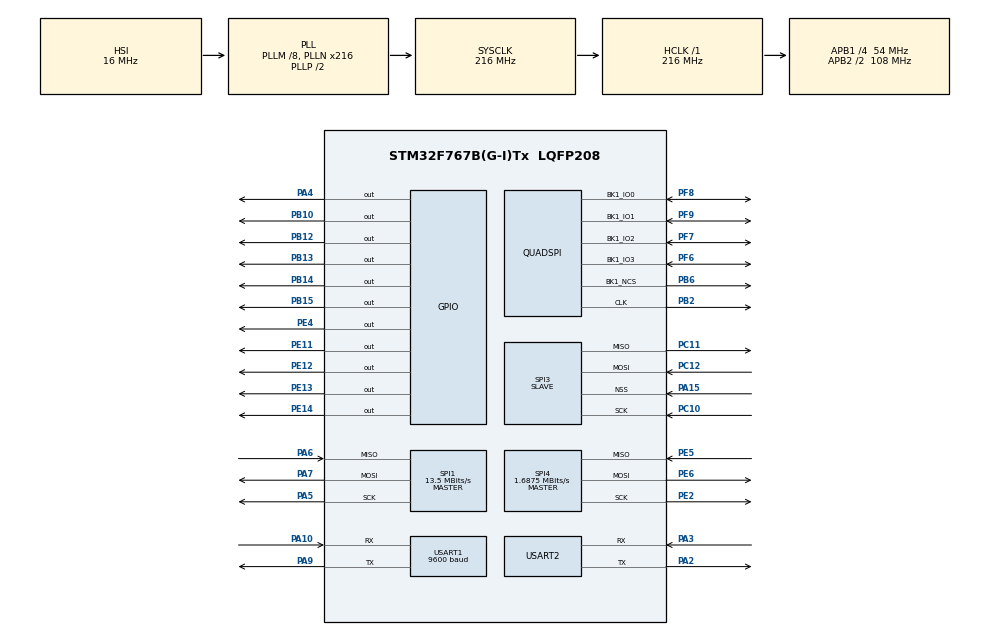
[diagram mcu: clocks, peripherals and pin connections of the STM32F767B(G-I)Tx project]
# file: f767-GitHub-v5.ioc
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CORTEX_M7.CPU_DCache=Enabled
CORTEX_M7.CPU_ICache=Enabled
Dma.Request0=USART1_RX
Dma.USART1_RX.0.Direction=DMA_PERIPH_TO_MEMORY
Dma.USART1_RX.0.FIFOMode=DMA_FIFOMODE_DISABLE
Dma.USART1_RX.0.Instance=DMA2_Stream5
Dma.USART1_RX.0.MemDataAlignment=DMA_MDATAALIGN_BYTE
Dma.USART1_RX.0.MemInc=DMA_MINC_ENABLE
Dma.USART1_RX.0.Mode=DMA_CIRCULAR
Dma.USART1_RX.0.PeriphDataAlignment=DMA_PDATAALIGN_BYTE
Dma.USART1_RX.0.PeriphInc=DMA_PINC_DISABLE
Dma.USART1_RX.0.Priority=DMA_PRIORITY_LOW
Mcu.Family=STM32F7
Mcu.Name=STM32F767B(G-I)Tx
Mcu.Package=LQFP208
NVIC.DMA2_Stream5_IRQn=true\:0\:0\:false\:false\:true\:false\:true\:true
NVIC.PriorityGroup=NVIC_PRIORITYGROUP_4
NVIC.USART1_IRQn=true\:0\:0\:false\:false\:true\:true\:true\:true
PA10.Mode=Asynchronous
PA10.Signal=USART1_RX
PA13.Mode=Serial_Wire
PA13.Signal=SYS_JTMS-SWDIO
PA14.Mode=Serial_Wire
PA14.Signal=SYS_JTCK-SWCLK
PA15.Mode=NSS_Signal_Hard_Input
PA15.Signal=SPI3_NSS
PA2.Mode=Asynchronous
PA2.Signal=USART2_TX
PA3.Mode=Asynchronous
PA3.Signal=USART2_RX
PA4.Signal=GPIO_Output
PA5.Mode=Full_Duplex_Master
PA5.Signal=SPI1_SCK
PA6.Mode=Full_Duplex_Master
PA6.Signal=SPI1_MISO
PA7.Mode=Full_Duplex_Master
PA7.Signal=SPI1_MOSI
PA9.Mode=Asynchronous
PA9.Signal=USART1_TX
PB10.Signal=GPIO_Output
PB12.Signal=GPIO_Output
PB13.Signal=GPIO_Output
PB14.Signal=GPIO_Output
PB15.Signal=GPIO_Output
PB2.Mode=Single Bank 1
PB2.Signal=QUADSPI_CLK
PB6.Mode=Single Bank 1
PB6.Signal=QUADSPI_BK1_NCS
PC10.Mode=Full_Duplex_Slave
PC10.Signal=SPI3_SCK
PC11.Mode=Full_Duplex_Slave
PC11.Signal=SPI3_MISO
PC12.Mode=Full_Duplex_Slave
PC12.Signal=SPI3_MOSI
PE11.Signal=GPIO_Output
PE12.Signal=GPIO_Output
PE13.Signal=GPIO_Output
PE14.Signal=GPIO_Output
PE2.Mode=Full_Duplex_Master
PE2.Signal=SPI4_SCK
PE4.Signal=GPIO_Output
PE5.Mode=Full_Duplex_Master
PE5.Signal=SPI4_MISO
PE6.Mode=Full_Duplex_Master
PE6.Signal=SPI4_MOSI
PF6.Mode=Single Bank 1
PF6.Signal=QUADSPI_BK1_IO3
PF7.Mode=Single Bank 1
PF7.Signal=QUADSPI_BK1_IO2
PF8.Mode=Single Bank 1
PF8.Signal=QUADSPI_BK1_IO0
PF9.Mode=Single Bank 1
PF9.Signal=QUADSPI_BK1_IO1
PH0/OSC_IN.Mode=HSE-External-Clock-Source
PH0/OSC_IN.Signal=RCC_OSC_IN
PH1/OSC_OUT.Mode=HSE-External-Clock-Source
PH1/OSC_OUT.Signal=RCC_OSC_OUT
ProjectManager.HeapSize=0x800
ProjectManager.StackSize=0x800
ProjectManager.TargetToolchain=STM32CubeIDE
RCC.AHBFreq_Value=216000000
RCC.APB1CLKDivider=RCC_HCLK_DIV4
RCC.APB1Freq_Value=54000000
RCC.APB1TimFreq_Value=108000000
RCC.APB2CLKDivider=RCC_HCLK_DIV2
RCC.APB2Freq_Value=108000000
RCC.APB2TimFreq_Value=216000000
RCC.CortexFreq_Value=216000000
RCC.HCLKFreq_Value=216000000
RCC.HSE_VALUE=8000000
RCC.HSI_VALUE=16000000
RCC.LSE_VALUE=32768
RCC.PLLM=8
RCC.PLLN=216
RCC.SYSCLKFreq_VALUE=216000000
RCC.SYSCLKSource=RCC_SYSCLKSOURCE_PLLCLK
RCC.USBFreq_Value=216000000
RCC.VCOOutputFreq_Value=432000000
SPI1.BaudRatePrescaler=SPI_BAUDRATEPRESCALER_8
SPI1.CalculateBaudRate=13.5 MBits/s
SPI1.DataSize=SPI_DATASIZE_8BIT
SPI1.Direction=SPI_DIRECTION_2LINES
SPI1.Mode=SPI_MODE_MASTER
SPI1.VirtualType=VM_MASTER
SPI3.Direction=SPI_DIRECTION_2LINES
SPI3.Mode=SPI_MODE_SLAVE
SPI3.VirtualNSS=VM_NSSHARD
SPI3.VirtualType=VM_SLAVE
SPI4.BaudRatePrescaler=SPI_BAUDRATEPRESCALER_64
SPI4.CalculateBaudRate=1.6875 MBits/s
SPI4.DataSize=SPI_DATASIZE_8BIT
SPI4.Direction=SPI_DIRECTION_2LINES
SPI4.Mode=SPI_MODE_MASTER
SPI4.VirtualType=VM_MASTER
STMicroelectronics.X-CUBE-AI.7.2.0.ActivationBufferSizeList=58432,128
STMicroelectronics.X-CUBE-AI.7.2.0.ActivationBuffers=pool0;pool0
STMicroelectronics.X-CUBE-AI.7.2.0.ActivationNames=pool0
STMicroelectronics.X-CUBE-AI.7.2.0.ActivationSizes=AI_NETWORK_DATA_ACTIVATION_1_SIZE
STMicroelectronics.X-CUBE-AI.7.2.0.HeapSize=0x800
STMicroelectronics.X-CUBE-AI.7.2.0.InternalRamActivationBufferMaxSize=AI_NETWORK_DATA_ACTIVATIONS_SIZE
STMicroelectronics.X-CUBE-AI.7.2.0.LatestDirectoryUsed-42ef4118f2b5a3766a18da1d4356868db262e7154a02415cbf3001b972654939=C\:\\Users\\yasir\\Documents
STMicroelectronics.X-CUBE-AI.7.2.0.LatestDirectoryUsed-c149c72ab2564b82c2436aeece4864a9ac483b8918643c00249937449eacca18=N\:\\BKB code\\ICU Code and Model\\ICU Code and Model
STMicroelectronics.X-CUBE-AI.7.2.0.MaximumNumberOfInputLayer=1
STMicroelectronics.X-CUBE-AI.7.2.0.MaximumNumberOfOutputLayer=1
STMicroelectronics.X-CUBE-AI.7.2.0.MaximumSizeOfInputLayer=1
STMicroelectronics.X-CUBE-AI.7.2.0.MaximumSizeOfOutputLayer=1
STMicroelectronics.X-CUBE-AI.7.2.0.ModelActualCompression-42ef4118f2b5a3766a18da1d4356868db262e7154a02415cbf3001b972654939=0.0
STMicroelectronics.X-CUBE-AI.7.2.0.ModelActualCompression-c149c72ab2564b82c2436aeece4864a9ac483b8918643c00249937449eacca18=0.0
STMicroelectronics.X-CUBE-AI.7.2.0.ModelCompression-42ef4118f2b5a3766a18da1d4356868db262e7154a02415cbf3001b972654939=None
STMicroelectronics.X-CUBE-AI.7.2.0.ModelCompression-c149c72ab2564b82c2436aeece4864a9ac483b8918643c00249937449eacca18=None
STMicroelectronics.X-CUBE-AI.7.2.0.ModelFlashOccupation-42ef4118f2b5a3766a18da1d4356868db262e7154a02415cbf3001b972654939=1284
STMicroelectronics.X-CUBE-AI.7.2.0.ModelFlashOccupation-c149c72ab2564b82c2436aeece4864a9ac483b8918643c00249937449eacca18=116
STMicroelectronics.X-CUBE-AI.7.2.0.ModelHashList=c149c72ab2564b82c2436aeece4864a9ac483b8918643c00249937449eacca18;42ef4118f2b5a3766a18da1d4356868db262e7154a02415cbf3001b972654939
STMicroelectronics.X-CUBE-AI.7.2.0.ModelKind-42ef4118f2b5a3766a18da1d4356868db262e7154a02415cbf3001b972654939=TFLITE
STMicroelectronics.X-CUBE-AI.7.2.0.ModelKind-c149c72ab2564b82c2436aeece4864a9ac483b8918643c00249937449eacca18=TFLITE
STMicroelectronics.X-CUBE-AI.7.2.0.ModelMacc-42ef4118f2b5a3766a18da1d4356868db262e7154a02415cbf3001b972654939=353
STMicroelectronics.X-CUBE-AI.7.2.0.ModelMacc-c149c72ab2564b82c2436aeece4864a9ac483b8918643c00249937449eacca18=422420
STMicroelectronics.X-CUBE-AI.7.2.0.ModelName-42ef4118f2b5a3766a18da1d4356868db262e7154a02415cbf3001b972654939=sine_model
STMicroelectronics.X-CUBE-AI.7.2.0.ModelName-c149c72ab2564b82c2436aeece4864a9ac483b8918643c00249937449eacca18=network
STMicroelectronics.X-CUBE-AI.7.2.0.ModelNameList=network,sine_model
STMicroelectronics.X-CUBE-AI.7.2.0.ModelRamOccupation-42ef4118f2b5a3766a18da1d4356868db262e7154a02415cbf3001b972654939=128
STMicroelectronics.X-CUBE-AI.7.2.0.ModelRamOccupation-c149c72ab2564b82c2436aeece4864a9ac483b8918643c00249937449eacca18=58432
STMicroelectronics.X-CUBE-AI.7.2.0.ModelStructureFile-42ef4118f2b5a3766a18da1d4356868db262e7154a02415cbf3001b972654939=C\:\\Users\\yasir\\Documents\\sine_model.tflite
STMicroelectronics.X-CUBE-AI.7.2.0.ModelStructureFile-c149c72ab2564b82c2436aeece4864a9ac483b8918643c00249937449eacca18=N\:\\BKB code\\ICU Code and Model\\ICU Code and Model\\MobileNetV2_Binary.tflite
STMicroelectronics.X-CUBE-AI.7.2.0.ModelType-42ef4118f2b5a3766a18da1d4356868db262e7154a02415cbf3001b972654939=STM32Cube.AI runtime
STMicroelectronics.X-CUBE-AI.7.2.0.ModelType-c149c72ab2564b82c2436aeece4864a9ac483b8918643c00249937449eacca18=STM32Cube.AI runtime
STMicroelectronics.X-CUBE-AI.7.2.0.ReadyForCodeGeneration=true
STMicroelectronics.X-CUBE-AI.7.2.0.StackSize=0x800
STMicroelectronics.X-CUBE-AI.7.2.0.WorkingBufferStartAddrList=0xFFFFFFFF,0xFFFFFFFF
STMicroelectronics.X-CUBE-AI.7.2.0.XAaCUBEAaAICcArtificialOoIntelligenceJjCore=true
TIM13.Prescaler=79
TIM14.Prescaler=79
USART1.BaudRate=9600
USART1.VirtualMode-Asynchronous=VM_ASYNC
USART2.VirtualMode-Asynchronous=VM_ASYNC
VP_CRC_VS_CRC.Mode=CRC_Activate
VP_STMicroelectronics.X-CUBE-AI_VS_ArtificialOoIntelligenceJjXAaCUBEAaAI_7.2.0.Mode=ArtificialOoIntelligenceJjXAaCUBEAaAI
VP_TIM13_VS_ClockSourceINT.Mode=Enable_Timer
VP_TIM14_VS_ClockSourceINT.Mode=Enable_Timer
board=custom

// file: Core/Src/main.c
/* USER CODE BEGIN Header */
/**
  ******************************************************************************
  * @file           : main.c
  * @brief          : Main program body
  ******************************************************************************
  * @attention
  *
  * <h2><center>&copy; Copyright (c) 2020 STMicroelectronics.
  * All rights reserved.</center></h2>
  *
  * This software component is licensed by ST under BSD 3-Clause license,
  * the "License"; You may not use this file except in compliance with the
  * License. You may obtain a copy of the License at:
  *                        opensource.org/licenses/BSD-3-Clause
  *
  ******************************************************************************
  */
/* USER CODE END Header */
#include "main.h"
#include "crc.h"
#include "dma.h"
#include "quadspi.h"
#include "spi.h"
#include "tim.h"
#include "usart.h"
#include "gpio.h"

/* USER CODE BEGIN Includes */
#include "ai_datatypes_defines.h"
#include "ai_platform.h"

#include "network_data.h"
#include "network.h"

#include "sine_model.h"
#include "sine_model_data.h"

#include <math.h>
#include "string.h"
#include <stdio.h>
#include <assert.h>

#include "w25qxx.h"
#include "w25qxxConf.h"

#include "..\\tjpg\\tjpgd.h"

/* USER CODE END Includes */

/* USER CODE BEGIN PD */
#define serialPortDebug huart1
#define serialPortCAM huart1
#define shrdPortFM hspi4
#define localPortFM hspi4

#define debugPort huart1
#define serialCAM huart3
#define N_BPP (3 - JD_FORMAT)

/* USER CODE END PD */

/* USER CODE BEGIN PM */

//#ifdef __GNUC__
//  #define PUTCHAR_PROTOTYPE int __io_putchar(int ch)
//#else
//  #define PUTCHAR_PROTOTYPE int fputc(int ch, FILE *f)
//#endif
//
//PUTCHAR_PROTOTYPE
//{
//  HAL_UART_Transmit(&serialPortDebug,(uint8_t *)&ch,1,0xFFFF);//Blocking mode printing
//  return ch;
//}

void write_3ByteAdd_FM(SPI_HandleTypeDef spiPort, uint32_t Addr, uint8_t writeDataByte);
//void write_3ByteAdd_FM(SPI_HandleTypeDef spiPort, uint32_t Addr);
int read_3ByteAdd_FM(SPI_HandleTypeDef spiPort, uint32_t Addr);
/* USER CODE END PM */

/* USER CODE BEGIN PV */

#if 1 /* FOLDED ARRAY */

////Earth 320x240
uint8_t Earth[16155] = {
		0xFF, 0xD8, 0xFF, 0xE0, 0x00, 0x10, 0x4A, 0x46, 0x49, 0x46, 0x00, 0x01, 0x01, 0x00, 0x00, 0x01,
		0x00, 0x01, 0x00, 0x00, 0xFF, 0xDB, 0x00, 0x43, 0x00, 0x08, 0x06, 0x06, 0x07, 0x06, 0x05, 0x08,
		0x07, 0x07, 0x07, 0x09, 0x09, 0x08, 0x0A, 0x0C, 0x14, 0x0D, 0x0C, 0x0B, 0x0B, 0x0C, 0x19, 0x12,
		0x13, 0x0F, 0x14, 0x1D, 0x1A, 0x1F, 0x1E, 0x1D, 0x1A, 0x1C, 0x1C, 0x20, 0x24, 0x2E, 0x27, 0x20,
		0x22, 0x2C, 0x23, 0x1C, 0x1C, 0x28, 0x37, 0x29, 0x2C, 0x30, 0x31, 0x34, 0x34, 0x34, 0x1F, 0x27,
		0x39, 0x3D, 0x38, 0x32, 0x3C, 0x2E, 0x33, 0x34, 0x32, 0xFF, 0xDB, 0x00, 0x43, 0x01, 0x09, 0x09,
		0x09, 0x0C, 0x0B, 0x0C, 0x18, 0x0D, 0x0D, 0x18, 0x32, 0x21, 0x1C, 0x21, 0x32, 0x32, 0x32, 0x32,
		0x32, 0x32, 0x32, 0x32, 0x32, 0x32, 0x32, 0x32, 0x32, 0x32, 0x32, 0x32, 0x32, 0x32, 0x32, 0x32,
		0x32, 0x32, 0x32, 0x32, 0x32, 0x32, 0x32, 0x32, 0x32, 0x32, 0x32, 0x32, 0x32, 0x32, 0x32, 0x32,
		0x32, 0x32, 0x32, 0x32, 0x32, 0x32, 0x32, 0x32, 0x32, 0x32, 0x32, 0x32, 0x32, 0x32, 0xFF, 0xC0,
		0x00, 0x11, 0x08, 0x00, 0xF0, 0x01, 0x40, 0x03, 0x01, 0x22, 0x00, 0x02, 0x11, 0x01, 0x03, 0x11,
		0x01, 0xFF, 0xC4, 0x00, 0x1C, 0x00, 0x00, 0x02, 0x02, 0x03, 0x01, 0x01, 0x00, 0x00, 0x00, 0x00,
		0x00, 0x00, 0x00, 0x00, 0x00, 0x00, 0x00, 0x05, 0x04, 0x06, 0x02, 0x03, 0x07, 0x01, 0x08, 0xFF,
		0xC4, 0x00, 0x42, 0x10, 0x00, 0x02, 0x01, 0x03, 0x03, 0x02, 0x05, 0x01, 0x05, 0x06, 0x05, 0x04,
		0x01, 0x02, 0x07, 0x00, 0x01, 0x02, 0x03, 0x00, 0x04, 0x11, 0x05, 0x12, 0x21, 0x31, 0x41, 0x06,
		0x13, 0x22, 0x51, 0x61, 0x71, 0x14, 0x32, 0x81, 0x91, 0xA1, 0x07, 0x15, 0x23, 0x42, 0xB1, 0xC1,
		0x33, 0x52, 0x62, 0xE1, 0xF0, 0x24, 0x72, 0xD1, 0xF1, 0x08, 0x43, 0x53, 0x16, 0x35, 0x63, 0x73,
		0x82, 0x92, 0xA2, 0xFF, 0xC4, 0x00, 0x19, 0x01, 0x00, 0x03, 0x01, 0x01, 0x01, 0x00, 0x00, 0x00,
		0x00, 0x00, 0x00, 0x00, 0x00, 0x00, 0x00, 0x00, 0x00, 0x02, 0x03, 0x01, 0x04, 0x05, 0xFF, 0xC4,
		0x00, 0x26, 0x11, 0x00, 0x02, 0x02, 0x02, 0x02, 0x01, 0x04, 0x02, 0x03, 0x01, 0x00, 0x00, 0x00,
		0x00, 0x00, 0x00, 0x00, 0x01, 0x02, 0x11, 0x03, 0x21, 0x12, 0x31, 0x41, 0x04, 0x13, 0x32, 0x61,
		0x22, 0x51, 0x23, 0x71, 0xC1, 0xF0, 0xFF, 0xDA, 0x00, 0x0C, 0x03, 0x01, 0x00, 0x02, 0x11, 0x03,
		0x11, 0x00, 0x3F, 0x00, 0xA6, 0x4E, 0xBC, 0x07, 0x03, 0x83, 0xD2, 0xA3, 0xC8, 0x86, 0x30, 0xC2,
		0x4C, 0xAB, 0x01, 0x90, 0xA4, 0x63, 0x34, 0xCE, 0xEA, 0xE2, 0x7B, 0xE4, 0x16, 0xE9, 0x24, 0x9F,
		0x67, 0xB6, 0x07, 0xC8, 0x87, 0x76, 0x55, 0x06, 0x79, 0xFC, 0x4E, 0x7A, 0xF7, 0xA5, 0x13, 0xAB,
		0xAB, 0x11, 0x20, 0x21, 0xBD, 0x8D, 0x6C, 0x49, 0x9A, 0x73, 0x8A, 0xCE, 0x39, 0xE4, 0x8C, 0x10,
		0x8C, 0x54, 0x1E, 0xB8, 0x3D, 0x6B, 0x58, 0x56, 0x3D, 0x14, 0x9A, 0xC7, 0x95, 0x24, 0x11, 0x83,
		0xED, 0x5A, 0xD2, 0x7D, 0x9A, 0x38, 0x86, 0xF8, 0xC5, 0x69, 0xB8, 0x4E, 0x18, 0x83, 0xF7, 0x08,
		0xEC, 0x7A, 0xD6, 0xA1, 0xA8, 0xB4, 0x84, 0x99, 0x10, 0x1F, 0x9C, 0x9A, 0x53, 0x8C, 0x77, 0xA0,
		0x31, 0x15, 0x2F, 0x66, 0x37, 0x63, 0x72, 0x97, 0x86, 0x3E, 0x4B, 0xE8, 0x98, 0xB3, 0x34, 0x5B,
		0x98, 0xF5, 0xEF, 0x5A, 0xF5, 0x16, 0xDF, 0x10, 0x23, 0x03, 0x8E, 0x98, 0xA5, 0x29, 0x3B, 0x29,
		0x38, 0xA9, 0x3F, 0x6B, 0xF3, 0x21, 0x28, 0xD8, 0xE0, 0x70, 0x6B, 0x16, 0x2A, 0x76, 0x64, 0xA7,
		0x29, 0x76, 0x46, 0x0E, 0x3B, 0xD6, 0xC8, 0x6E, 0x5E, 0x10, 0x55, 0x58, 0xED, 0x3D, 0xBD, 0xEA,
		0x19, 0x6E, 0x6B, 0xD0, 0xD5, 0xD1, 0x42, 0x8E, 0xAC, 0xEE, 0x37, 0x5D, 0x79, 0x92, 0x31, 0xE9,
		0x80, 0x33, 0xC0, 0xA7, 0x3E, 0x1F, 0xF1, 0x1C, 0xDE, 0x1A, 0xF1, 0x05, 0xB5, 0xFC, 0x6C, 0x1A,
		0x02, 0xDB, 0x65, 0x4C, 0xF0, 0xCA, 0x7A, 0xD5, 0x38, 0x4B, 0x9E, 0xF8, 0xAD, 0xE6, 0x5D, 0xC8,
		0xCA, 0x7A, 0x56, 0x3C, 0x49, 0xF6, 0x65, 0x9F, 0x52, 0x3E, 0xB9, 0x6F, 0x2E, 0x9C, 0xFA, 0x9D,
		0x95, 0xDC, 0x53, 0x40, 0x88, 0x92, 0xBC, 0x79, 0x19, 0x55, 0x3F, 0xD0, 0x9A, 0x61, 0xA5, 0xEA,
		0x31, 0xEA, 0x96, 0x29, 0x73, 0x10, 0x2A, 0x18, 0x72, 0xA7, 0xF9, 0x4F, 0x71, 0x5F, 0x33, 0xE8,
		0x7A, 0xED, 0xCD, 0x89, 0xB9, 0x89, 0x64, 0x3B, 0x6E, 0x20, 0x11, 0x3F, 0xB1, 0x5C, 0x8E, 0x3F,
		0x4A, 0xBB, 0x78, 0x53, 0xC7, 0xD7, 0x9A, 0x4D, 0xC1, 0xB3, 0xD4, 0x17, 0x7D, 0x9C, 0x98, 0x0B,
		0x2A, 0x0E, 0x63, 0xFF, 0x00, 0x56, 0x3A, 0x1F, 0x9A, 0xE7, 0xE1, 0x38, 0x49, 0xFE, 0x86, 0xF7,
		0x17, 0x47, 0x67, 0x8E, 0xD2, 0x28, 0xC3, 0x85, 0x51, 0xB5, 0xDB, 0x79, 0x5E, 0xC0, 0xFC, 0x57,
		0x24, 0xF1, 0x2F, 0x83, 0x6F, 0xA0, 0xBB, 0xBE, 0x6B, 0x38, 0x19, 0xAD, 0xC3, 0x17, 0x40, 0x06,
		0x70, 0xA7, 0xA7, 0xEB, 0xC5, 0x74, 0xBB, 0x3D, 0x4A, 0xE3, 0x7B, 0x35, 0xE2, 0x44, 0xB6, 0xF2,
		0x7A, 0xA0, 0x9D, 0x5B, 0xD2, 0xC0, 0xF4, 0x06, 0x9A, 0x6E, 0x57, 0x07, 0x69, 0x56, 0xEA, 0xBD,
		0x7B, 0xFB, 0x56, 0xAA, 0x7B, 0x43, 0x35, 0x67, 0xCB, 0x6A, 0x7C, 0xB7, 0x78, 0xE5, 0x0C, 0xAC,
		0x3D, 0xC6, 0x30, 0x6B, 0xC1, 0x21, 0x53, 0x8C, 0xFC, 0x83, 0x5D, 0x3B, 0xF6, 0x83, 0xE1, 0x60,
		0xF7, 0xB7, 0x9A, 0xAC, 0x50, 0x48, 0xA5, 0xB6, 0xE0, 0xA8, 0x04, 0x16, 0xC7, 0x3C, 0x7D, 0x2B,
		0x9A, 0xDC, 0x98, 0x25, 0x82, 0x37, 0x8C, 0x91, 0x38, 0xC2, 0xC9, 0x19, 0x1C, 0x93, 0xEE, 0x2B,
		0xAE, 0x0D, 0x4B, 0xA2, 0x4E, 0xD1, 0x62, 0xF0, 0xEF, 0x89, 0x6E, 0xB4, 0x5D, 0x45, 0x27, 0x49,
		0x5E, 0x48, 0x18, 0xFF, 0x00, 0x16, 0x2C, 0xE7, 0x7A, 0xF7, 0xC7, 0xCD, 0x5A, 0x6D, 0xBC, 0x5D,
		0xAA, 0xE9, 0xD7, 0x4E, 0xC9, 0x3B, 0xDD, 0x59, 0x23, 0x99, 0x12, 0x09, 0x10, 0x67, 0xC8, 0x3D,
		0x18, 0x30, 0xE4, 0xE3, 0x3C, 0xD7, 0x32, 0x85, 0xCB, 0x23, 0x0E, 0x3D, 0x3C, 0xD5, 0xDB, 0xC3,
		0xB2, 0xC3, 0x7D, 0x67, 0xF6, 0x3B, 0x89, 0x76, 0x1D, 0xDF, 0xC1, 0x99, 0x78, 0x68, 0x98, 0xFC,
		0xFB, 0x1E, 0x01, 0x1F, 0x35, 0x3C, 0x98, 0x62, 0xBF, 0x2A, 0x36, 0x33, 0x7D, 0x1D, 0x97, 0x4E,
		0xD4, 0x2D, 0xF5, 0x4B, 0x28, 0xEE, 0xAD, 0x9C, 0x32, 0x38, 0xCF, 0x5E, 0x47, 0xC1, 0xA9, 0x55,
		0xC4, 0xB4, 0x5F, 0x13, 0x5E, 0xF8, 0x37, 0x52, 0x36, 0xB3, 0x93, 0x3D, 0x89, 0x6C, 0x90, 0x07,
		0x63, 0xED, 0xED, 0xF4, 0xAE, 0xD3, 0x04, 0xF1, 0xDC, 0xDB, 0xC7, 0x3C, 0x4D, 0xBA, 0x39, 0x14,
		0x3A, 0x9F, 0x70, 0x7A, 0x52, 0x34, 0xE3, 0xA6, 0x3C, 0x5D, 0xA3, 0x65, 0x25, 0xD4, 0xB4, 0x90,
		0xF7, 0xD1, 0xEA, 0x36, 0xEA, 0x3C, 0xF4, 0x52, 0x8E, 0xB8, 0xE2, 0x55, 0x3D, 0x41, 0xFF, 0x00,
		0x9E, 0xD4, 0xEA, 0x8A, 0x0D, 0x6A, 0xCF, 0x9D, 0x7F, 0x6C, 0x1E, 0x11, 0x16, 0xEA, 0x2F, 0x2D,
		0x63, 0x6F, 0x24, 0x2E, 0xF8, 0xDB, 0xDD, 0x7B, 0x8F, 0xC2, 0xB8, 0x7D, 0x7D, 0xB9, 0xE2, 0x3D,
		0x09, 0x35, 0xBD, 0x22, 0xE6, 0xCE, 0x40, 0x08, 0x23, 0x7C, 0x5C, 0x74, 0x3D, 0xC5, 0x7C, 0x71,
		0xAF, 0x69, 0xAF, 0xA5, 0x6B, 0x17, 0x16, 0xCC, 0xA4, 0x00, 0xC7, 0x6F, 0xD2, 0xBA, 0x66, 0xFD,
		0xDC, 0x6A, 0x7E, 0x56, 0x9F, 0xF8, 0x47, 0x1A, 0xE1, 0x37, 0x0F, 0x0F, 0x6B, 0xFD, 0x15, 0x51,
		0x45, 0x15, 0xCC, 0x5C, 0x28, 0xA2, 0x8A, 0x00, 0x28, 0xA2, 0x8A, 0x00, 0x28, 0xA2, 0x8A, 0x00,
		0x28, 0xA2, 0x8A, 0x00, 0x28, 0xA2, 0x8A, 0x00, 0x28, 0xA2, 0x8A, 0x00, 0xED, 0x9A, 0x2A, 0x0B,
		0x40, 0xB7, 0x13, 0xC7, 0x6A, 0xD1, 0x24, 0x6D, 0x2E, 0xF2, 0xE7, 0x72, 0x1E, 0x80, 0x15, 0xFF,
		0x00, 0x36, 0x46, 0x07, 0xD6, 0x91, 0x5C, 0x0F, 0xB7, 0xCE, 0xD3, 0x13, 0x83, 0xD3, 0x0D, 0xC6,
		0xEC, 0x0F, 0x7A, 0x99, 0x7C, 0x27, 0xB0, 0x09, 0x6B, 0x23, 0x44, 0x26, 0x4C, 0xAB, 0xAA, 0xB8,
		0x6E, 0x3A, 0x8E, 0x47, 0x6E, 0x7D, 0xFD, 0xEB, 0x38, 0x88, 0xFB, 0x2E, 0xF6, 0x43, 0xB5, 0xB2,
		0x3D, 0x39, 0xC0, 0x38, 0xC7, 0xF4, 0x39, 0xF7, 0xE2, 0x95, 0x7E, 0xC9, 0xA1, 0x7D, 0xC5, 0xFC,
		0x90, 0xDB, 0x1B, 0x54, 0x60, 0x22, 0x38, 0x65, 0x8E, 0x33, 0x84, 0x07, 0xB9, 0x60, 0x73, 0x96,
		0x38, 0x14, 0x99, 0xD8, 0x96, 0x2C, 0x7A, 0x93, 0x4E, 0xB5, 0x38, 0xFC, 0xB7, 0x18, 0xCB, 0x45,
		0x22, 0x83, 0x1B, 0xB6, 0x37, 0x1E, 0x39, 0xC8, 0x19, 0xEF, 0x59, 0x5A, 0x68, 0x22, 0x60, 0xF7,
		0xD3, 0x3E, 0xDD, 0x22, 0x39, 0x0C, 0x6D, 0x74, 0x58, 0x28, 0x24, 0x2E, 0xED, 0xA0, 0x1E, 0x77,
		0x11, 0x9C, 0x0C, 0x73, 0x55, 0x5D, 0x1A, 0x21, 0x66, 0x2C, 0x49, 0x38, 0xFC, 0x2B, 0x10, 0x7A,
		0xD4, 0xAD, 0x4E, 0xE6, 0x3B, 0xAB, 0xF9, 0x5E, 0x04, 0x0B, 0x00, 0x3B, 0x62, 0x01, 0x02, 0x9D,
		0xA3, 0x80, 0x48, 0xF7, 0x23, 0x93, 0xF5, 0xA8, 0x24, 0xF3, 0x5A, 0x61, 0x96, 0x73, 0x40, 0x6C,
		0x56, 0xBC, 0xD0, 0x4D, 0x6D, 0x01, 0x99, 0x35, 0x86, 0x71, 0x5E, 0x67, 0x15, 0xE6, 0x69, 0x90,
		0xA6, 0x5B, 0xB1, 0x59, 0xAB, 0xD6, 0x8C, 0xD7, 0xA2, 0x98, 0x52, 0x64, 0x32, 0x6D, 0x60, 0x6A,
		0xCB, 0xA7, 0xDC, 0xAD, 0xCC, 0x06, 0x26, 0x03, 0x7A, 0xFD, 0xC2, 0x7F, 0xA5, 0x56, 0x2D, 0x86,
		0x4D, 0x38, 0xB0, 0x04, 0x49, 0xED, 0x8E, 0x71, 0x9A, 0xC9, 0x2B, 0x42, 0xBD, 0x96, 0x9B, 0x2F,
		0x15, 0x6B, 0x9A, 0x10, 0x10, 0x6E, 0xF3, 0xEC, 0x59, 0x58, 0x0B, 0x79, 0xBD, 0x68, 0x41, 0xFE,
		0x98, 0xED, 0x56, 0x7D, 0x37, 0xF6, 0x9D, 0x32, 0xAC, 0x6D, 0x2D, 0xBA, 0x46, 0xCD, 0x72, 0x86,
		0xE5, 0xB6, 0xFA, 0x76, 0x63, 0x04, 0xA8, 0xF7, 0xE9, 0xF9, 0x55, 0x2A, 0xD6, 0x52, 0xDB, 0x95,
		0x86, 0x46, 0x3A, 0x7B, 0x54, 0x0B, 0x97, 0x11, 0x40, 0x8B, 0xB7, 0xD4, 0x1C, 0x91, 0x8E, 0xA0,
		0xFB, 0xD7, 0x2F, 0x15, 0xD7, 0x90, 0x8C, 0xE4, 0x7D, 0x1D, 0x79, 0xF6, 0x4D, 0x7F, 0x40, 0x95,
		0x95, 0x81, 0x86, 0x44, 0x2C, 0x8F, 0xFE, 0x52, 0x3A, 0x37, 0xC5, 0x70, 0x4D, 0x5E, 0xD6, 0xF3,
		0x40, 0xD7, 0x8C, 0xD1, 0x0C, 0x5C, 0x5A, 0xCA, 0x92, 0xAF, 0x70, 0x47, 0x0C, 0x2A, 0xC3, 0xE0,
		0xAF, 0xDA, 0x3D, 0xA6, 0x97, 0x66, 0xDA, 0x66, 0xB1, 0x14, 0x92, 0x44, 0xEC, 0x06, 0xE8, 0xC6,
		0x40, 0x07, 0xA9, 0x23, 0xFF, 0x00, 0x15, 0x7C, 0xD6, 0xFC, 0x33, 0xA7, 0x78, 0xA7, 0x4D, 0x4B,
		0xCD, 0x2A, 0x58, 0x5A, 0x56, 0x41, 0xE5, 0xC8, 0x1B, 0x2A, 0xE8, 0x38, 0x03, 0xE3, 0x8A, 0x6C,
		0x53, 0xE2, 0xEA, 0x45, 0x64, 0xB9, 0x23, 0x87, 0xEA, 0x13, 0x09, 0x75, 0x39, 0x6E, 0x12, 0x34,
		0x88, 0x4A, 0xDE, 0x60, 0x44, 0x1C, 0x0C, 0xF3, 0xC5, 0x6E, 0xB4, 0xBC, 0xFB, 0x24, 0xAD, 0xB9,
		0x0B, 0x21, 0xC6, 0x46, 0x71, 0x53, 0x75, 0xFF, 0x00, 0x0E, 0xDF, 0xE9, 0x2E, 0x12, 0xEA, 0x32,
		0xBB, 0x77, 0x20, 0x6F, 0xA7, 0x20, 0x7E, 0x46, 0x92, 0x89, 0x37, 0xC7, 0x2B, 0x49, 0xF7, 0xD7,
		0x9F, 0xC2, 0xBB, 0xD2, 0x52, 0x47, 0x33, 0x93, 0x4C, 0xBD, 0xDD, 0x5C, 0xD9, 0xEB, 0xDA, 0x6B,
		0xCA, 0x87, 0xFE, 0xB6, 0x22, 0xAC, 0x30, 0x3E, 0xFA, 0x91, 0x87, 0xE3, 0xDF, 0x20, 0x1A, 0x95,
		0xE0, 0xAF, 0x12, 0xC9, 0xA0, 0x6A, 0xEB, 0xA7, 0x4F, 0x2C, 0xB3, 0xE9, 0xD7, 0x67, 0xD3, 0xB8,
		0xE7, 0xC9, 0x7C, 0x76, 0xCF, 0x6A, 0xA6, 0x25, 0xD3, 0xD9, 0x5F, 0x33, 0x5A, 0x31, 0x45, 0x0C,
		0x0A, 0x12, 0x79, 0xE9, 0x57, 0x04, 0xB5, 0x87, 0x55, 0xD3, 0x66, 0xBB, 0x8D, 0xE1, 0x12, 0x1C,
		0x48, 0xD1, 0xA8, 0xC1, 0x8E, 0x40, 0x79, 0x2B, 0xF0, 0x7A, 0xFC, 0x66, 0xA3, 0x28, 0x25, 0x1A,
		0x63, 0xC7, 0x25, 0xBD, 0x1D, 0xA4, 0x1C, 0x8E, 0x2B, 0xCA, 0xA9, 0x78, 0x0F, 0x51, 0xB8, 0xB9,
		0xD2, 0xDE, 0xD2, 0xE1, 0xCB, 0xB5, 0xB9, 0xDA, 0x8C, 0xDF, 0x7B, 0x6F, 0xB1, 0xF7, 0xC5, 0x5B,
		0x49, 0x0A, 0x09, 0x3D, 0x05, 0x73, 0x1D, 0x49, 0xDA, 0xB0, 0xAF, 0x9C, 0xBF, 0x6D, 0xDE, 0x12,
		0x6B, 0x3B, 0xCF, 0xDE, 0xB0, 0xA8, 0x31, 0xBB, 0x64, 0xE0, 0x74, 0x07, 0xFD, 0xF3, 0x5F, 0x46,
		0x02, 0x18, 0x64, 0x10, 0x41, 0x19, 0x04, 0x77, 0xA4, 0x7E, 0x2B, 0xF0, 0xFC, 0x5E, 0x25, 0xD0,
		0xEE, 0x34, 0xF9, 0x00, 0x0D, 0x22, 0x15, 0x56, 0xF6, 0x3D, 0xBF, 0x5C, 0x55, 0xB0, 0x4D, 0x45,
		0xB8, 0xCB, 0xA7, 0xA2, 0x79, 0x63, 0x69, 0x49, 0x76, 0x8F, 0x88, 0xE8, 0xA9, 0x9A, 0x8D, 0x94,
		0x9A, 0x76, 0xA1, 0x3D, 0xA4, 0xCA, 0x56, 0x48, 0x9C, 0xA3, 0x02, 0x3A, 0x10, 0x6A, 0x1D, 0x4A,
		0x51, 0xE2, 0xE9, 0x94, 0x4E, 0xD5, 0xA0, 0xA2, 0x8A, 0x2B, 0x0D, 0x0A, 0x28, 0xA2, 0x80, 0x0A,
		0x28, 0xA2, 0x80, 0x0A, 0x28, 0xA2, 0x80, 0x0A, 0x28, 0xA2, 0x80, 0x0A, 0x28, 0xA2, 0x80, 0x3A,
		0x64, 0x8D, 0xE6, 0x42, 0x80, 0x81, 0xBA, 0x30, 0x59, 0xB7, 0x0C, 0x12, 0x4F, 0x6E, 0x9F, 0xF3,
		0x35, 0x36, 0xD6, 0xE4, 0x47, 0x16, 0x19, 0x72, 0x82, 0x2C, 0xEE, 0x04, 0x67, 0x39, 0xE0, 0x8C,
		0xF5, 0x3F, 0x1E, 0xD9, 0xA5, 0x49, 0x80, 0x51, 0x4E, 0x43, 0x1E, 0x7E, 0xBE, 0xC3, 0x9E, 0x94,
		0xCA, 0x46, 0x1E, 0x98, 0xE5, 0x05, 0x43, 0x1D, 0xAD, 0x9C, 0xE1, 0x47, 0x03, 0xAE, 0x72, 0x70,
		0x4F, 0xCF, 0xF5, 0xA6, 0x11, 0x1E, 0xCC, 0xA9, 0x34, 0xD1, 0x23, 0x49, 0x1A, 0x99, 0xD1, 0x19,
		0x9B, 0x61, 0xC4, 0x59, 0x3C, 0x8C, 0x01, 0xD8, 0x0C, 0xF7, 0xA8, 0x3A, 0xC5, 0xD1, 0xBC, 0x9A,
		0x28, 0xED, 0xE3, 0x8D, 0x20, 0x40, 0x22, 0x8D, 0x62, 0x8F, 0x60, 0x72, 0x38, 0xDD, 0xF2, 0x4F,
		0x5C, 0xF5, 0xE7, 0x9A, 0x74, 0xF1, 0x5C, 0xF8, 0x8B, 0x59, 0xE1, 0x91, 0x5A, 0xE2, 0x78, 0xE2,
		0x88, 0x96, 0x0B, 0xE5, 0x46, 0xA9, 0xD4, 0x02, 0x78, 0xF4, 0x2E, 0x73, 0xDA, 0xA2, 0x69, 0xD7,
		0x10, 0x4B, 0x7D, 0x14, 0x73, 0x21, 0x7D, 0x23, 0x4E, 0x69, 0xAE, 0x38, 0x24, 0x19, 0x39, 0xE1,
		0x89, 0x53, 0xD4, 0xE1, 0x06, 0x46, 0x3A, 0xD3, 0xA4, 0x8C, 0x14, 0xEB, 0x7A, 0x59, 0xD1, 0xF5,
		0x59, 0xAC, 0x1E, 0x42, 0xCF, 0x00, 0x45, 0x97, 0xD1, 0x8D, 0x8E, 0x54, 0x16, 0x53, 0xC9, 0xCE,
		0x09, 0xC6, 0x7B, 0xD2, 0xCB, 0xA7, 0x12, 0xC8, 0x19, 0x54, 0x2A, 0xED, 0x00, 0x00, 0x00, 0xE8,
		0x31, 0xDA, 0x9F, 0xC9, 0x70, 0x75, 0x7B, 0xFD, 0x53, 0x59, 0xD5, 0x1C, 0xDB, 0x8B, 0xA8, 0xE6,
		0x95, 0x76, 0xA6, 0x43, 0xCB, 0xC6, 0x10, 0x67, 0xEA, 0x39, 0xA4, 0x30, 0xC6, 0xCC, 0x64, 0x3E,
		0x90, 0x11, 0x72, 0x73, 0xD4, 0x0F, 0x70, 0x28, 0x02, 0x3E, 0x6B, 0x1D, 0xD5, 0xE1, 0xE1, 0x8D,
		0x18, 0x24, 0x64, 0x0E, 0x95, 0xA6, 0x1E, 0xE6, 0xB1, 0xCD, 0x15, 0xE5, 0x30, 0xAC, 0xCA, 0xBD,
		0x03, 0x24, 0x56, 0x51, 0xA1, 0x90, 0x0D, 0xA0, 0x9C, 0x75, 0xC5, 0x78, 0x38, 0xE0, 0x0C, 0xE2,
		0x98, 0x41, 0xAE, 0x98, 0xB1, 0x82, 0x43, 0xF7, 0x18, 0x07, 0xE6, 0x98, 0xDA, 0xB7, 0x97, 0x7C,
		0xA3, 0x86, 0x04, 0x72, 0x69, 0x35, 0xA0, 0x77, 0xE4, 0xE7, 0x19, 0xC8, 0x20, 0x74, 0xA7, 0xD6,
		0x56, 0x8D, 0x34, 0x1E, 0x72, 0x24, 0xBE, 0x60, 0xF5, 0x06, 0xD9, 0xB5, 0x70, 0x08, 0xCE, 0x3D,
		0xCD, 0x63, 0x74, 0xAC, 0xC6, 0xF4, 0x6D, 0x47, 0x36, 0xB3, 0x19, 0x1C, 0xED, 0x5C, 0x67, 0xAF,
		0x6A, 0x59, 0x3D, 0xCB, 0xCB, 0x72, 0xC4, 0x90, 0x40, 0x3E, 0x9E, 0x7A, 0x8A, 0xDF, 0x38, 0x37,
		0x41, 0xD9, 0xC9, 0x48, 0x93, 0xA1, 0x23, 0xBF, 0x6C, 0x9E, 0x95, 0x10, 0xDA, 0x6D, 0xF4, 0xEE,
		0x19, 0xF8, 0x04, 0xE7, 0x9E, 0xDC, 0x54, 0x2A, 0xDD, 0xB3, 0x62, 0x9A, 0x54, 0x0C, 0x04, 0x8A,
		0xC7, 0x6F, 0xB7, 0x3D, 0xC5, 0x3F, 0xF0, 0xCF, 0x8A, 0xEF, 0xFC, 0x2D, 0x3A, 0xC8, 0xBB, 0xE6,
		0xB4, 0x27, 0xD5, 0x19, 0x3C, 0xA9, 0xEE, 0x57, 0xFF, 0x00, 0x1D, 0x0D, 0x22, 0x36, 0xF8, 0x8F,
		0x70, 0x27, 0xF2, 0xA9, 0x76, 0x88, 0x27, 0x59, 0x62, 0x7E, 0x54, 0xE3, 0x38, 0xE4, 0x8F, 0x90,
		0x3B, 0xD3, 0xD2, 0x7A, 0x66, 0x49, 0xB4, 0x77, 0x39, 0xFC, 0x45, 0x69, 0xE2, 0x1D, 0x21, 0x1A,
		0xC9, 0x61, 0xB9, 0xB7, 0xBA, 0xE0, 0xB1, 0x39, 0x2A, 0xD8, 0xFB, 0xB8, 0xEA, 0x84, 0x77, 0xCD,
		0x50, 0xA7, 0xF0, 0x50, 0x79, 0x6E, 0x20, 0xB7, 0x99, 0x3C, 0xF8, 0x77, 0x1D, 0x84, 0xE3, 0x7A,
		0x0E, 0x78, 0x3F, 0xF6, 0x9C, 0xFE, 0x06, 0xAA, 0x9E, 0x1E, 0xBE, 0x93, 0x49, 0xD4, 0x65, 0x81,
		0x1F, 0x74, 0x33, 0x8D, 0x8E, 0xA0, 0xFD, 0xE1, 0xCF, 0x3F, 0x5A, 0xB2, 0x68, 0x3A, 0x92, 0x58,
		0x5D, 0x4B, 0x05, 0xC7, 0x9A, 0x63, 0x94, 0x02, 0x92, 0x47, 0x82, 0xC9, 0xEE, 0x79, 0xF8, 0xCF,
		0x14, 0xD1, 0x84, 0xF1, 0xDA, 0x8B, 0x25, 0x2C, 0x9C, 0x9E, 0xC4, 0xBA, 0xC6, 0x83, 0xA8, 0x68,
		0x57, 0x10, 0x25, 0xCC, 0x4C, 0x23, 0x9D, 0x73, 0x13, 0x9E, 0x8D, 0xEE, 0x3E, 0xBD, 0x3F, 0x31,
		0x46, 0x9F, 0x74, 0x60, 0x7F, 0x31, 0x4E, 0x1F, 0x1C, 0x64, 0xF0, 0x4D, 0x5B, 0x74, 0x1D, 0x4A,
		0x0D, 0x7A, 0xDE, 0xE3, 0xC1, 0xFA, 0xC4, 0xE9, 0x2E, 0xEF, 0xE2, 0x69, 0xB3, 0x3B, 0x72, 0xBF,
		0xE5, 0x01, 0xBF, 0x4C, 0x7B, 0x55, 0x52, 0xFA, 0xD1, 0xB4, 0xE6, 0x9A, 0x2B, 0x86, 0x1E, 0x7C,
		0x72, 0x2E, 0x30, 0xBD, 0x57, 0xD4, 0xAD, 0xF8, 0xE5, 0x47, 0xE7, 0x5D, 0x10, 0x9D, 0xEA, 0x5D,
		0x92, 0x92, 0xE3, 0xF9, 0x45, 0xE8, 0xEA, 0x5A, 0x5E, 0xA4, 0x44, 0x76, 0xDA, 0xD6, 0x9E, 0xA8,
		0xC8, 0xD8, 0x8A, 0xEE, 0x05, 0x3B, 0x42, 0xBE, 0x31, 0x91, 0xED, 0x9C, 0x0F, 0xC6, 0xAD, 0x10,
		0xEB, 0xB1, 0x5C, 0xEB, 0xD1, 0x59, 0x45, 0x82, 0xAF, 0x01, 0x62, 0x71, 0x86, 0x57, 0x04, 0x7A,
		0x48, 0x3F, 0x15, 0xC4, 0xF4, 0x8D, 0x4A, 0xE2, 0xC2, 0x77, 0x54, 0x63, 0xE5, 0xCE, 0x85, 0x59,
		0x09, 0xE1, 0xBD, 0x8D, 0x74, 0x5B, 0x1B, 0x11, 0xA7, 0x6A, 0x4B, 0x73, 0x72, 0x64, 0x48, 0xEE,
		0x55, 0x4D, 0xB4, 0xC7, 0x18, 0x59, 0x0F, 0x23, 0x9F, 0xA6, 0x47, 0xE3, 0x5C, 0xD3, 0xC7, 0xC7,
		0xB2, 0xF8, 0xF3, 0x37, 0xA4, 0x74, 0x15, 0x40, 0x8B, 0xB5, 0x40, 0x00, 0x74, 0x02, 0xB1, 0x94,
		0x31, 0x43, 0xB0, 0xE1, 0xBA, 0x83, 0x50, 0x34, 0xBB, 0x9B, 0x87, 0x8A, 0x48, 0xE7, 0x22, 0x59,
		0x50, 0x86, 0x59, 0x17, 0x85, 0x91, 0x4F, 0x42, 0x3F, 0x5E, 0x29, 0x95, 0x41, 0x6D, 0x1D, 0xA9,
		0xD9, 0xF3, 0x07, 0xED, 0xD7, 0xC3, 0x3F, 0xBA, 0xBC, 0x53, 0x1E, 0xAD, 0x0A, 0x6D, 0xB7, 0xD4,
		0x57, 0x79, 0x00, 0x74, 0x90, 0x7D, 0xE1, 0xFD, 0x0F, 0xE3, 0x5C, 0x96, 0xBE, 0xBB, 0xFD, 0xAE,
		0xF8, 0x70, 0x78, 0x83, 0xC0, 0x57, 0x65, 0x13, 0x37, 0x36, 0x5F, 0xF5, 0x31, 0x63, 0xE3, 0xEF,
		0x0F, 0xCB, 0xFA, 0x57, 0xC8, 0xA4, 0x60, 0xE2, 0xAB, 0x2F, 0xCA, 0x2A, 0x42, 0xC3, 0x57, 0x13,
		0xCA, 0x28, 0xA2, 0xA6, 0x38, 0x51, 0x45, 0x14, 0x00, 0x51, 0x45, 0x14, 0x00, 0x51, 0x45, 0x14,
		0x00, 0x51, 0x45, 0x14, 0x00, 0x51, 0x45, 0x14, 0x01, 0xD1, 0x12, 0x11, 0xE5, 0xEE, 0x59, 0x14,
		0xB1, 0xE3, 0x00, 0xF3, 0xC9, 0xC7, 0x35, 0x3A, 0x0B, 0x80, 0x91, 0x47, 0x08, 0x8D, 0x64, 0x95,
		0xE4, 0x2D, 0x20, 0x23, 0x27, 0x6A, 0xF2, 0x06, 0x3A, 0x7B, 0x9A, 0x4E, 0xB2, 0x15, 0x0A, 0x4F,
		0x4C, 0x83, 0x9A, 0x63, 0xF6, 0xCB, 0x7B, 0xA2, 0xAF, 0x2C, 0x49, 0x19, 0x52, 0xB8, 0x08, 0x76,
		0x8C, 0x03, 0xDB, 0xB9, 0xEF, 0xF9, 0xD3, 0x08, 0x86, 0x53, 0x98, 0x1E, 0xCE, 0x41, 0x65, 0xB9,
		0xA7, 0x94, 0x8F, 0x2C, 0x81, 0xB9, 0x82, 0x8E, 0x4A, 0xE7, 0xA8, 0x38, 0x2A, 0x0E, 0x30, 0x38,
		0x23, 0xA5, 0x45, 0xBE, 0xBC, 0x36, 0x3A, 0x11, 0xD1, 0xAD, 0xD9, 0x4A, 0xC9, 0x20, 0x96, 0xE2,
		0x45, 0x23, 0xF8, 0x83, 0x00, 0xAA, 0xF4, 0xCF, 0xA4, 0xF3, 0xD4, 0x8C, 0xD6, 0xE9, 0x2D, 0x76,
		0x79, 0xED, 0x19, 0x46, 0x8C, 0x4B, 0xB5, 0x24, 0x8D, 0xB7, 0x2E, 0x09, 0x27, 0x6A, 0x9C, 0xE3,
		0x20, 0x63, 0x39, 0xA4, 0x32, 0xAC, 0xCB, 0xB1, 0x4B, 0xE5, 0x7A, 0x02, 0x07, 0xBF, 0x51, 0x5A,
		0x80, 0x9D, 0xE7, 0xEA, 0x9A, 0xAC, 0x76, 0x16, 0x21, 0xDE, 0x68, 0x60, 0xDC, 0x61, 0x8D, 0x53,
		0x7F, 0x96, 0x09, 0xF5, 0x1C, 0x0F, 0x9A, 0x89, 0x34, 0x06, 0x16, 0xBE, 0x48, 0x3C, 0xC6, 0xB2,
		0x8E, 0x6D, 0xAD, 0x2B, 0xC5, 0xB4, 0xE0, 0x12, 0x06, 0x7A, 0xE0, 0x9F, 0xF2, 0xE7, 0xFA, 0x55,
		0xB6, 0xD6, 0xEC, 0x78, 0x3A, 0x69, 0x92, 0xDC, 0x48, 0x2F, 0xD2, 0xD1, 0xE2, 0xB8, 0x7F, 0x37,
		0x84, 0x77, 0x51, 0x81, 0xB7, 0x1C, 0x15, 0xE9, 0xD7, 0x19, 0xC7, 0xB6, 0x4D, 0x35, 0x27, 0xB8,
		0x96, 0x19, 0x63, 0x6B, 0x82, 0x12, 0x72, 0xCE, 0xFE, 0x63, 0x9C, 0x16, 0xCF, 0xDE, 0x23, 0xDF,
		0xE6, 0x99, 0x3F, 0xD1, 0x82, 0xD2, 0x14, 0x39, 0xE7, 0x23, 0xB1, 0x02, 0xA6, 0xDA, 0x59, 0x8B,
		0xA2, 0x51, 0x55, 0x95, 0x54, 0x7A, 0x9B, 0xAF, 0x3D, 0xB8, 0xA8, 0xED, 0x6C, 0xCB, 0xBC, 0xB3,
		0x0F, 0x4F, 0xB7, 0x71, 0xEF, 0x52, 0xAF, 0x65, 0x36, 0x37, 0x52, 0x5B, 0xC0, 0xEE, 0x10, 0x63,
		0x04, 0xE3, 0x3C, 0x80, 0x7B, 0x7C, 0x9A, 0xD6, 0x60, 0xB1, 0x81, 0x52, 0x41, 0xEA, 0x2B, 0xCA,
		0x18, 0xE5, 0x89, 0xF7, 0xAF, 0x56, 0x5D, 0xA8, 0x54, 0x01, 0xCF, 0x52, 0x69, 0xC4, 0x32, 0x46,
		0x29, 0xF7, 0x58, 0x83, 0xF1, 0x53, 0x74, 0xFB, 0x41, 0x71, 0x2A, 0x06, 0x6F, 0xBE, 0xE1, 0x71,
		0xCF, 0x3F, 0x95, 0x41, 0x8F, 0x6B, 0x38, 0x04, 0x71, 0xD4, 0xF6, 0xAB, 0x25, 0x9C, 0x69, 0x0B,
		0x5B, 0x83, 0x12, 0x24, 0x9B, 0xB6, 0xA3, 0x95, 0xCE, 0x1B, 0x04, 0x85, 0x70, 0x7A, 0xAB, 0x67,
		0x19, 0xF9, 0xA3, 0xA1, 0x3B, 0x21, 0xCC, 0x7E, 0xC8, 0x8C, 0x9C, 0x79, 0x52, 0x03, 0xB5, 0x00,
		0xE8, 0x41, 0xEF, 0x9F, 0xE8, 0x6A, 0xD1, 0x63, 0x33, 0x1F, 0x0C, 0x90, 0x64, 0x51, 0x31, 0x0A,
		0x09, 0x3D, 0x5B, 0x2C, 0x4F, 0xE7, 0xC9, 0xE4, 0xD5, 0x46, 0x52, 0x6F, 0x5E, 0x38, 0x82, 0xAA,
		0x49, 0x2C, 0x85, 0x88, 0x51, 0xC0, 0x27, 0x1C, 0x63, 0xB7, 0x7E, 0x2A, 0xD5, 0xA7, 0xCB, 0x6F,
		0x2E, 0x89, 0xE6, 0x5C, 0x1D, 0xCC, 0xDF, 0x78, 0x01, 0x83, 0xB9, 0x7E, 0x7F, 0x2A, 0x86, 0x77,
		0x51, 0x46, 0x27, 0xB1, 0x25, 0xC0, 0x96, 0x7B, 0xD1, 0x6F, 0x92, 0xC0, 0x1D, 0xAA, 0x10, 0x96,
		0x03, 0xE9, 0xD8, 0x0A, 0x63, 0x2D, 0x8F, 0x90, 0x91, 0x29, 0x68, 0x84, 0x9C, 0x2B, 0x6C, 0xF5,
		0x0C, 0x8C, 0x8C, 0x71, 0xD4, 0x8C, 0x76, 0xCF, 0xD6, 0xBD, 0x92, 0xE4, 0x06, 0xDD, 0x0A, 0xC9,
		0x16, 0x1B, 0x20, 0xA9, 0x29, 0x9F, 0xC0, 0x71, 0xFF, 0x00, 0xA3, 0x58, 0x3A, 0x5D, 0x2D, 0xB6,
		0xD9, 0x89, 0x45, 0x69, 0x37, 0x02, 0x46, 0x03, 0x67, 0xD8, 0xE3, 0x23, 0xF3, 0x22, 0x8B, 0x75,
		0x43, 0x59, 0x0E, 0x58, 0x54, 0xA9, 0xF5, 0xE0, 0x9E, 0xC5, 0x7F, 0xE7, 0xFC, 0x35, 0xED, 0xA3,
		0x18, 0xA6, 0x55, 0xDD, 0xB1, 0xB3, 0x80, 0xC3, 0xB5, 0x6B, 0xE0, 0x86, 0x5F, 0x4B, 0x63, 0xD8,
		0x64, 0x7F, 0xCE, 0x2B, 0x54, 0xB9, 0x2C, 0xB9, 0x38, 0x27, 0xBF, 0xFE, 0x69, 0x93, 0x16, 0x5B,
		0x34, 0xC8, 0xF2, 0x47, 0x74, 0x5C, 0xFA, 0x5D, 0x5B, 0x35, 0x60, 0xD3, 0x6F, 0x3C, 0xE7, 0x32,
		0xB3, 0x6D, 0x08, 0xC1, 0x9B, 0x03, 0xA0, 0xE9, 0x49, 0x2F, 0x98, 0xB4, 0x51, 0xCA, 0xC5, 0x59,
		0xDB, 0x82, 0xDB, 0x8E, 0x72, 0x3D, 0xFD, 0xEA, 0x24, 0x72, 0x30, 0xCE, 0x19, 0x86, 0x7D, 0x8D,
		0x76, 0x45, 0x72, 0x56, 0x70, 0xC9, 0xF1, 0xD1, 0x73, 0xD7, 0x34, 0xF2, 0xB7, 0x22, 0xF7, 0x4C,
		0x7C, 0x36, 0xE2, 0xCB, 0xB0, 0xE5, 0x91, 0x85, 0x45, 0xD5, 0x35, 0x69, 0x35, 0xE0, 0x2F, 0x6E,
		0x23, 0x11, 0xDE, 0x2C, 0x5B, 0x67, 0xC7, 0x01, 0x98, 0x7F, 0x30, 0xFA, 0xF7, 0x1E, 0xF9, 0xAD,
		0x9E, 0x0F, 0xBF, 0x90, 0xEB, 0x11, 0x5A, 0xAB, 0xED, 0x96, 0x4E, 0x23, 0x27, 0xA3, 0x36, 0x0F,
		0x07, 0xEB, 0xD2, 0xA2, 0xDF, 0xDA, 0xB7, 0xDA, 0x19, 0xA5, 0x5F, 0x2D, 0x3C, 0xC6, 0x56, 0xDA,
		0x38, 0x1C, 0xE2, 0x88, 0x7C, 0xA9, 0x88, 0xE4, 0xEA, 0x8D, 0x9A, 0x6C, 0xCA, 0xC7, 0xCB, 0x95,
		0x88, 0x03, 0xA1, 0x1D, 0xAA, 0xF3, 0xA6, 0xDF, 0xDE, 0xCC, 0xB0, 0x5A, 0xDC, 0x13, 0x7D, 0x60,
		0xA8, 0x53, 0xC9, 0x1C, 0xE1, 0x4F, 0x5C, 0x7B, 0x11, 0xEF, 0xDA, 0xB9, 0xDC, 0x5A, 0x6D, 0xC9,
		0x79, 0x3C, 0xB5, 0xDD, 0xE5, 0x9F, 0x51, 0x1E, 0xD4, 0xFF, 0x00, 0x4D, 0xD6, 0x2F, 0x74, 0xEB,
		0xA8, 0xE1, 0x8D, 0xF6, 0x12, 0x40, 0x0A, 0xDD, 0x39, 0xFF, 0x00, 0xDD, 0x3C, 0xE1, 0xC9, 0x68,
		0x8C, 0x72, 0x38, 0xB3, 0xAD, 0x69, 0x65, 0x74, 0x92, 0xF6, 0xD3, 0x5E, 0x7A, 0xE4, 0xE6, 0x05,
		0x2D, 0xD4, 0x76, 0xE7, 0xDF, 0xE3, 0xBD, 0x5A, 0x2D, 0x07, 0xF0, 0x89, 0x03, 0x19, 0x62, 0x71,
		0xED, 0x5C, 0x8E, 0xFE, 0xEA, 0xE6, 0xE5, 0x33, 0x2A, 0x00, 0x72, 0x36, 0xC9, 0x07, 0xA9, 0x03,
		0x74, 0xE1, 0x87, 0xB7, 0x15, 0x67, 0xF0, 0xE7, 0x8A, 0x27, 0x8E, 0xE2, 0xDE, 0xD3, 0x51, 0x38,
		0x82, 0x5C, 0x42, 0xB2, 0x37, 0xF2, 0x4B, 0xD8, 0x13, 0xEC, 0xDD, 0x8F, 0xBD, 0x70, 0x4F, 0x13,
		0x4B, 0x91, 0xEA, 0x7A, 0x7C, 0xEB, 0x97, 0x12, 0xF5, 0x24, 0x69, 0x2A, 0x32, 0x48, 0x37, 0x23,
		0x02, 0xAC, 0x0F, 0x70, 0x7A, 0xD7, 0xC5, 0x7E, 0x35, 0xD1, 0x1F, 0xC3, 0xBE, 0x2E, 0xD4, 0xB4,
		0xC6, 0x07, 0x6C, 0x53, 0x36, 0xCC, 0x8E, 0xAB, 0x9C, 0x83, 0xF9, 0x62, 0xBE, 0xD7, 0xAF, 0x9D,
		0x3F, 0xF9, 0x09, 0xA1, 0xF9, 0x3A, 0xC6, 0x9F, 0xAD, 0x46, 0x3D, 0x17, 0x31, 0x79, 0x4E, 0x40,
		0xFE, 0x65, 0xFF, 0x00, 0x62, 0x3F, 0x2A, 0x21, 0xB4, 0xE3, 0xFF, 0x00, 0x7F, 0xD4, 0x76, 0x4B,
		0x52, 0x4C, 0xE2, 0x34, 0x51, 0x45, 0x4C, 0x70, 0xA2, 0x8A, 0x28, 0x00, 0xA2, 0x8A, 0x28, 0x00,
		0xA2, 0x8A, 0x28, 0x00, 0xA2, 0x8A, 0x28, 0x00, 0xA2, 0x8A, 0x28, 0x02, 0xF9, 0x1C, 0x5B, 0xB2,
		0xB9, 0x1B, 0x87, 0x55, 0xF7, 0xAC, 0xE1, 0x89, 0x9A, 0x58, 0x9A, 0x33, 0x87, 0xDE, 0xBE, 0x59,
		0x07, 0x9D, 0xD9, 0xE3, 0xF5, 0xAD, 0xD1, 0x3A, 0x4B, 0x72, 0x36, 0x06, 0x39, 0xC9, 0x03, 0x18,
		0xE3, 0xB7, 0x4E, 0xF5, 0x97, 0xEF, 0x09, 0x10, 0x4A, 0xA2, 0x2C, 0x83, 0x22, 0xC8, 0xEA, 0xC3,
		0x77, 0x43, 0xD7, 0x9E, 0xF9, 0xF8, 0xEE, 0x69, 0xD0, 0x86, 0xA8, 0x75, 0x07, 0x89, 0xD9, 0xE4,
		0xFF, 0x00, 0xA9, 0x56, 0x25, 0x88, 0x94, 0x9E, 0xA7, 0x96, 0x23, 0xDB, 0x9E, 0xBE, 0xF5, 0x94,
		0x97, 0x31, 0x31, 0x8F, 0x72, 0x18, 0xDC, 0x36, 0xF6, 0x68, 0xCF, 0x00, 0x64, 0x60, 0x05, 0xE8,
		0x31, 0xFD, 0xEA, 0x64, 0x7A, 0x54, 0x1A, 0xAD, 0xB7, 0x99, 0x61, 0x34, 0x56, 0xCF, 0x05, 0x8B,
		0xDC, 0x4F, 0x1C, 0xA4, 0x9D, 0xCE, 0x8C, 0x72, 0x17, 0x19, 0x39, 0x2B, 0x83, 0xCF, 0x15, 0x5F,
		0x54, 0x95, 0xD6, 0x4D, 0xB1, 0x39, 0x0B, 0xF7, 0x88, 0x5E, 0x94, 0xC9, 0x23, 0x06, 0x9A, 0x96,
		0xA0, 0xF7, 0x37, 0x13, 0x88, 0xA6, 0x2D, 0xF6, 0x87, 0xDF, 0x27, 0x00, 0x7A, 0xBF, 0xB8, 0xE4,
		0xE2, 0x94, 0x0C, 0x87, 0x03, 0x6F, 0x2D, 0xD3, 0x3C, 0x0E, 0xB8, 0xAD, 0x20, 0x92, 0xD9, 0x06,
		0xA6, 0xA7, 0x94, 0x0A, 0x17, 0x43, 0xC8, 0x1B, 0x4B, 0x00, 0x01, 0xF7, 0x3C, 0xD0, 0x95, 0x01,
		0xA5, 0x51, 0xB7, 0x80, 0x77, 0x92, 0xDF, 0x07, 0x0D, 0xF0, 0x2A, 0x5C, 0x85, 0xF5, 0x29, 0xB8,
		0x09, 0x24, 0xAE, 0x01, 0xFE, 0x1E, 0x17, 0x6A, 0xAA, 0xF4, 0x19, 0x00, 0x67, 0x00, 0x7F, 0xBD,
		0x4B, 0x8A, 0x17, 0xB9, 0x86, 0x28, 0x22, 0x72, 0xE6, 0xDE, 0x39, 0x65, 0x50, 0x99, 0x01, 0x00,
		0xC3, 0x13, 0xC8, 0xEB, 0xC7, 0x4F, 0xC6, 0xAC, 0xB7, 0x16, 0xF1, 0xC1, 0xAB, 0x8F, 0x11, 0xDC,
		0x0B, 0x7B, 0xC9, 0x23, 0xB6, 0x8E, 0xEA, 0xEA, 0x04, 0x44, 0x58, 0xE2, 0xDE, 0xA5, 0x43, 0x7A,
		0x4F, 0xA8, 0xF9, 0x81, 0x72, 0x31, 0xFC, 0xFC, 0xD1, 0x66, 0x1C, 0xE6, 0x56, 0x0D, 0x21, 0x20,
		0x60, 0x56, 0xAC, 0xD6, 0xF0, 0x85, 0xA0, 0x91, 0xF0, 0xBE, 0x9C, 0x67, 0xE3, 0x27, 0xB5, 0x46,
		0xAA, 0x12, 0x64, 0x8B, 0x5F, 0xF1, 0x40, 0x1D, 0xF8, 0xEB, 0x8A, 0x7B, 0xAA, 0x46, 0x20, 0x90,
		0x93, 0x92, 0x7D, 0x24, 0x9C, 0x8C, 0x81, 0x80, 0x47, 0x4E, 0xF4, 0x9B, 0x4E, 0x84, 0x4B, 0x77,
		0x18, 0x62, 0x42, 0xE4, 0x16, 0x23, 0xA8, 0x1D, 0xCD, 0x58, 0xE7, 0x86, 0xDA, 0xE6, 0x77, 0x58,
		0x99, 0xFC, 0xA2, 0x99, 0x8A, 0x61, 0xEA, 0xDE, 0xF9, 0xC7, 0xAB, 0xE0, 0x8E, 0x0F, 0xB6, 0x05,
		0x63, 0x30, 0x42, 0xF7, 0x4C, 0xF2, 0x07, 0x23, 0xD0, 0x09, 0x2B, 0xC7, 0x72, 0x79, 0xAB, 0x4D,
		0xB9, 0x3B, 0x18, 0xBA, 0x02, 0x0B, 0x60, 0x02, 0x46, 0x79, 0x04, 0xF4, 0xFA, 0x55, 0x5E, 0xD5,
		0x14, 0x5D, 0x88, 0xDC, 0x2B, 0xAF, 0x20, 0x73, 0xD6, 0xAD, 0xA1, 0x22, 0x93, 0x4E, 0x82, 0x46,
		0x55, 0xDE, 0xD2, 0xBA, 0xB2, 0x9F, 0x48, 0x20, 0x63, 0x8E, 0xDC, 0x9E, 0x2A, 0x79, 0xBC, 0x22,
		0x49, 0xEC, 0xF2, 0x5B, 0x94, 0x46, 0x43, 0xC2, 0xC6, 0xB9, 0x55, 0x2B, 0x84, 0xC0, 0xF6, 0x53,
		0x83, 0x91, 0xCF, 0x50, 0x00, 0x3F, 0xD3, 0x5D, 0xC4, 0x86, 0x44, 0x8E, 0x4B, 0x78, 0xA2, 0x94,
		0xEC, 0x54, 0x72, 0xA8, 0xDB, 0x49, 0x3F, 0xCA, 0x79, 0x23, 0xE7, 0x1F, 0x4A, 0xD3, 0x7C, 0xD1,
		0x89, 0x23, 0xC2, 0x89, 0x25, 0x77, 0x67, 0x0D, 0xB6, 0x30, 0x71, 0xD3, 0x90, 0xA7, 0x83, 0xD3,
		0x83, 0xDE, 0xB1, 0xB8, 0xD4, 0x49, 0x8E, 0x54, 0x77, 0xE4, 0x05, 0x55, 0x4D, 0xBB, 0x41, 0x5E,
		0xA0, 0x10, 0x33, 0x9C, 0x7C, 0x9F, 0xAE, 0x69, 0x52, 0x1E, 0xC8, 0xB7, 0x0F, 0x26, 0x4E, 0xE7,
		0x0E, 0x02, 0x8C, 0x3F, 0x19, 0x3F, 0x5E, 0xFF, 0x00, 0x1C, 0xF6, 0xA5, 0xCE, 0xEC, 0xEF, 0xB7,
		0xDA, 0xA4, 0x5C, 0x30, 0x91, 0xC0, 0x8C, 0x20, 0x0D, 0xFE, 0x51, 0x81, 0x5A, 0x62, 0x25, 0x64,
		0x07, 0x3C, 0x0E, 0x71, 0xEF, 0x4D, 0x11, 0x5B, 0x32, 0xBA, 0x6D, 0xB0, 0x24, 0x7C, 0xF1, 0xCE,
		0x71, 0xD6, 0xA3, 0x23, 0x54, 0xF4, 0x29, 0x34, 0x52, 0x29, 0x04, 0xB0, 0x5C, 0xE7, 0x3C, 0x54,
		0x02, 0x36, 0x92, 0x31, 0x5D, 0x78, 0x5E, 0xA8, 0xE5, 0xC8, 0xB6, 0x49, 0x49, 0xA4, 0x86, 0x48,
		0xE7, 0x85, 0x8A, 0xCB, 0x13, 0x07, 0x56, 0x07, 0xA1, 0x14, 0xF2, 0xF3, 0xC4, 0x52, 0xDF, 0x19,
		0xCE, 0xD0, 0x8B, 0x71, 0xEA, 0x91, 0x00, 0xE0, 0x37, 0x72, 0x3E, 0xB5, 0x5D, 0x5A, 0xDE, 0x8C,
		0x54, 0xE4, 0x76, 0xAA, 0xF1, 0x4D, 0x90, 0x63, 0x48, 0xB5, 0x2B, 0x92, 0x85, 0x7C, 0xE7, 0x5E,
		0x0A, 0xFA, 0x4E, 0x32, 0x3D, 0x8F, 0xBD, 0x35, 0xD2, 0xAE, 0x5E, 0x46, 0x55, 0x75, 0x56, 0x2C,
		0x36, 0x06, 0x61, 0xC8, 0x00, 0x74, 0x07, 0xB5, 0x56, 0xD5, 0xFE, 0x29, 0xF6, 0x81, 0x71, 0x79,
		0x69, 0x39, 0xB8, 0x80, 0xB2, 0x20, 0x18, 0xF3, 0x31, 0xD2, 0x9F, 0x8E, 0xB4, 0x41, 0xB6, 0xBB,
		0x1C, 0xC9, 0x15, 0xCD, 0x85, 0x9A, 0x5D, 0x42, 0xCE, 0x22, 0x75, 0xC9, 0xC3, 0x71, 0xF5, 0xFE,
		0xB5, 0x60, 0xD2, 0x2E, 0x22, 0xD5, 0xAC, 0x9E, 0xD6, 0xEA, 0x20, 0x64, 0x4C, 0xF9, 0x80, 0x1C,
		0x86, 0x4C, 0x65, 0x58, 0x7B, 0x10, 0x7B, 0xD2, 0x19, 0xDE, 0x6D, 0x41, 0x5E, 0xDA, 0xC2, 0x67,
		0x96, 0x41, 0xB9, 0x8C, 0x4D, 0xC9, 0x91, 0x70, 0x72, 0xDF, 0xF7, 0x77, 0x3E, 0xFF, 0x00, 0x51,
		0x4C, 0x34, 0x08, 0x2E, 0xF4, 0x59, 0xAD, 0xAF, 0xE5, 0x1E, 0x65, 0xB6, 0x55, 0x96, 0x48, 0xF9,
		0xDC, 0xB9, 0xF5, 0x0C, 0x75, 0xC7, 0xFE, 0x2A, 0x79, 0x22, 0xA5, 0x0B, 0xF2, 0x36, 0x37, 0x28,
		0xCB, 0xE8, 0xEA, 0xBE, 0x17, 0xD5, 0x8E, 0xA3, 0x65, 0x25, 0xBC, 0xED, 0xBA, 0xEA, 0xCC, 0x88,
		0xE4, 0x63, 0xD5, 0xC6, 0x3D, 0x2F, 0xF8, 0x8E, 0xBF, 0x20, 0xD5, 0x5B, 0xF6, 0xB7, 0xA5, 0x36,
		0xB5, 0xFB, 0x3D, 0xD4, 0x57, 0x68, 0xF3, 0xAC, 0x24, 0x13, 0xA6, 0x3B, 0xA8, 0xFF, 0x00, 0x63,
		0xFA, 0x54, 0xC9, 0x24, 0x1A, 0x2F, 0x89, 0xAD, 0xB5, 0x3B, 0x51, 0xE7, 0x69, 0xD7, 0xB0, 0xE0,
		0x08, 0xFD, 0x8F, 0x23, 0xF5, 0x35, 0x6C, 0x78, 0x6D, 0x75, 0x9D, 0x36, 0x65, 0xCE, 0xE8, 0x6E,
		0xA0, 0x31, 0x37, 0xD0, 0x82, 0x30, 0x7E, 0x46, 0x6B, 0x83, 0x50, 0x9A, 0x6B, 0xA3, 0xDB, 0x84,
		0x9C, 0xE0, 0xE2, 0xFB, 0x47, 0xC2, 0xA7, 0xAD, 0x14, 0xC3, 0x5A, 0xB0, 0x7D, 0x33, 0x59, 0xBB,
		0xB2, 0x90, 0x10, 0xF0, 0xCA, 0xC8, 0x41, 0xF8, 0x38, 0xA5, 0xF4, 0xB2, 0x8F, 0x16, 0xD1, 0xD3,
		0x17, 0x6A, 0xD0, 0x51, 0x45, 0x14, 0xA6, 0x85, 0x14, 0x51, 0x40, 0x05, 0x14, 0x51, 0x40, 0x05,
		0x14, 0x51, 0x40, 0x05, 0x14, 0x51, 0x40, 0x17, 0xD8, 0xE3, 0x3B, 0xD4, 0x64, 0x2E, 0xE2, 0xAA,
		0x19, 0xB8, 0x03, 0x27, 0xAF, 0x35, 0x2F, 0x52, 0x74, 0xB8, 0xD4, 0xE7, 0x64, 0x91, 0x55, 0x98,
		0xBE, 0x72, 0xDD, 0x4F, 0x3F, 0xD7, 0x15, 0x8D, 0xA2, 0xBC, 0xD1, 0xE0, 0x86, 0x55, 0x8C, 0xF9,
		0x8E, 0x04, 0x67, 0x18, 0xE8, 0x33, 0xF5, 0x27, 0x14, 0x79, 0xA9, 0x2D, 0xBA, 0x46, 0x63, 0xC0,
		0x13, 0x17, 0x12, 0x39, 0xC1, 0xF9, 0xEF, 0xC7, 0x6E, 0x99, 0x34, 0xFE, 0x44, 0x24, 0x5B, 0x46,
		0xF6, 0x5E, 0x09, 0xBA, 0xD4, 0xA3, 0x2D, 0x1C, 0xB3, 0xDF, 0x25, 0xBA, 0x3A, 0x1C, 0x10, 0xA2,
		0x36, 0x2C, 0x33, 0xEC, 0x72, 0x06, 0x29, 0x52, 0xDF, 0xDC, 0x08, 0x96, 0x33, 0x23, 0xA4, 0x6C,
		0x00, 0x60, 0x38, 0x0C, 0x46, 0x46, 0x78, 0xEA, 0x70, 0xC4, 0x67, 0xD8, 0xD4, 0x9B, 0xD4, 0x99,
		0x34, 0x7B, 0x62, 0x08, 0xF2, 0x2E, 0x9D, 0xA5, 0xDA, 0xA3, 0x38, 0x2A, 0x76, 0xFB, 0x67, 0xBF,
		0xBD, 0x2C, 0x07, 0x70, 0x0A, 0xD8, 0x38, 0x5E, 0x3E, 0x29, 0xBB, 0x30, 0x9F, 0x6B, 0xA2, 0x49,
		0x7E, 0x67, 0x96, 0x09, 0x60, 0x86, 0xD5, 0x32, 0x4C, 0x92, 0xB1, 0x55, 0x53, 0xCE, 0x13, 0x27,
		0xB9, 0xC6, 0x07, 0xBD, 0x78, 0xD6, 0x37, 0x17, 0x76, 0x89, 0x33, 0x8D, 0xC4, 0xC8, 0xB1, 0x46,
		0xFB, 0xB3, 0x82, 0x73, 0x85, 0xFD, 0x2A, 0x44, 0x71, 0x43, 0x0F, 0x86, 0x6E, 0xE4, 0x17, 0x12,
		0x34, 0xED, 0x3C, 0x71, 0x18, 0x81, 0xC2, 0x32, 0x61, 0x8E, 0x71, 0xD4, 0x90, 0x47, 0xD3, 0x9A,
		0xD9, 0x3D, 0xED, 0xD8, 0xD1, 0xF4, 0xD9, 0x8E, 0x23, 0x44, 0x0C, 0x2D, 0xCC, 0x63, 0x04, 0xBC,
		0x6D, 0x9D, 0xED, 0xD8, 0x91, 0xBB, 0x1E, 0xF8, 0x14, 0x5B, 0x01, 0x95, 0x92, 0xC3, 0xA6, 0xBC,
		0x7A, 0x4C, 0x30, 0xCF, 0x3E, 0xA1, 0x3A, 0x14, 0x27, 0x76, 0x36, 0x5C, 0x31, 0x29, 0xB3, 0x6E,
		0x7A, 0x60, 0x85, 0xC9, 0xE7, 0xB8, 0xA8, 0x31, 0x5C, 0xA5, 0x96, 0x89, 0xAA, 0x0B, 0xC8, 0x1B,
		0xFE, 0xBA, 0xD0, 0x5B, 0x5B, 0x3E, 0xCF, 0x49, 0x75, 0x95, 0x19, 0xB0, 0x7F, 0xD2, 0x06, 0x2A,
		0x5F, 0x84, 0x6F, 0x9E, 0x4F, 0x13, 0xFD, 0xAA, 0xEE, 0x1F, 0xB6, 0xCF, 0x3A, 0x9C, 0xB9, 0x3F,
		0xC4, 0x0E, 0xC7, 0xEF, 0xE7, 0xA6, 0xEE, 0x49, 0x07, 0xE2, 0xB7, 0x4D, 0xA5, 0xD8, 0xC7, 0x6B,
		0x6D, 0xA3, 0x5D, 0x6A, 0x8D, 0x15, 0x95, 0xD5, 0xDB, 0xDC, 0x43, 0x75, 0x2C, 0x2C, 0x5A, 0x20,
		0xB1, 0xB2, 0xB0, 0x2B, 0xC6, 0x0E, 0xED, 0xAA, 0xD8, 0xF6, 0xF6, 0xC5, 0x67, 0x9D, 0x81, 0x49,
		0x65, 0xFF, 0x00, 0xA3, 0x66, 0x0C, 0x39, 0x3E, 0xA1, 0xD0, 0x83, 0xDB, 0xF0, 0x3F, 0xDA, 0xA1,
		0xD5, 0x99, 0x2D, 0xBF, 0x76, 0x78, 0x6E, 0x79, 0xEE, 0x1A, 0x3C, 0xEA, 0x50, 0x32, 0xC2, 0xA0,
		0x2B, 0xB7, 0xF0, 0xE5, 0x4F, 0xBD, 0xDD, 0x3A, 0x12, 0x0F, 0x53, 0x8C, 0x7B, 0xD5, 0x62, 0xAA,
		0x88, 0xC8, 0x63, 0xA4, 0xB2, 0xAC, 0xCD, 0xB9, 0x8A, 0xED, 0x56, 0x6C, 0x86, 0xDB, 0x90, 0x01,
		0xEF, 0xFD, 0xAA, 0xC1, 0xA4, 0x80, 0x63, 0x37, 0x82, 0x65, 0x0B, 0x0B, 0x05, 0x84, 0x9E, 0xA5,
		0xC9, 0xE4, 0x9E, 0x30, 0x30, 0xB9, 0xC7, 0x4E, 0x47, 0x43, 0xDA, 0xA5, 0x1B, 0xED, 0xDC, 0x3D,
		0xC5, 0x37, 0xD1, 0xE7, 0xDB, 0x2C, 0xB8, 0x51, 0xB5, 0xA2, 0x60, 0x7B, 0x01, 0x80, 0x4E, 0x7F,
		0x0A, 0xC6, 0x84, 0x4C, 0xF6, 0x7C, 0x0D, 0x54, 0xB1, 0x20, 0x67, 0xD4, 0x70, 0x73, 0xCF, 0xD7,
		0xBD, 0x59, 0xAC, 0xE2, 0x92, 0xE2, 0xC6, 0x25, 0x8E, 0x27, 0x12, 0xEF, 0x69, 0x0B, 0x6D, 0x2C,
		0x02, 0xF2, 0x46, 0x7A, 0x80, 0xA7, 0x07, 0x27, 0xF0, 0xAA, 0xA4, 0x39, 0x69, 0x55, 0x8F, 0x7C,
		0x72, 0x49, 0xE9, 0xFE, 0xD5, 0x6C, 0x9A, 0x76, 0x96, 0x0B, 0x7B, 0x79, 0xAE, 0x9D, 0xD2, 0x18,
		0x0F, 0xA0, 0x9C, 0xA9, 0xE7, 0x2A, 0x00, 0x5C, 0x73, 0x9C, 0xFB, 0x9F, 0xA0, 0x35, 0x3C, 0xA2,
		0x2A, 0xD8, 0xB2, 0x5B, 0x82, 0xD3, 0xC9, 0x30, 0x0C, 0x82, 0x47, 0xC8, 0x72, 0xA0, 0x29, 0xC8,
		0xEC, 0x7E, 0xBD, 0x3E, 0x9F, 0x15, 0x12, 0x7F, 0x25, 0x61, 0x06, 0x24, 0x69, 0x5B, 0xCC, 0x25,
		0x9C, 0xC7, 0xE8, 0x03, 0xB1, 0xE9, 0xBB, 0x27, 0xAF, 0x3C, 0x7B, 0x0E, 0xF5, 0x32, 0x2B, 0x29,
		0x24, 0x90, 0x18, 0xD6, 0x49, 0x26, 0x1F, 0xE1, 0xF9, 0x58, 0xDC, 0xDC, 0xE4, 0x8C, 0x73, 0x96,
		0x39, 0xFA, 0x8A, 0xCE, 0xEB, 0x37, 0x77, 0xEF, 0x14, 0x96, 0xD7, 0x12, 0x34, 0x6D, 0xE5, 0x9F,
		0xB5, 0xBB, 0x16, 0x41, 0x83, 0xE9, 0x62, 0xC4, 0x74, 0xFA, 0xF6, 0x3C, 0x56, 0x20, 0x10, 0xC9,
		0x33, 0x6F, 0xFB, 0xBD, 0x38, 0xAC, 0x23, 0x6C, 0x64, 0x54, 0x8D, 0x62, 0x40, 0x6E, 0x91, 0x94,
		0x28, 0x0D, 0xDD, 0x08, 0xDA, 0x71, 0xC7, 0x18, 0xE8, 0x38, 0xA8, 0x90, 0x67, 0x9C, 0xF7, 0xA6,
		0x15, 0x8C, 0x2D, 0xB2, 0x1C, 0x60, 0x03, 0xB9, 0x71, 0xC9, 0xC6, 0x6A, 0x0B, 0xB8, 0x91, 0xC9,
		0x03, 0x68, 0xF6, 0xCE, 0x6A, 0x6D, 0xB3, 0x30, 0x71, 0xDB, 0xB8, 0x26, 0xA1, 0x48, 0xBB, 0x26,
		0x65, 0xEB, 0x56, 0xC3, 0xE4, 0x96, 0x4E, 0xCF, 0x56, 0xB7, 0x25, 0x69, 0x15, 0xB1, 0x0D, 0x75,
		0x23, 0x9E, 0x44, 0xB8, 0x82, 0x9F, 0xBC, 0x7F, 0x0A, 0xB4, 0x47, 0x2D, 0xB2, 0x59, 0x88, 0x63,
		0x53, 0xBF, 0x69, 0xE4, 0x71, 0x83, 0x9F, 0xD6, 0xAA, 0x71, 0xF5, 0xA7, 0xBA, 0x79, 0x13, 0xE6,
		0x06, 0x65, 0x8D, 0xF8, 0x64, 0x73, 0xD8, 0xD6, 0xB3, 0x9B, 0x21, 0x2E, 0xCA, 0x4B, 0xBB, 0x7B,
		0xC8, 0xAE, 0xAD, 0x4E, 0x2E, 0x22, 0x6D, 0xC8, 0x7D, 0x88, 0xEF, 0x57, 0x8D, 0x0F, 0x55, 0xFD,
		0xF3, 0xA7, 0xCB, 0x67, 0x73, 0x13, 0x09, 0x21, 0x0F, 0x32, 0xBA, 0x81, 0x97, 0x27, 0x01, 0x97,
		0x1F, 0x39, 0xC8, 0xF9, 0xAC, 0x34, 0x7D, 0x1E, 0x2D, 0x5A, 0xD0, 0xFD, 0x98, 0x2A, 0x5D, 0x45,
		0xCC, 0xB0, 0xEE, 0xF5, 0x13, 0xD8, 0xF4, 0xE5, 0x4F, 0xE9, 0x50, 0x74, 0xB2, 0xF6, 0x5A, 0x94,
		0xCE, 0x52, 0x41, 0x75, 0x0F, 0xAF, 0x67, 0x42, 0xDD, 0x73, 0x52, 0x94, 0xE3, 0x91, 0x3A, 0x5B,
		0x41, 0x8F, 0x9E, 0x27, 0xBE, 0x99, 0x71, 0xD0, 0xE7, 0x8A, 0x0B, 0x07, 0xB3, 0x9C, 0xC7, 0x2C,
		0x61, 0x4C, 0x96, 0xFE, 0x77, 0x21, 0x1F, 0xAE, 0xD1, 0xEC, 0x0E, 0x29, 0xF6, 0x89, 0x7B, 0x16,
		0x43, 0x29, 0x54, 0x4B, 0x9F, 0xBC, 0x99, 0xE9, 0x28, 0xC7, 0x4F, 0xAF, 0xF6, 0xAA, 0x2D, 0xFD,
		0xD0, 0x8A, 0xF0, 0x3C, 0x5C, 0xAB, 0x0C, 0xFB, 0x72, 0x7A, 0xFF, 0x00, 0x5A, 0x91, 0x61, 0x34,
		0x82, 0x43, 0x68, 0xEF, 0xB9, 0x4E, 0x19, 0x1B, 0x18, 0x2A, 0xDE, 0xF5, 0xCF, 0x2C, 0x36, 0xB9,
		0x1D, 0xD8, 0xBD, 0x53, 0x4D, 0x2F, 0xD1, 0xC9, 0x3F, 0x6D, 0xBA, 0x47, 0xEE, 0xCF, 0xDA, 0x15,
		0xCC, 0xAA, 0x31, 0x1D, 0xE2, 0x2C, 0xE3, 0x8E, 0xE7, 0xAF, 0xEA, 0x0D, 0x73, 0x5A, 0xEE, 0xDF,
		0xB6, 0xF8, 0x64, 0xD4, 0xB4, 0x2D, 0x27, 0x57, 0x64, 0xC4, 0xB0, 0xBB, 0x5B, 0xCA, 0xC3, 0xA1,
		0x38, 0xDC, 0x3F, 0xBD, 0x70, 0x9A, 0x9E, 0x55, 0xD3, 0x67, 0xA9, 0x82, 0x4A, 0x51, 0xD0, 0x51,
		0x45, 0x15, 0x22, 0xC1, 0x45, 0x14, 0x50, 0x01, 0x45, 0x14, 0x50, 0x01, 0x45, 0x14, 0x50, 0x01,
		0x45, 0x14, 0x50, 0x07, 0x4B, 0x11, 0x24, 0xCB, 0x0C, 0xA9, 0x32, 0x12, 0xE8, 0x03, 0x04, 0x3B,
		0x49, 0x23, 0x39, 0x07, 0x8C, 0x0C, 0xFF, 0x00, 0x4E, 0xD5, 0x17, 0xCB, 0x45, 0x13, 0x24, 0xBE,
		0xA9, 0x3D, 0x51, 0xE3, 0x76, 0x36, 0x9C, 0x8E, 0x4F, 0xBF, 0x43, 0xC7, 0x15, 0x84, 0x33, 0x34,
		0x5E, 0x5C, 0x85, 0x89, 0x21, 0xB2, 0x71, 0xEE, 0x3A, 0x73, 0x5B, 0xCD, 0xC5, 0xB4, 0x9B, 0x4C,
		0xCB, 0xE5, 0xAF, 0xF8, 0xA4, 0xC4, 0xA0, 0xE4, 0x8C, 0x8F, 0x7E, 0xF8, 0xFC, 0x29, 0xD0, 0x84,
		0x4B, 0xC4, 0xD9, 0x6F, 0x04, 0x25, 0x9C, 0xCA, 0x80, 0x87, 0x42, 0x46, 0x17, 0x27, 0x20, 0x0A,
		0xC2, 0xDA, 0x18, 0xD2, 0xF1, 0xA2, 0x90, 0xB3, 0xB1, 0x8D, 0x94, 0x15, 0xE3, 0xD5, 0x8E, 0xFD,
		0x78, 0x14, 0xCB, 0x52, 0x51, 0x73, 0xAB, 0xB6, 0xF2, 0xB3, 0x4D, 0x18, 0x4D, 0xEA, 0x8F, 0xE8,
		0xE0, 0x00, 0x17, 0x3D, 0x78, 0x5C, 0x0C, 0xFB, 0xE7, 0xEB, 0x59, 0xDB, 0x5B, 0x3B, 0xDC, 0x6A,
		0xF7, 0x46, 0xDF, 0xD3, 0x6C, 0x30, 0x64, 0x43, 0xE9, 0x8F, 0x9D, 0xA1, 0x47, 0xB9, 0x23, 0x81,
		0xCE, 0x7A, 0x9E, 0x6B, 0x6C, 0xC1, 0x0C, 0x41, 0x9C, 0x34, 0x6C, 0xF8, 0x45, 0x19, 0xC6, 0x78,
		0xCD, 0x3E, 0xF1, 0x34, 0x22, 0x35, 0xD2, 0xED, 0x22, 0xC8, 0xD9, 0x65, 0x1B, 0xB2, 0x76, 0x25,
		0xD7, 0x3B, 0xFD, 0xB9, 0x1B, 0x41, 0xFF, 0x00, 0xB6, 0xA1, 0x68, 0x36, 0x51, 0x6A, 0x1A, 0xBC,
		0x50, 0xDC, 0xC9, 0x14, 0x36, 0xAC, 0xE0, 0xCD, 0x2B, 0x91, 0x85, 0x45, 0xF5, 0x37, 0x3F, 0x40,
		0x78, 0xEF, 0x59, 0xF8, 0x87, 0x52, 0x4D, 0x47, 0x5D, 0xB9, 0xBF, 0x89, 0x11, 0x23, 0x99, 0x8F,
		0x96, 0x8A, 0xBB, 0x02, 0xA0, 0xC0, 0x41, 0x81, 0xD3, 0x0A, 0x05, 0x68, 0x13, 0xF4, 0x26, 0x82,
		0x16, 0x82, 0x5B, 0xD5, 0xB6, 0x92, 0xDD, 0xC6, 0x65, 0x47, 0x62, 0xA6, 0x40, 0x0F, 0x19, 0xC7,
		0x61, 0x83, 0x82, 0x31, 0xF9, 0xD2, 0x3B, 0xD4, 0x09, 0x72, 0xF0, 0xC9, 0x39, 0xF4, 0x9D, 0x98,
		0x39, 0x38, 0xF7, 0x3F, 0x9D, 0x4B, 0x99, 0x6E, 0x60, 0x83, 0x7A, 0xC9, 0xB4, 0xAA, 0x9D, 0xBB,
		0x7F, 0x94, 0x13, 0xC8, 0xE7, 0xA6, 0x6A, 0x57, 0x86, 0xE3, 0x49, 0xA7, 0x9A, 0xE2, 0x68, 0x56,
		0x45, 0xB3, 0x1E, 0x7B, 0x19, 0x06, 0x42, 0xA8, 0xF4, 0xE4, 0xF3, 0xF2, 0x30, 0x39, 0x07, 0x1F,
		0x8D, 0x62, 0xD6, 0xCC, 0x66, 0x1E, 0x24, 0xB4, 0x4D, 0x37, 0x48, 0xD3, 0x6D, 0xD9, 0x21, 0x37,
		0x17, 0x39, 0xB9, 0x66, 0x44, 0xDA, 0xC8, 0x30, 0x17, 0x61, 0xE4, 0xF7, 0x1B, 0xB0, 0x40, 0x23,
		0x3F, 0x35, 0x53, 0xF7, 0xA7, 0xDE, 0x27, 0xD5, 0xA7, 0xD7, 0xB5, 0x46, 0xD4, 0xA7, 0x11, 0x82,
		0x55, 0x61, 0x5D, 0x83, 0x19, 0x08, 0x30, 0x0F, 0xCE, 0x47, 0x7A, 0x43, 0x54, 0x8F, 0x5B, 0x25,
		0x2E, 0xC3, 0x1D, 0x0D, 0x33, 0xD3, 0xF2, 0xAC, 0x32, 0x76, 0xAB, 0xAB, 0x03, 0xC6, 0x78, 0x3C,
		0x52, 0xC0, 0xB9, 0xCF, 0xE7, 0x4C, 0x6C, 0xB0, 0x61, 0x95, 0x4B, 0x00, 0x51, 0x43, 0xAF, 0x19,
		0xDD, 0x83, 0xC8, 0xFD, 0x69, 0xA8, 0x95, 0x8D, 0x34, 0xCB, 0x44, 0x9E, 0x49, 0x43, 0x48, 0x10,
		0xC6, 0xC7, 0x93, 0xDF, 0x9C, 0x1E, 0x29, 0xB2, 0xC5, 0x6F, 0xF6, 0x96, 0x13, 0x5C, 0x33, 0x9C,
		0x60, 0x04, 0x89, 0x32, 0x71, 0xEE, 0x4B, 0xE7, 0xF1, 0xA8, 0x9A, 0x21, 0x54, 0x9A, 0x60, 0xEC,
		0x58, 0x12, 0x09, 0x01, 0x80, 0x07, 0xEB, 0x9E, 0xBD, 0xA9, 0xAD, 0xD3, 0xC7, 0x1B, 0x4F, 0x19,
		0x8C, 0xB1, 0x8D, 0xD9, 0x55, 0x0A, 0x0F, 0x52, 0xF3, 0x9C, 0x73, 0x90, 0x71, 0xCF, 0x43, 0xD2,
		0xB9, 0xE6, 0xDF, 0x2A, 0x04, 0x47, 0x16, 0xF0, 0xC7, 0x1C, 0x07, 0xCC, 0x92, 0x20, 0x50, 0xE7,
		0xF8, 0xF9, 0x72, 0x09, 0xFF, 0x00, 0x2A, 0x8C, 0xA7, 0xB1, 0x19, 0xE4, 0x1E, 0x09, 0xE6, 0xA0,
		0x5C, 0x98, 0x6D, 0xB6, 0xBB, 0x45, 0x13, 0xC7, 0x20, 0x2D, 0x1A, 0xC9, 0x19, 0x25, 0x30, 0xD8,
		0x21, 0x5B, 0x90, 0x40, 0xEB, 0x9E, 0xFF, 0x00, 0x5A, 0x94, 0xF6, 0xE2, 0x09, 0xE3, 0x8C, 0xCD,
		0x6C, 0x1A, 0x32, 0x3D, 0x11, 0xDC, 0x46, 0x77, 0x01, 0xD7, 0x86, 0x18, 0xE7, 0xB1, 0xE7, 0xA7,
		0x4A, 0xDD, 0x7A, 0x96, 0x30, 0x69, 0xB6, 0xD7, 0xE2, 0xC1, 0xA7, 0x59, 0x25, 0x78, 0x99, 0x4C,
		0x82, 0x68, 0xC2, 0xF6, 0x1B, 0xB0, 0x19, 0x1B, 0x20, 0x91, 0xDF, 0x14, 0xC9, 0x99, 0xFD, 0x95,
		0xAD, 0x41, 0x63, 0x6B, 0x74, 0x54, 0x44, 0x47, 0x8C, 0x9D, 0xC0, 0x1C, 0x1C, 0xE3, 0xB8, 0xF7,
		0xF9, 0xEF, 0xC7, 0xB5, 0x44, 0x56, 0x3B, 0x14, 0xD6, 0x77, 0xD3, 0x5B, 0xCB, 0x77, 0x27, 0xD9,
		0xA3, 0x58, 0xE2, 0xE8, 0xA1, 0x37, 0x63, 0x1E, 0xFE, 0xA2, 0x4F, 0x35, 0x8C, 0x24, 0x6D, 0xC1,
		0xAD, 0xB1, 0x5F, 0x44, 0xEB, 0x60, 0xFB, 0xD3, 0x04, 0x82, 0xBE, 0xD5, 0xA2, 0xF1, 0x31, 0x30,
		0x6C, 0xFD, 0xE1, 0xCD, 0x67, 0x03, 0x32, 0xB8, 0xD9, 0xF7, 0xF7, 0x0C, 0x63, 0xB5, 0x6D, 0xBE,
		0x7F, 0x36, 0x0D, 0xC5, 0x70, 0xC1, 0xB9, 0xF9, 0xA7, 0xC6, 0xEA, 0x44, 0xE5, 0xB2, 0x12, 0xF5,
		0xAD, 0xAB, 0x5A, 0x45, 0x6C, 0x4A, 0xEC, 0x44, 0x19, 0x2A, 0x36, 0xDA, 0x73, 0x53, 0xD5, 0x83,
		0xFA, 0x85, 0x2E, 0x41, 0x53, 0x20, 0x1E, 0xA0, 0xBE, 0xF5, 0x44, 0x72, 0xE4, 0x5E, 0x4B, 0x35,
		0x9E, 0xB3, 0x7B, 0xA5, 0x6A, 0x70, 0x6A, 0x16, 0xEF, 0xFC, 0x68, 0xBA, 0xA9, 0xE8, 0xE3, 0xB8,
		0x3E, 0xF9, 0xAE, 0x87, 0x7F, 0xAE, 0xD8, 0x6A, 0xD6, 0x1A, 0x76, 0xAB, 0x6D, 0x6A, 0x62, 0xBC,
		0x79, 0x96, 0x3B, 0x8D, 0xB8, 0xC7, 0x61, 0x82, 0x7D, 0x8E, 0x78, 0xAE, 0x6F, 0x6A, 0x3C, 0xC8,
		0xCA, 0x15, 0x38, 0x1D, 0x5C, 0x02, 0x42, 0x0F, 0x73, 0x8E, 0xC2, 0xAC, 0xFA, 0x04, 0x0C, 0x60,
		0xF2, 0x04, 0x68, 0xC0, 0x32, 0xCA, 0xA5, 0x8E, 0x47, 0xFC, 0x35, 0xCD, 0x96, 0x0B, 0xE4, 0x18,
		0xB3, 0x49, 0x27, 0x07, 0xB4, 0x7B, 0xAE, 0xBF, 0x99, 0x71, 0x13, 0x2F, 0xA9, 0x36, 0xEC, 0x46,
		0x1C, 0x64, 0x02, 0x70, 0x2B, 0x6E, 0x88, 0xED, 0x34, 0xC1, 0xFA, 0x38, 0xE1, 0x73, 0xDC, 0xD6,
		0x71, 0xAA, 0x81, 0x77, 0x61, 0x75, 0x00, 0x49, 0x04, 0xCC, 0x50, 0xF5, 0x28, 0x79, 0x23, 0x9F,
		0x6C, 0xF0, 0x7E, 0xBF, 0x15, 0x3F, 0x43, 0xB2, 0x92, 0xD7, 0x31, 0xCD, 0x1A, 0x79, 0xC5, 0x7E,
		0xE3, 0x0E, 0x53, 0x1D, 0xCF, 0x3F, 0xF3, 0x9A, 0xA7, 0x35, 0xED, 0x50, 0xB1, 0xC7, 0x2F, 0x7B,
		0x92, 0xE8, 0xF3, 0xC7, 0x5A, 0x7F, 0xEF, 0x7F, 0xD9, 0x8E, 0xAE, 0x57, 0x69, 0x68, 0x76, 0xCF,
		0xB3, 0xBA, 0xB2, 0x9C, 0x1F, 0xC3, 0x04, 0xD7, 0xCB, 0xA7, 0xAD, 0x7D, 0x6B, 0x02, 0x9B, 0x87,
		0xBB, 0xD3, 0xDF, 0x05, 0x2F, 0x62, 0x92, 0xDC, 0xF3, 0xC0, 0xCA, 0x9C, 0x1F, 0xCE, 0xBE, 0x52,
		0xBC, 0x84, 0xDB, 0xDD, 0xCD, 0x09, 0xEA, 0x8E, 0x54, 0xD7, 0x1E, 0x48, 0xB5, 0x13, 0xDD, 0xF4,
		0x92, 0x5D, 0x11, 0xE8, 0xA2, 0x8A, 0x81, 0xD8, 0x14, 0x51, 0x45, 0x00, 0x14, 0x51, 0x45, 0x00,
		0x14, 0x51, 0x45, 0x00, 0x14, 0x51, 0x45, 0x00, 0x74, 0x48, 0x11, 0xD2, 0x35, 0x2E, 0x46, 0xC8,
		0x5F, 0x70, 0x38, 0x1C, 0xB7, 0x1C, 0x1F, 0x7A, 0x2F, 0x16, 0x41, 0x75, 0xF6, 0x48, 0xCA, 0x85,
		0x0B, 0xB1, 0x57, 0xCC, 0xC8, 0x50, 0x49, 0x20, 0x03, 0xC7, 0xBD, 0x6B, 0xB3, 0xCC, 0xE1, 0x61,
		0x76, 0xC6, 0x59, 0x71, 0x26, 0xD2, 0xDB, 0x79, 0xF8, 0x04, 0xD6, 0xDB, 0xE2, 0x26, 0xD4, 0x66,
		0x92, 0x25, 0xDE, 0x37, 0x12, 0xD9, 0x00, 0xE7, 0x9E, 0x4F, 0x52, 0x70, 0x71, 0xDE, 0x9F, 0xC8,
		0x84, 0x44, 0x95, 0xE3, 0x92, 0x47, 0x38, 0x3D, 0xB3, 0x9E, 0x87, 0x38, 0xFE, 0xD5, 0x8C, 0x77,
		0xAC, 0x04, 0xD0, 0xBE, 0x76, 0x3B, 0x87, 0x65, 0xC9, 0xC6, 0xE1, 0xD0, 0xE3, 0xA7, 0x73, 0xD7,
		0x3D, 0xEB, 0x73, 0x2A, 0xF9, 0x17, 0x08, 0x99, 0x60, 0x58, 0xB6, 0x42, 0xA8, 0x03, 0x1D, 0x32,
		0x73, 0xD3, 0x9A, 0x5E, 0xC3, 0x7E, 0x0F, 0xF3, 0x1E, 0x4F, 0xC9, 0xCD, 0x32, 0x46, 0x0E, 0x74,
		0xB8, 0xE4, 0x3A, 0x4D, 0xE4, 0x89, 0x02, 0xB8, 0x66, 0x11, 0x8C, 0x10, 0x1C, 0x96, 0x3D, 0x14,
		0x64, 0x67, 0xA7, 0xCF, 0xEB, 0x50, 0xEE, 0xEC, 0xA7, 0x7B, 0xC2, 0x36, 0x30, 0x38, 0x0D, 0xB8,
		0xF1, 0xB8, 0x63, 0x39, 0xE6, 0xA7, 0x78, 0x4B, 0x4C, 0x93, 0x57, 0xD6, 0x60, 0xB1, 0x58, 0xA3,
		0x92, 0x36, 0x6F, 0x31, 0x96, 0x42, 0xD8, 0x38, 0xFF, 0x00, 0xB7, 0x91, 0x9E, 0x99, 0x00, 0xD3,
		0x5D, 0x69, 0x6C, 0x61, 0xF1, 0x04, 0xF6, 0x51, 0xCE, 0x26, 0xFB, 0x32, 0xA4, 0x38, 0x68, 0x82,
		0x06, 0x75, 0x4E, 0x4E, 0xD0, 0x42, 0x8E, 0x72, 0x33, 0x9C, 0xF3, 0xD2, 0xB1, 0xBA, 0x60, 0x57,
		0x23, 0x94, 0x49, 0x6C, 0x6D, 0x98, 0x39, 0x23, 0x01, 0x4F, 0x20, 0x0E, 0x7A, 0x7C, 0x8F, 0xD7,
		0xB0, 0xAD, 0x36, 0xB3, 0x9B, 0x0B, 0x9F, 0x34, 0x17, 0x30, 0xBE, 0x03, 0x84, 0x73, 0x18, 0x7C,
		0x73, 0xB7, 0x23, 0xA7, 0x4F, 0xC2, 0xA4, 0x34, 0x68, 0xB2, 0xCC, 0xD3, 0x1D, 0xAE, 0xD9, 0xDB,
		0xD3, 0x1B, 0xB8, 0xC7, 0x6E, 0x87, 0xDE, 0xB3, 0xB8, 0x50, 0x50, 0xAA, 0x44, 0x23, 0xC4, 0x7B,
		0x59, 0x77, 0x6E, 0xE7, 0x00, 0x12, 0x3E, 0x09, 0xFC, 0x3F, 0x2A, 0xD4, 0x60, 0xAA, 0x39, 0x63,
		0x5B, 0x1B, 0xD8, 0xE4, 0x84, 0x3C, 0x92, 0x6D, 0x29, 0x27, 0xFF, 0x00, 0x6C, 0x86, 0xC9, 0xC7,
		0xD4, 0x71, 0x50, 0x2A, 0x7E, 0xD6, 0x75, 0x95, 0x30, 0x02, 0xAA, 0xE4, 0x91, 0xDC, 0x8A, 0x83,
		0xB7, 0x82, 0x6A, 0x88, 0x8C, 0x8C, 0x80, 0x02, 0x30, 0x7B, 0x9C, 0xE6, 0x98, 0x68, 0xC8, 0xA6,
		0xF5, 0x19, 0xBD, 0x4B, 0xCE, 0x57, 0x1D, 0x47, 0x4C, 0x52, 0xE5, 0xC9, 0x52, 0x07, 0xD6, 0x98,
		0xE9, 0x2A, 0x3C, 0xEE, 0x64, 0x0A, 0x3E, 0xF0, 0x07, 0x1E, 0xA2, 0x3A, 0x0E, 0x7D, 0xEB, 0x59,
		0x31, 0xBD, 0xB2, 0x22, 0x5F, 0x3A, 0xC4, 0x49, 0x62, 0x85, 0x51, 0xBB, 0xFE, 0x9F, 0x4A, 0xB0,
		0x5E, 0x4D, 0xE7, 0x18, 0xE5, 0x67, 0xDA, 0xF2, 0xA6, 0xF7, 0xC3, 0x60, 0xEE, 0x03, 0xAE, 0x48,
		0x19, 0xE0, 0xE7, 0xAF, 0x73, 0xCD, 0x57, 0xAD, 0xCC, 0x9F, 0xBC, 0x51, 0xA3, 0x70, 0x24, 0x20,
		0xF4, 0xCE, 0x49, 0xEF, 0xF4, 0xE0, 0x9A, 0xB5, 0xEA, 0x76, 0xF2, 0xBC, 0x69, 0x09, 0x88, 0x5C,
		0x4A, 0xD0, 0xAB, 0xAB, 0x89, 0x04, 0x8C, 0x07, 0x18, 0xC2, 0xE4, 0x11, 0xF2, 0x48, 0xC8, 0xED,
		0x5C, 0xD9, 0x3B, 0x40, 0x8A, 0xFD, 0xCC, 0xA8, 0xB3, 0xC6, 0x7C, 0x99, 0xF6, 0xCE, 0x81, 0x63,
		0x0E, 0x43, 0x10, 0x78, 0xE4, 0x13, 0xD4, 0x9E, 0xC7, 0xA8, 0xCF, 0x5C, 0xF5, 0x9D, 0xE2, 0x29,
		0x2D, 0xAD, 0x34, 0xCB, 0x5B, 0x5B, 0x46, 0x73, 0x3D, 0xC5, 0xA2, 0x4E, 0xD2, 0x12, 0x43, 0x75,
		0x6E, 0x33, 0xC6, 0xFE, 0xF9, 0x3D, 0x38, 0x18, 0x1C, 0x73, 0x13, 0x52, 0xB6, 0x49, 0xB4, 0x78,
		0x6F, 0x17, 0x26, 0x48, 0x1F, 0xA0, 0x41, 0xF7, 0x09, 0xCF, 0x27, 0x23, 0x27, 0x20, 0x9E, 0x33,
		0xC7, 0x5C, 0x75, 0xAD, 0x93, 0x46, 0x97, 0xFE, 0x09, 0x9A, 0x07, 0xF5, 0xDD, 0x69, 0x4C, 0x64,
		0xB7, 0x98, 0x7D, 0xE3, 0x6E, 0xEC, 0x09, 0x52, 0x33, 0x9E, 0x0B, 0x06, 0xE9, 0xD3, 0x3D, 0x29,
		0xA9, 0x30, 0xEC, 0xA2, 0xB3, 0x31, 0x97, 0x96, 0xDD, 0xDB, 0xF0, 0xAD, 0xCB, 0x21, 0x04, 0x56,
		0x85, 0x47, 0x59, 0x8F, 0x19, 0xCF, 0xB5, 0x6F, 0x78, 0x9D, 0x1B, 0x0C, 0x31, 0x80, 0x0E, 0x3E,
		0xB4, 0xE9, 0x19, 0x22, 0x72, 0x7A, 0xF0, 0x53, 0x86, 0x5E, 0x72, 0x2B, 0x64, 0xFC, 0xC4, 0x4F,
		0xBF, 0x38, 0xA8, 0xF0, 0x47, 0xB9, 0x19, 0x83, 0x80, 0xCA, 0x47, 0xA7, 0xDF, 0x34, 0xCA, 0xE1,
		0x11, 0xB4, 0xEF, 0x35, 0x32, 0xA4, 0x22, 0x2B, 0xA3, 0x75, 0x0C, 0x73, 0xC8, 0xFF, 0x00, 0x4F,
		0x1F, 0xAD, 0x32, 0x7B, 0x21, 0x2E, 0x85, 0x4B, 0x5B, 0x57, 0x8A, 0xD2, 0xBD, 0x6B, 0x6A, 0xD7,
		0x6A, 0x25, 0x22, 0x6C, 0x38, 0x6E, 0x2A, 0x7C, 0x51, 0x17, 0xE9, 0x8E, 0x3D, 0xE9, 0x5C, 0x67,
		0x06, 0x9D, 0xC2, 0xF1, 0xED, 0x04, 0xE4, 0xAB, 0x8F, 0x7E, 0x41, 0xAD, 0x38, 0xF2, 0xAA, 0x1A,
		0xE9, 0xF7, 0x0A, 0x12, 0x45, 0x75, 0x03, 0x7A, 0xED, 0xDF, 0x93, 0xC7, 0x1E, 0xC3, 0xAD, 0x5E,
		0x74, 0x45, 0x53, 0x64, 0x0A, 0x4F, 0xBA, 0x54, 0x1E, 0x4F, 0x40, 0x3D, 0x3D, 0xBE, 0x7F, 0x3F,
		0x71, 0x5C, 0xDB, 0x24, 0x1D, 0xAA, 0xC3, 0xDF, 0x38, 0xE4, 0xFD, 0x69, 0xFE, 0x89, 0x75, 0x73,
		0x69, 0x0D, 0xDA, 0xA2, 0x8D, 0xCF, 0x1A, 0x9E, 0x5B, 0xD8, 0xEE, 0xE3, 0xE7, 0x8F, 0xEB, 0x53,
		0xCB, 0x89, 0xC9, 0x68, 0x4C, 0x79, 0x36, 0xEC, 0xE9, 0x11, 0xD8, 0x5B, 0x6A, 0x16, 0xEB, 0x78,
		0x8C, 0x11, 0x91, 0x76, 0xB1, 0x03, 0x25, 0x1F, 0xA7, 0xE5, 0xDE, 0xB7, 0xCF, 0x28, 0xB7, 0x8A,
		0x37, 0x92, 0x3F, 0x32, 0x68, 0xC7, 0x3E, 0x5A, 0x95, 0x5C, 0x80, 0x7D, 0x47, 0xDC, 0xF4, 0xFC,
		0x8F, 0xBD, 0x21, 0xD1, 0x35, 0xB5, 0xF3, 0x84, 0xE5, 0x0B, 0xC7, 0x20, 0xC4, 0xB0, 0xB7, 0x46,
		0x1D, 0xFF, 0x00, 0x11, 0x80, 0x7F, 0x1A, 0xE8, 0x36, 0xB2, 0xE9, 0xE6, 0x28, 0xE4, 0x89, 0x53,
		0xCA, 0x9C, 0x0D, 0x8E, 0xDF, 0xCD, 0x9E, 0xDC, 0xF4, 0xAF, 0x37, 0xF2, 0x83, 0xA9, 0x1E, 0xB6,
		0x08, 0x47, 0x22, 0xFC, 0x5D, 0x15, 0x0D, 0x2E, 0xE6, 0x38, 0x2E, 0x12, 0x67, 0x50, 0x58, 0x02,
		0xCA, 0x0F, 0xBE, 0x38, 0xAF, 0x9A, 0xBC, 0x6F, 0x68, 0x6C, 0xBC, 0x63, 0xA9, 0xC4, 0x06, 0x01,
		0x99, 0x98, 0x7D, 0x0F, 0x3F, 0xDE, 0xBE, 0xA8, 0xB3, 0xD2, 0xCA, 0xF8, 0xAE, 0xE8, 0x05, 0x56,
		0xB6, 0x52, 0x58, 0xAF, 0x61, 0x91, 0xC5, 0x7C, 0xFB, 0xFB, 0x6A, 0xD2, 0x7F, 0x75, 0xF8, 0xE5,
		0x82, 0xFF, 0x00, 0x87, 0x2C, 0x2A, 0xEA, 0x71, 0xD4, 0x63, 0x1F, 0xDA, 0xBA, 0xE4, 0xE3, 0x28,
		0x34, 0xBE, 0x99, 0x4F, 0x4F, 0x19, 0x42, 0x6A, 0xFE, 0xD1, 0xCD, 0xA8, 0xA2, 0x8A, 0xE4, 0x3D,
		0x10, 0xA2, 0x8A, 0x28, 0x00, 0xA2, 0x8A, 0x28, 0x00, 0xA2, 0x8A, 0x28, 0x00, 0xA2, 0x8A, 0x28,
		0x03, 0xA0, 0x59, 0xA6, 0x65, 0x85, 0x1D, 0xD8, 0x26, 0xE0, 0xEE, 0x54, 0x80, 0x76, 0xE0, 0xE4,
		0x83, 0xDB, 0x8C, 0xFC, 0xD4, 0xCB, 0x89, 0x55, 0x6E, 0x1A, 0x58, 0xA4, 0x68, 0x46, 0xED, 0xBC,
		0x60, 0x67, 0x8C, 0x67, 0x00, 0x0E, 0xA3, 0xDF, 0xAF, 0xC9, 0xA8, 0x11, 0xC3, 0x89, 0x03, 0xFF,
		0x00, 0xF4, 0x7A, 0x33, 0xA8, 0xCE, 0x3F, 0xE6, 0x7B, 0xD4, 0xA6, 0x9D, 0x64, 0xB7, 0x64, 0x72,
		0x09, 0x24, 0xB0, 0x2C, 0x40, 0x3C, 0x7D, 0x7B, 0xF0, 0x31, 0xF8, 0xD3, 0x88, 0x6C, 0x30, 0xA8,
		0x7D, 0x46, 0xD5, 0x5D, 0x18, 0x3B, 0x04, 0x8E, 0x67, 0xDC, 0xA7, 0x2A, 0x4E, 0x30, 0x07, 0xF9,
		0xBA, 0x73, 0xD3, 0xE2, 0x95, 0x46, 0xA1, 0xA4, 0x07, 0x18, 0xDA, 0x0E, 0x47, 0x4A, 0x93, 0xE7,
		0xF9, 0x84, 0x3C, 0x84, 0x82, 0x1C, 0x0D, 0xDC, 0x92, 0x31, 0xD7, 0x07, 0xA1, 0xFF, 0x00, 0xD5,
		0x69, 0x99, 0x19, 0x23, 0x91, 0x95, 0x46, 0x43, 0x1D, 0xE3, 0x18, 0x2A, 0x0F, 0x4F, 0xEF, 0xC7,
		0x6A, 0xD5, 0x60, 0x3D, 0xF0, 0x10, 0x54, 0xF1, 0x3D, 0xB4, 0xCF, 0xB8, 0xA5, 0xB2, 0xBC, 0xCE,
		0x11, 0xB0, 0x4A, 0xAA, 0x31, 0xEB, 0xD4, 0x0F, 0x73, 0x4A, 0xA4, 0xB2, 0xB8, 0x58, 0x6C, 0xAF,
		0xE2, 0x99, 0x9E, 0x6B, 0xBD, 0xCE, 0x55, 0x4E, 0x48, 0x21, 0xB1, 0xC9, 0xEF, 0xFD, 0x6A, 0x7E,
		0x95, 0xA8, 0x22, 0xD8, 0xC1, 0x65, 0x1C, 0x92, 0x2C, 0xAE, 0xCE, 0x24, 0x51, 0xB5, 0x41, 0x56,
		0x00, 0x00, 0x0F, 0x07, 0x3D, 0x3A, 0x9C, 0x63, 0x3E, 0xF5, 0x3F, 0x53, 0xB4, 0x93, 0x53, 0xB5,
		0x86, 0xF1, 0x6E, 0x21, 0xB7, 0x86, 0xD2, 0x38, 0xE2, 0x87, 0x74, 0xA5, 0x4F, 0x96, 0x72, 0x42,
		0x80, 0x01, 0xE7, 0x3B, 0xC9, 0x39, 0xE3, 0x3C, 0x0E, 0x99, 0xCB, 0xD9, 0x94, 0x26, 0xBD, 0x89,
		0x56, 0xDE, 0x36, 0x55, 0xC6, 0x01, 0xE0, 0x30, 0x6C, 0x9F, 0x73, 0xD8, 0x77, 0xA8, 0xEA, 0x89,
		0xE4, 0x4A, 0x0F, 0xDE, 0x41, 0x81, 0x93, 0xC0, 0x07, 0xFA, 0x74, 0xAD, 0x97, 0xEC, 0x88, 0xB1,
		0xA9, 0xCE, 0xE1, 0xC9, 0x52, 0x19, 0x71, 0xF1, 0xC9, 0x39, 0x07, 0xE8, 0x3A, 0x54, 0x68, 0x01,
		0x67, 0x1B, 0x64, 0xDB, 0xEA, 0xC1, 0x6C, 0x75, 0x1F, 0xFA, 0x3D, 0xAB, 0x50, 0x33, 0x08, 0x5D,
		0x44, 0x27, 0x7A, 0xAE, 0xDC, 0x91, 0x95, 0x38, 0x24, 0x10, 0x41, 0x3F, 0x50, 0x70, 0x69, 0x49,
		0x1B, 0x59, 0x86, 0x43, 0x0E, 0x99, 0x1D, 0xE9, 0xD5, 0xE5, 0x9D, 0xAA, 0x69, 0x91, 0xDC, 0xDB,
		0x4A, 0xD2, 0xB1, 0x72, 0x8E, 0x76, 0x6C, 0x03, 0x80, 0x57, 0x8F, 0xCF, 0xE2, 0x93, 0x11, 0x93,
		0x9A, 0xA4, 0x59, 0x19, 0x18, 0x2B, 0x6D, 0x60, 0x7B, 0x83, 0x9A, 0x7F, 0xA0, 0x5A, 0x4E, 0x97,
		0x62, 0xF4, 0x47, 0x1F, 0x95, 0x03, 0x16, 0x0D, 0x37, 0x2B, 0x90, 0xA4, 0xE3, 0x07, 0xA9, 0x19,
		0x04, 0x0F, 0x8A, 0x47, 0x8E, 0x9F, 0x35, 0x66, 0xF0, 0xF8, 0x92, 0xEA, 0x33, 0x0A, 0x00, 0x25,
		0x43, 0xE8, 0xC4, 0x9B, 0x4E, 0xF2, 0x38, 0xE3, 0x23, 0x3F, 0x77, 0xF5, 0xF9, 0xAD, 0x93, 0xD1,
		0x34, 0x8C, 0xE1, 0x72, 0x97, 0xB6, 0xD7, 0x0B, 0xE9, 0xF2, 0xA4, 0x57, 0x51, 0x8C, 0xE4, 0xF5,
		0x39, 0xEB, 0xC1, 0xE9, 0x56, 0xE9, 0x24, 0x89, 0xB4, 0x9B, 0x28, 0xA3, 0x50, 0xD3, 0xED, 0x70,
		0x22, 0x27, 0x1B, 0xD5, 0x4F, 0x1C, 0x11, 0x9E, 0x9D, 0x08, 0xF6, 0xAA, 0x8B, 0x48, 0x2E, 0x56,
		0xCC, 0x9F, 0xBE, 0xC1, 0x8B, 0x9C, 0x90, 0x59, 0x8B, 0x77, 0x27, 0xBF, 0x4E, 0x95, 0x76, 0xD3,
		0x82, 0x5D, 0x78, 0x6A, 0x35, 0x95, 0x16, 0x43, 0x0C, 0xC1, 0x26, 0x86, 0x64, 0x0B, 0xC1, 0x21,
		0x78, 0x60, 0x3B, 0x82, 0xBC, 0xF2, 0x46, 0x37, 0x7B, 0xD7, 0x36, 0x5F, 0x06, 0xA4, 0x29, 0x58,
		0x56, 0x68, 0x65, 0x6D, 0x8C, 0xAC, 0x1F, 0x71, 0x62, 0x77, 0x2F, 0xA8, 0x0E, 0x14, 0x90, 0xB8,
		0x38, 0x60, 0x70, 0xC3, 0xB7, 0x07, 0xB1, 0x43, 0x21, 0x6B, 0x09, 0x52, 0x2B, 0x8F, 0x3D, 0x63,
		0x28, 0xF0, 0x4B, 0x2A, 0x82, 0x87, 0x61, 0xC8, 0x0B, 0xDB, 0xDF, 0x04, 0x1C, 0x82, 0x3D, 0xBA,
		0x55, 0xD5, 0xAD, 0xEF, 0x34, 0xEB, 0xF4, 0x68, 0x27, 0x9D, 0x21, 0x98, 0xF9, 0x6F, 0x2A, 0xC9,
		0x11, 0x75, 0x72, 0x01, 0xC0, 0xC9, 0xC3, 0x73, 0xB7, 0x21, 0x88, 0xE8, 0x78, 0xC0, 0x06, 0xAB,
		0x9A, 0xE3, 0xCB, 0xB4, 0xDB, 0x5E, 0xC5, 0x35, 0xAB, 0x2B, 0xBB, 0xA0, 0x54, 0xDB, 0x13, 0x82,
		0x06, 0x41, 0x8F, 0xAA, 0x9E, 0xBD, 0xFD, 0x8D, 0x32, 0x09, 0x2D, 0x14, 0xB4, 0x8D, 0xA3, 0x97,
		0xA8, 0x2E, 0x8D, 0x9C, 0x8F, 0x71, 0xED, 0x4D, 0x9E, 0xE5, 0xB5, 0x25, 0x77, 0x98, 0x00, 0xC9,
		0x16, 0xD4, 0x00, 0x01, 0x80, 0x0E, 0x47, 0xD7, 0xA9, 0xA8, 0x4F, 0x10, 0x46, 0xF4, 0xB2, 0xB6,
		0x7A, 0x15, 0xE8, 0x45, 0x4B, 0xB6, 0xB6, 0xB9, 0x96, 0x45, 0x89, 0x20, 0x62, 0xF2, 0xF0, 0xB8,
		0xE3, 0x39, 0xF6, 0xA6, 0xB1, 0x1A, 0xB2, 0x3C, 0x30, 0x3B, 0x3B, 0x48, 0x17, 0x01, 0xBD, 0x87,
		0x15, 0xB6, 0x79, 0x1B, 0xF7, 0x56, 0xD2, 0x11, 0x94, 0xB1, 0x01, 0xF9, 0xDE, 0xBF, 0xE9, 0x3E,
		0xC3, 0x8C, 0xFE, 0x34, 0xD7, 0x49, 0x32, 0x07, 0xFD, 0xDF, 0x34, 0x42, 0x34, 0x9A, 0x55, 0x3F,
		0xC4, 0x18, 0x2B, 0xB0, 0x9E, 0xE7, 0x95, 0xE7, 0xAD, 0x23, 0xBC, 0x90, 0x98, 0xCA, 0x95, 0x01,
		0x8B, 0x96, 0x6C, 0x71, 0xFA, 0x55, 0x20, 0x9B, 0x64, 0x64, 0xC8, 0x8B, 0xDE, 0xB6, 0xA9, 0xAD,
		0x2B, 0x5B, 0x16, 0xBB, 0x11, 0x29, 0x12, 0x23, 0xA7, 0x3A, 0x74, 0x7E, 0x60, 0x2B, 0xBB, 0x04,
		0x0C, 0xAF, 0xD7, 0xFE, 0x66, 0x93, 0x47, 0xD6, 0xAC, 0x7A, 0x6E, 0xCF, 0x4B, 0xBB, 0x90, 0xB9,
		0x07, 0x8E, 0xDD, 0x89, 0xFC, 0x33, 0x9A, 0x66, 0xE8, 0xE5, 0xCA, 0xAC, 0xDF, 0x66, 0x5A, 0x4B,
		0xD8, 0xC3, 0x26, 0x39, 0x5C, 0x90, 0x33, 0xB4, 0x03, 0x56, 0x6D, 0x2A, 0x51, 0x6D, 0x7D, 0x32,
		0xA0, 0x0F, 0x1A, 0xC0, 0x49, 0x49, 0x07, 0x5C, 0xF1, 0xDB, 0xE4, 0x8F, 0xCE, 0xAB, 0x56, 0x6B,
		0xE6, 0x5C, 0x49, 0x1E, 0x48, 0x75, 0x42, 0x1B, 0x67, 0xA7, 0x90, 0x7A, 0xFC, 0xD5, 0x85, 0x61,
		0xCE, 0xBF, 0x69, 0xB7, 0x69, 0x91, 0xE5, 0x4D, 0xA5, 0xB0, 0x01, 0x05, 0xB1, 0x93, 0x8E, 0x94,
		0x93, 0x57, 0xA6, 0x4A, 0x1A, 0x7A, 0x45, 0xB7, 0x41, 0xBF, 0xD3, 0x2E, 0xAF, 0xE3, 0x9A, 0x0B,
		0x74, 0x48, 0x24, 0x53, 0xE7, 0x47, 0x83, 0xE9, 0x39, 0xDA, 0x48, 0xF7, 0x07, 0x8A, 0x79, 0x7B,
		0x69, 0x26, 0x97, 0x28, 0x64, 0x76, 0x96, 0xD8, 0xCA, 0xAF, 0x12, 0x82, 0x3D, 0x24, 0x1E, 0x83,
		0xDA, 0xB9, 0xCD, 0xAD, 0xCD, 0x9D, 0x87, 0x88, 0x1E, 0x13, 0x03, 0x49, 0x1A, 0x87, 0x41, 0xE5,
		0xB1, 0x5E, 0x7B, 0x67, 0x3D, 0xBF, 0x5A, 0xB9, 0x69, 0x3A, 0x85, 0xFC, 0xC2, 0x3B, 0x28, 0x66,
		0x6B, 0xB8, 0x0B, 0x01, 0x19, 0x75, 0xE7, 0x03, 0xB1, 0xCD, 0x71, 0xE4, 0xC0, 0xE2, 0xEC, 0xEF,
		0xC1, 0x96, 0x32, 0x54, 0xFB, 0x2D, 0x9A, 0x12, 0x23, 0x43, 0x71, 0x3A, 0xBE, 0xF3, 0x24, 0x84,
		0x02, 0x46, 0x08, 0x51, 0xD0, 0x1F, 0xCC, 0xD7, 0x12, 0xFF, 0x00, 0xE4, 0x45, 0xAA, 0x9B, 0xFD,
		0x22, 0xF5, 0x4F, 0x2D, 0x09, 0x8C, 0xFE, 0x04, 0x91, 0xFD, 0x6B, 0xBE, 0xDB, 0xDA, 0xC7, 0x6E,
		0x5F, 0xCB, 0x18, 0x0C, 0x73, 0x8A, 0xE1, 0xFF, 0x00, 0xB7, 0x4B, 0x39, 0x7F, 0x75, 0x47, 0x2B,
		0xAF, 0xF8, 0x53, 0xFA, 0x48, 0xEE, 0x1B, 0x27, 0xFB, 0x56, 0x60, 0x57, 0xC9, 0x7D, 0x33, 0xD2,
		0x9B, 0xE0, 0xA2, 0xBE, 0xCF, 0x9F, 0xA8, 0xA2, 0x8A, 0x89, 0xD2, 0x14, 0x51, 0x45, 0x00, 0x14,
		0x51, 0x45, 0x00, 0x14, 0x51, 0x45, 0x00, 0x14, 0x51, 0x45, 0x00, 0x74, 0x44, 0x71, 0x0C, 0xB2,
		0xC5, 0x20, 0x63, 0x14, 0x9F, 0xE2, 0x77, 0x2A, 0x7D, 0xB2, 0x6B, 0xDB, 0x9F, 0x44, 0xFE, 0x5C,
		0x47, 0x76, 0xC2, 0x42, 0xBE, 0x30, 0x18, 0x75, 0xFF, 0x00, 0x83, 0xB5, 0x63, 0x1A, 0x6D, 0x68,
		0xD5, 0x98, 0xAA, 0xB9, 0xEB, 0xC6, 0x72, 0x0F, 0x6F, 0xF7, 0xA2, 0x75, 0xF3, 0x56, 0x31, 0x9F,
		0x2C, 0x05, 0x19, 0xF5, 0x64, 0x74, 0x03, 0x20, 0x0E, 0x07, 0x4A, 0x71, 0x08, 0xC1, 0x25, 0x79,
		0x04, 0x6A, 0xBB, 0x99, 0x72, 0xB1, 0x01, 0x8E, 0xB9, 0xEF, 0xF9, 0xD3, 0xB5, 0xD2, 0xA5, 0xD4,
		0x2D, 0x26, 0xB9, 0xBC, 0xBB, 0x8E, 0xD2, 0x71, 0x6E, 0x66, 0x89, 0x5D, 0x38, 0x9F, 0xD4, 0x40,
		0x52, 0xC3, 0xA1, 0x24, 0x3E, 0x33, 0xED, 0xCD, 0x28, 0xB6, 0xDE, 0xB7, 0x50, 0xCB, 0x13, 0x81,
		0x3A, 0xC8, 0x19, 0x32, 0x33, 0xEA, 0x07, 0x8F, 0x8F, 0xCE, 0x9B, 0x6A, 0xF1, 0xA6, 0x93, 0xE2,
		0x17, 0xD3, 0x6E, 0xA4, 0x86, 0xF8, 0x42, 0xC1, 0x65, 0x78, 0x66, 0x22, 0x39, 0x09, 0x19, 0x3F,
		0x42, 0xB9, 0x22, 0xB6, 0xCC, 0x15, 0xDE, 0x68, 0xB7, 0xD6, 0xF6, 0xA9, 0x76, 0xD1, 0x21, 0xB6,
		0x95, 0xF6, 0x2C, 0x91, 0xB8, 0x60, 0xCD, 0x8C, 0x91, 0xC7, 0xB0, 0x35, 0x6D, 0xB1, 0xD3, 0x57,
		0x45, 0xF0, 0xCD, 0xE4, 0x77, 0x49, 0x69, 0x71, 0x77, 0x24, 0xC9, 0x0B, 0x2B, 0x12, 0x42, 0x23,
		0x03, 0x86, 0xDD, 0xD0, 0xA9, 0xE0, 0x8E, 0x3B, 0xFB, 0x8A, 0xAF, 0xFD, 0xA2, 0x4B, 0x1D, 0x29,
		0x6D, 0x1A, 0x08, 0xB6, 0x4C, 0xCB, 0x28, 0x79, 0x23, 0x05, 0x88, 0x07, 0xA6, 0x73, 0xD3, 0x2A,
		0x38, 0x3E, 0xF4, 0xD6, 0x5B, 0xCD, 0x3A, 0x7F, 0x07, 0x04, 0x8A, 0x49, 0xFE, 0xD3, 0x25, 0xD2,
		0xC2, 0xF1, 0x87, 0x0F, 0xC0, 0x52, 0x50, 0xE3, 0x1B, 0x8E, 0x39, 0x19, 0xCF, 0xC7, 0x4A, 0xC9,
		0x5B, 0x54, 0x02, 0x6B, 0xDB, 0x05, 0x10, 0x2A, 0xCB, 0x93, 0x74, 0x4E, 0xED, 0xEA, 0xDE, 0x92,
		0x9C, 0xF2, 0x06, 0x06, 0x47, 0x7C, 0xE4, 0xF1, 0xED, 0x51, 0x2D, 0x99, 0x57, 0x7A, 0x5C, 0x46,
		0xB2, 0x06, 0xF5, 0x2E, 0x78, 0xC1, 0x18, 0xE4, 0x60, 0xF5, 0xC0, 0xC7, 0xB6, 0x0D, 0x5A, 0xE5,
		0xB7, 0x12, 0xDD, 0xDA, 0xF8, 0x73, 0x57, 0x57, 0x6D, 0x42, 0x27, 0x48, 0xED, 0xE5, 0x8A, 0x40,
		0xA5, 0x12, 0x45, 0x2D, 0x87, 0x24, 0xE0, 0x81, 0x90, 0xC7, 0x38, 0x23, 0x04, 0x55, 0x7F, 0x59,
		0xB4, 0x93, 0x4E, 0x9C, 0x46, 0xA4, 0x4B, 0x08, 0x55, 0x78, 0xE4, 0x60, 0x1A, 0x39, 0x41, 0xCE,
		0x19, 0x71, 0xC1, 0x52, 0x07, 0xE8, 0x73, 0x8C, 0x56, 0xAF, 0xD0, 0x18, 0x2B, 0xCA, 0x9E, 0x78,
		0x82, 0xD5, 0x1A, 0xDA, 0x7C, 0xC7, 0x2A, 0x63, 0x2A, 0x47, 0x50, 0xDD, 0x46, 0x08, 0x38, 0x23,
		0xE4, 0x55, 0x7D, 0xD4, 0x45, 0x39, 0x52, 0x08, 0x00, 0xF7, 0xEB, 0x56, 0x3B, 0xD7, 0xB4, 0xB0,
		0x68, 0x85, 0x81, 0x92, 0xE1, 0x25, 0x40, 0xD2, 0x43, 0x75, 0x16, 0x00, 0x18, 0x1D, 0x08, 0x3C,
		0xE7, 0xD5, 0xCF, 0x60, 0x71, 0x4A, 0x75, 0x7B, 0x2F, 0xB1, 0xDE, 0x60, 0x4B, 0x1C, 0x89, 0x28,
		0xF3, 0x13, 0x6C, 0xC2, 0x46, 0x00, 0xF4, 0x0C, 0x47, 0xF3, 0x53, 0xC4, 0x49, 0x22, 0x14, 0xD1,
		0x18, 0xE5, 0x2A, 0x01, 0x00, 0xF2, 0x01, 0x1D, 0x29, 0xD6, 0x8D, 0x32, 0x40, 0xD3, 0x3B, 0xC2,
		0xD2, 0x00, 0x10, 0xB1, 0x89, 0xB0, 0x42, 0x87, 0x04, 0xE0, 0xF6, 0xCF, 0x4A, 0x84, 0xFB, 0xA4,
		0x86, 0x17, 0x61, 0xE9, 0xCE, 0xD2, 0x48, 0x27, 0x07, 0xFD, 0xF8, 0xA9, 0xFA, 0x6D, 0xB1, 0x91,
		0xE6, 0x0B, 0x2B, 0xA9, 0xFB, 0xA3, 0x6E, 0x48, 0x07, 0xB0, 0xE3, 0xBE, 0x40, 0xFA, 0x56, 0xBE,
		0x89, 0x51, 0x22, 0x2B, 0xA6, 0xB3, 0x33, 0xA4, 0xD1, 0x83, 0x2C, 0x44, 0x08, 0xCF, 0x0F, 0x1B,
		0x27, 0x25, 0x81, 0x5E, 0x84, 0x63, 0x07, 0x8F, 0x7A, 0xBD, 0xE9, 0x73, 0xD9, 0xDB, 0xDC, 0xDE,
		0x59, 0x6E, 0x87, 0x6C, 0x41, 0xA3, 0x91, 0xA3, 0x87, 0x01, 0x94, 0x1C, 0xC7, 0x20, 0x07, 0x3C,
		0xE1, 0x80, 0xDC, 0x41, 0xEB, 0xCE, 0x41, 0xAA, 0x85, 0xB1, 0xB5, 0x55, 0x6B, 0x89, 0xD5, 0x9F,
		0xD4, 0x4B, 0x28, 0x1B, 0xB3, 0x29, 0x5D, 0xAC, 0xAC, 0x32, 0x08, 0xEE, 0x78, 0xEE, 0x3F, 0x1A,
		0xC6, 0xCA, 0xFE, 0xE6, 0xC2, 0xFA, 0x2B, 0xA7, 0x79, 0xD3, 0xCB, 0xC4, 0x7B, 0x10, 0x28, 0xF4,
		0xF0, 0xE3, 0x39, 0x04, 0x1C, 0xAE, 0x6A, 0x72, 0x87, 0x34, 0x6D, 0xD1, 0x75, 0xD5, 0xAC, 0xE4,
		0x8A, 0xD1, 0xFC, 0xB8, 0x24, 0x8E, 0x28, 0xC0, 0x72, 0x11, 0x8B, 0x34, 0x8C, 0x14, 0x2A, 0x30,
		0x5E, 0x85, 0x0F, 0x60, 0xBC, 0x8C, 0x9C, 0x74, 0x38, 0x4B, 0xAB, 0x2D, 0x9A, 0x19, 0x41, 0xB4,
		0xFE, 0x36, 0x19, 0xD8, 0x45, 0x13, 0x27, 0x95, 0xB8, 0x2E, 0xD5, 0x05, 0x89, 0x25, 0x42, 0xE4,
		0x61, 0xB8, 0x07, 0x38, 0xA8, 0x31, 0x6B, 0xD7, 0x1A, 0x4D, 0xD5, 0xFE, 0x8F, 0xA9, 0xC4, 0xE6,
		0x09, 0x77, 0x29, 0x57, 0x6C, 0x3A, 0xAB, 0x1D, 0xEB, 0x86, 0x19, 0xE3, 0x90, 0x70, 0x38, 0xE4,
		0xE2, 0xA6, 0x5C, 0xDF, 0x2D, 0xF6, 0x8A, 0x90, 0x7D, 0xB2, 0x17, 0x82, 0xDA, 0x4D, 0xF1, 0xAB,
		0xDC, 0x6E, 0x90, 0x96, 0x00, 0x6D, 0xE4, 0x03, 0x9E, 0xBF, 0x1C, 0x54, 0x92, 0x94, 0x7B, 0x16,
		0x52, 0x29, 0xD2, 0x5A, 0x4A, 0x92, 0xA0, 0x93, 0x00, 0xB0, 0x24, 0x8C, 0xE3, 0x1C, 0x9F, 0xCA,
		0x9E, 0xE9, 0xEE, 0x6D, 0xDE, 0x09, 0x04, 0x8A, 0x15, 0xA4, 0x6C, 0x15, 0x51, 0xB4, 0x65, 0x46,
		0x1B, 0xDF, 0x83, 0x9E, 0x31, 0xDB, 0x8A, 0x8D, 0xAE, 0x6A, 0x1A, 0x4B, 0x45, 0x07, 0xD9, 0x66,
		0x9A, 0x79, 0x81, 0x3B, 0xE4, 0x74, 0x23, 0x0B, 0xD9, 0x40, 0x3E, 0xC7, 0x77, 0x4E, 0xB9, 0xA5,
		0x03, 0x56, 0x58, 0xD1, 0xD2, 0x34, 0x62, 0x18, 0x82, 0x73, 0x8E, 0x71, 0x54, 0x50, 0x94, 0x97,
		0x44, 0xB9, 0x16, 0x3B, 0xC5, 0x8A, 0xC2, 0x2B, 0xA9, 0x19, 0x96, 0x59, 0xA7, 0x67, 0x58, 0x9F,
		0x90, 0x15, 0x73, 0xCB, 0x83, 0x9C, 0x9C, 0x8E, 0x39, 0xAA, 0xA4, 0xEE, 0x09, 0x20, 0x57, 0x97,
		0x17, 0x93, 0x5D, 0xB6, 0xE9, 0x58, 0x9C, 0x0C, 0x01, 0x9E, 0x83, 0xDA, 0xB4, 0xFD, 0xEA, 0xEA,
		0xC7, 0x0E, 0x3D, 0x90, 0x93, 0xB0, 0x15, 0x9A, 0xD6, 0xD2, 0xBB, 0xA1, 0x52, 0x3F, 0x94, 0x60,
		0xFD, 0x72, 0x6B, 0x00, 0x39, 0xAB, 0x21, 0x1B, 0x25, 0x45, 0x0B, 0x79, 0x62, 0x4E, 0xC4, 0xE0,
		0x53, 0xB8, 0x91, 0x53, 0x64, 0x80, 0x1D, 0x8C, 0xA7, 0x77, 0xC3, 0x54, 0x7D, 0x31, 0xED, 0x52,
		0xDC, 0x25, 0xD1, 0x6D, 0x86, 0x68, 0xC3, 0x6D, 0xEA, 0x14, 0x9C, 0x31, 0x1F, 0x85, 0x4B, 0x78,
		0xA3, 0x5D, 0x42, 0x78, 0x63, 0x6D, 0xF1, 0x05, 0x75, 0x56, 0x03, 0xEF, 0x0C, 0x90, 0xBF, 0x9E,
		0x05, 0x35, 0x9C, 0xF2, 0x4C, 0x73, 0xA2, 0x28, 0xB8, 0x89, 0xE3, 0x92, 0xDD, 0x48, 0x0A, 0x26,
		0x69, 0x09, 0x2B, 0xC7, 0xDD, 0xC7, 0x1D, 0xF3, 0x4D, 0x34, 0x79, 0x23, 0x8A, 0xE5, 0x75, 0x29,
		0xE5, 0xCA, 0x45, 0x26, 0xD6, 0x42, 0x72, 0x33, 0xC8, 0x52, 0x01, 0xE0, 0x63, 0x27, 0xAF, 0xBE,
		0x69, 0x36, 0x83, 0x2C, 0x4F, 0xA6, 0x6A, 0xAD, 0x2A, 0xC9, 0x96, 0x8C, 0x47, 0x94, 0x19, 0x09,
		0x9C, 0xE0, 0x9F, 0xC7, 0x00, 0x56, 0x56, 0x37, 0x7F, 0x62, 0xB3, 0xB9, 0xB7, 0xBB, 0xB7, 0x2C,
		0x24, 0xE0, 0x33, 0x29, 0xCF, 0x1D, 0x7F, 0xB5, 0x2F, 0x17, 0x2B, 0x48, 0xC4, 0xF8, 0x34, 0xD8,
		0xCF, 0xC4, 0x2C, 0x65, 0x79, 0x26, 0x74, 0x31, 0x5D, 0xC7, 0x27, 0x97, 0x2C, 0x5B, 0x40, 0x51,
		0xD8, 0x15, 0xE7, 0xD8, 0x1C, 0xFD, 0x45, 0x5C, 0xBC, 0x1B, 0x7E, 0xD1, 0xC9, 0x01, 0x70, 0xAB,
		0x02, 0x44, 0x4C, 0x87, 0x1D, 0xF6, 0xE4, 0xFE, 0x3C, 0x52, 0x3D, 0x1F, 0x42, 0x9B, 0x5A, 0x49,
		0xA7, 0x56, 0xDC, 0x37, 0xED, 0x78, 0xD4, 0xE5, 0xB0, 0x40, 0x2A, 0x73, 0xF1, 0x9A, 0xB5, 0x5C,
		0x58, 0x36, 0x83, 0xA0, 0xDC, 0x15, 0xCB, 0x3C, 0x6E, 0x91, 0xC6, 0x14, 0x67, 0x27, 0x21, 0x89,
		0xFA, 0xF0, 0x6A, 0x19, 0x67, 0x16, 0x96, 0x35, 0xD9, 0xD3, 0xE9, 0xF1, 0x4D, 0x4D, 0xE5, 0xF0,
		0x5B, 0x21, 0xD4, 0xE1, 0xB9, 0x9C, 0x47, 0x16, 0x59, 0x48, 0xC9, 0x70, 0x3D, 0x3D, 0x32, 0x39,
		0xAE, 0x77, 0xFB, 0x71, 0xB7, 0x49, 0xFC, 0x0B, 0x2C, 0xAA, 0x32, 0xF1, 0x4A, 0xA1, 0xB1, 0xDB,
		0xFE, 0x66, 0x9E, 0xF8, 0x46, 0x34, 0xD5, 0x5A, 0x5D, 0x45, 0xD9, 0x49, 0xE0, 0x15, 0x51, 0xE9,
		0xCF, 0xF6, 0xA5, 0x5F, 0xB5, 0x9B, 0x72, 0xFE, 0x1A, 0xD4, 0x07, 0x50, 0xF0, 0x6E, 0x03, 0xD8,
		0x83, 0xD6, 0x93, 0x0C, 0x2B, 0x2A, 0x89, 0xDF, 0x2C, 0x8E, 0x58, 0xB9, 0x34, 0x7C, 0x9F, 0x45,
		0x14, 0x57, 0x31, 0xDA, 0x14, 0x51, 0x45, 0x00, 0x14, 0x51, 0x45, 0x00, 0x14, 0x51, 0x45, 0x00,
		0x14, 0x51, 0x45, 0x00, 0x74, 0x19, 0x1C, 0x98, 0x8E, 0xEF, 0x44, 0x4C, 0x77, 0xAA, 0xE4, 0x31,
		0xCF, 0x7F, 0xF9, 0xC5, 0x69, 0x12, 0x4A, 0x8F, 0x91, 0x9E, 0x98, 0x0B, 0xD7, 0x83, 0xFF, 0x00,
		0xBA, 0xD2, 0x0B, 0x6D, 0xC6, 0x78, 0xC6, 0x31, 0x5B, 0x63, 0x8D, 0x85, 0xCF, 0x96, 0xAE, 0xBC,
		0xFA, 0x81, 0x04, 0x81, 0x9C, 0x64, 0x63, 0xBD, 0x51, 0x22, 0x66, 0x9D, 0xEF, 0x19, 0xE4, 0x10,
		0x18, 0x77, 0xE8, 0x6A, 0x6C, 0xB1, 0x16, 0xB1, 0x86, 0xF5, 0xC7, 0x04, 0x18, 0xF0, 0x47, 0xDE,
		0x23, 0x3F, 0xDB, 0xFA, 0x56, 0x32, 0xDC, 0x24, 0xA0, 0x37, 0xF1, 0x04, 0x88, 0x02, 0xA1, 0x6E,
		0x08, 0x00, 0x74, 0xC7, 0x4E, 0x39, 0xA6, 0xB7, 0xFB, 0x61, 0xF0, 0xCE, 0x94, 0xE2, 0x76, 0xB8,
		0x17, 0x08, 0xEC, 0x23, 0x24, 0x85, 0xB7, 0x64, 0x72, 0x18, 0x0F, 0x7C, 0x83, 0xD7, 0xE4, 0xD6,
		0x80, 0x5D, 0xC2, 0x75, 0x9B, 0x6B, 0x0B, 0x95, 0x8E, 0x15, 0x62, 0xA9, 0x03, 0xAC, 0x47, 0xD4,
		0xCE, 0x01, 0x03, 0xD2, 0x39, 0xC9, 0x0A, 0x3A, 0x03, 0xC9, 0x14, 0x8E, 0x0F, 0x36, 0xCB, 0x53,
		0x40, 0xCC, 0xD1, 0x4B, 0x1C, 0x8A, 0x47, 0xF9, 0x90, 0x83, 0xC7, 0xD0, 0x8A, 0xB5, 0xE8, 0xBA,
		0xE4, 0xF6, 0x90, 0xDB, 0x37, 0xEE, 0xF4, 0x82, 0xCF, 0xD4, 0xB0, 0xDC, 0xC6, 0x32, 0xD1, 0xCA,
		0x02, 0x06, 0x75, 0x63, 0xD1, 0xB8, 0x1F, 0x03, 0x35, 0x52, 0xBC, 0x33, 0x7D, 0xA9, 0xAE, 0x65,
		0xDF, 0xBE, 0x47, 0x32, 0x6E, 0x61, 0xD4, 0xE7, 0x39, 0x07, 0xBF, 0x35, 0xAB, 0xBA, 0x02, 0xED,
		0xAB, 0x45, 0x73, 0xA9, 0xF8, 0xDF, 0x56, 0xB6, 0xB3, 0x58, 0xEE, 0x9A, 0x53, 0x24, 0xD9, 0x27,
		0x2D, 0x26, 0xDF, 0x56, 0xD1, 0xF3, 0x91, 0xC7, 0xD3, 0x1C, 0x8A, 0x47, 0x68, 0xB2, 0x6A, 0xD7,
		0xE7, 0x4D, 0xB4, 0xB4, 0x87, 0x74, 0xD0, 0x34, 0x71, 0x07, 0x62, 0x30, 0xCB, 0x97, 0x0D, 0x81,
		0xFC, 0xC0, 0x65, 0x47, 0x6A, 0xF3, 0x48, 0xD7, 0xFE, 0xC5, 0x71, 0xA7, 0xBC, 0x68, 0xAE, 0xF1,
		0x4A, 0x43, 0xAB, 0xA6, 0xED, 0xCA, 0x48, 0xEE, 0x0E, 0x49, 0xE3, 0xB6, 0x3A, 0x0A, 0xDF, 0xAB,
		0x89, 0xB4, 0x4F, 0x1D, 0x5C, 0x16, 0xBA, 0x5F, 0x3A, 0xDA, 0x7C, 0xA4, 0xCA, 0xBE, 0x92, 0x07,
		0x20, 0xE0, 0x1E, 0xE3, 0xB7, 0xE1, 0x4A, 0x93, 0x5A, 0x60, 0x2A, 0x75, 0x85, 0x74, 0x7B, 0x79,
		0x9E, 0xE5, 0x5A, 0xE9, 0x67, 0x78, 0x64, 0xB5, 0xD9, 0x86, 0x8A, 0x31, 0xC8, 0x39, 0xF9, 0x25,
		0xBF, 0x23, 0x4A, 0xBE, 0xD0, 0x45, 0xB8, 0xB7, 0x0A, 0xBB, 0x3C, 0xC2, 0xE4, 0xF7, 0x27, 0x18,
		0x1F, 0x97, 0x3F, 0x99, 0xA6, 0xBA, 0xEB, 0xC3, 0x7D, 0xA9, 0xCF, 0x77, 0x6B, 0x6D, 0xF6, 0x78,
		0xA5, 0x7F, 0x54, 0x60, 0xFA, 0x51, 0xC8, 0xC9, 0x0B, 0xEC, 0x39, 0xE9, 0xF1, 0x49, 0xE5, 0x46,
		0x53, 0xEA, 0xEC, 0x3A, 0xD5, 0x17, 0x44, 0xD9, 0x36, 0x01, 0x98, 0x1F, 0x69, 0x00, 0xA9, 0x0C,
		0x09, 0x1D, 0x31, 0xFE, 0xF5, 0xBA, 0xCE, 0xEE, 0x5B, 0x6B, 0xD8, 0xE7, 0xCB, 0x0D, 0xA4, 0x31,
		0xD8, 0x46, 0x5B, 0xE9, 0x50, 0xAD, 0x9C, 0x84, 0x74, 0xE3, 0x18, 0xEA, 0x46, 0x71, 0x44, 0x61,
		0x97, 0x25, 0x48, 0xC2, 0xFC, 0x1A, 0xDA, 0x14, 0x6D, 0x6D, 0x79, 0x66, 0x61, 0x7F, 0xB6, 0x47,
		0xE7, 0xB0, 0x9B, 0xCC, 0x45, 0x3D, 0x70, 0x55, 0x81, 0xC9, 0xC7, 0xB8, 0x53, 0x8A, 0x69, 0x05,
		0xD4, 0x49, 0xE1, 0xAD, 0x65, 0xB4, 0xF5, 0x5F, 0xE0, 0x49, 0x1B, 0x19, 0x25, 0x55, 0xC8, 0x0C,
		0x5A, 0x2C, 0x21, 0x03, 0x3E, 0xA5, 0x63, 0x9C, 0xE3, 0x18, 0xE3, 0x9A, 0x40, 0xF6, 0xD2, 0x45,
		0xE4, 0xB6, 0xD2, 0xA2, 0x45, 0xCA, 0x71, 0xC7, 0x53, 0x8F, 0xE9, 0x56, 0xED, 0x3B, 0x43, 0x17,
		0x9A, 0x4E, 0xB0, 0x20, 0x67, 0x9D, 0x56, 0xC4, 0x98, 0x95, 0x62, 0x19, 0x2C, 0x8F, 0xBC, 0x1E,
		0xBD, 0x94, 0x83, 0xDC, 0xF2, 0x45, 0x63, 0xA3, 0x15, 0x95, 0x0D, 0x41, 0x45, 0xD3, 0xDB, 0xA5,
		0xB3, 0xCD, 0x2A, 0x2C, 0x08, 0x8B, 0xE6, 0xE3, 0x2A, 0xD8, 0xCB, 0x28, 0xF8, 0xDC, 0x58, 0x8F,
		0xAD, 0x2D, 0xC3, 0xC3, 0x21, 0x07, 0x3B, 0x81, 0xAE, 0x89, 0x20, 0xD3, 0xBF, 0xFC, 0x39, 0xA0,
		0x96, 0xB7, 0x51, 0x17, 0x94, 0xE9, 0x71, 0x7B, 0x12, 0x12, 0xA2, 0x42, 0x72, 0xA0, 0x80, 0x46,
		0x1C, 0x70, 0x09, 0xEE, 0x0F, 0x19, 0x02, 0xAB, 0x56, 0xFA, 0x53, 0xEB, 0x7A, 0xE5, 0xB6, 0x9D,
		0x0B, 0xAA, 0x5C, 0xCB, 0xE8, 0x63, 0x21, 0x3C, 0x30, 0x07, 0x39, 0x38, 0xF8, 0xA6, 0x8C, 0x89,
		0x4A, 0x02, 0x58, 0xC8, 0x73, 0xB5, 0xFB, 0xD6, 0xB6, 0x42, 0x87, 0x14, 0xC6, 0x6D, 0x34, 0xDB,
		0x5B, 0xC1, 0x71, 0x20, 0x3E, 0x54, 0xE5, 0x84, 0x6C, 0x07, 0x0D, 0xB7, 0x19, 0xC1, 0xF8, 0x24,
		0x0A, 0x8E, 0xEA, 0x25, 0x5C, 0x03, 0x92, 0x2A, 0x89, 0x90, 0xA6, 0x88, 0xE8, 0xA7, 0x9A, 0x99,
		0x6F, 0x6E, 0x24, 0x02, 0x3C, 0xFA, 0x9C, 0xF5, 0xEC, 0x2B, 0x2B, 0x4B, 0x7D, 0xEA, 0xEA, 0xDD,
		0xC7, 0x14, 0xE6, 0xE3, 0x4B, 0x9E, 0xDC, 0x45, 0x20, 0xDC, 0x37, 0x23, 0x3F, 0xA4, 0x7B, 0x67,
		0x9F, 0xD2, 0x9A, 0xD7, 0x42, 0x34, 0xC8, 0x10, 0x5B, 0x3D, 0xD5, 0xB5, 0xF1, 0x5D, 0xAA, 0xB6,
		0xD1, 0xF9, 0x87, 0x03, 0x3B, 0x81, 0x60, 0x3F, 0xE7, 0xD2, 0xA1, 0x6C, 0xC8, 0xFE, 0xD4, 0xF7,
		0x45, 0x8C, 0xDC, 0xDC, 0xDD, 0x45, 0x23, 0x2A, 0xF9, 0x76, 0x92, 0xED, 0x0E, 0x7E, 0xF9, 0x03,
		0x85, 0xE3, 0xFE, 0x71, 0x58, 0x5B, 0x69, 0x3E, 0x75, 0xDF, 0x90, 0xD9, 0x46, 0xDC, 0x47, 0x4C,
		0xD3, 0x29, 0x57, 0x62, 0x38, 0xF9, 0x41, 0x63, 0x14, 0x0C, 0x84, 0xB1, 0x27, 0xD1, 0xC8, 0xC7,
		0x42, 0x0F, 0xFE, 0x33, 0x5B, 0xED, 0x61, 0x36, 0xF7, 0x4C, 0xE4, 0xB1, 0xFE, 0x1B, 0xE5, 0x7A,
		0x0C, 0x81, 0x9E, 0x94, 0xDE, 0xDE, 0xC2, 0x3B, 0x76, 0xFB, 0x3C, 0xF0, 0x86, 0x71, 0xC2, 0xCA,
		0x8C, 0x0E, 0x47, 0xD2, 0x98, 0xDC, 0xE9, 0x76, 0x50, 0xC7, 0x17, 0xD9, 0xCF, 0x99, 0x33, 0x1F,
		0xBB, 0xF1, 0xB7, 0x9E, 0x7F, 0x2A, 0x5F, 0x76, 0x37, 0x46, 0x3C, 0x6C, 0xD5, 0xE1, 0x1D, 0x3A,
		0x5B, 0xAB, 0x4D, 0x52, 0x08, 0x98, 0x47, 0x33, 0xC4, 0xAF, 0x1C, 0x8D, 0xF7, 0x57, 0x6B, 0x6E,
		0x39, 0xFA, 0x81, 0x8A, 0xB5, 0xF8, 0x6F, 0xC2, 0x4D, 0xAE, 0x19, 0x4E, 0xA8, 0x25, 0x85, 0xE0,
		0x65, 0xDE, 0x9B, 0x70, 0x24, 0x07, 0x39, 0x20, 0xFC, 0xFB, 0xD4, 0x6F, 0x05, 0xDA, 0xC5, 0x1D,
		0x9E, 0xAA, 0x0B, 0x14, 0xBC, 0x7B, 0x72, 0x51, 0xB6, 0xE4, 0xAA, 0xAF, 0x24, 0x60, 0xF1, 0xCF,
		0x15, 0x7A, 0xF0, 0x4E, 0xB8, 0x35, 0x9F, 0x0E, 0x89, 0x64, 0x6F, 0xE3, 0x43, 0x21, 0x86, 0x4C,
		0xA8, 0x5C, 0x1E, 0xDC, 0x74, 0xEF, 0x5C, 0xF9, 0x32, 0x49, 0x37, 0xC4, 0xEB, 0xC1, 0x82, 0x32,
		0xAE, 0x62, 0xEB, 0x5D, 0x22, 0xE7, 0xC3, 0x77, 0x3E, 0x65, 0xBD, 0xE2, 0x28, 0x79, 0xB3, 0x2C,
		0x1B, 0x72, 0x8F, 0x11, 0xCE, 0x39, 0xEA, 0xB8, 0xC5, 0x44, 0xD5, 0xB5, 0xA9, 0x63, 0xB2, 0x8A,
		0xDA, 0x64, 0xDD, 0x3E, 0xF6, 0x91, 0x98, 0x30, 0xDA, 0x18, 0x31, 0x23, 0x38, 0xEB, 0xE9, 0x34,
		0xFF, 0x00, 0x5D, 0xD4, 0x2C, 0xA7, 0xD3, 0xE4, 0x92, 0x29, 0xA3, 0x79, 0xED, 0x1B, 0x78, 0x00,
		0xE7, 0x91, 0x8D, 0xCA, 0x7E, 0x08, 0x6C, 0x1A, 0xA0, 0xDB, 0xE9, 0x12, 0xBE, 0x99, 0x70, 0xF2,
		0xB3, 0x43, 0x34, 0x73, 0x6E, 0x2C, 0x4E, 0xED, 0xAA, 0x54, 0xE0, 0x90, 0x3D, 0xF0, 0x06, 0x7E,
		0x94, 0xB8, 0x92, 0x93, 0xE5, 0x36, 0x53, 0x2D, 0xE3, 0x5C, 0x71, 0x97, 0x2F, 0x07, 0xC3, 0x16,
		0xEB, 0x89, 0xA0, 0x52, 0x23, 0x23, 0x6E, 0x59, 0xB3, 0x9C, 0x37, 0x1F, 0x4E, 0x2B, 0x67, 0xED,
		0x06, 0xDD, 0x65, 0xF0, 0x5E, 0xA6, 0xC7, 0x3C, 0x5B, 0xBF, 0x18, 0xF8, 0xAC, 0x3C, 0x1F, 0x6D,
		0x24, 0x4A, 0x5C, 0xC7, 0xE5, 0xC4, 0x63, 0x18, 0x1B, 0xF3, 0x87, 0x1D, 0x7F, 0x30, 0x6A, 0x67,
		0x8B, 0xCA, 0x5C, 0x78, 0x4F, 0x56, 0x88, 0x37, 0xA9, 0x61, 0x60, 0x40, 0xF7, 0xDB, 0x9A, 0x68,
		0x3F, 0xE7, 0x5F, 0xD8, 0xFA, 0x5E, 0x9D, 0xF8, 0x3E, 0x29, 0x6F, 0xBE, 0x7E, 0xB5, 0x8D, 0x6D,
		0x98, 0x6D, 0x99, 0xC7, 0xB3, 0x1A, 0xD5, 0x51, 0x92, 0xA6, 0xCE, 0xB5, 0xD0, 0x51, 0x45, 0x14,
		0xA6, 0x85, 0x14, 0x51, 0x40, 0x05, 0x14, 0x51, 0x40, 0x05, 0x14, 0x51, 0x40, 0x17, 0x95, 0x98,
		0xED, 0x08, 0x7A, 0x2F, 0xDD, 0xE2, 0x9E, 0x4F, 0xA8, 0xD8, 0xDB, 0xDD, 0x69, 0xD7, 0x31, 0x58,
		0x48, 0xF1, 0x45, 0x1B, 0xF1, 0x24, 0xB9, 0xDC, 0xC4, 0x9C, 0x72, 0x07, 0xF2, 0x92, 0x0F, 0xCF,
		0xD2, 0x93, 0xCF, 0x6D, 0x24, 0x44, 0xE5, 0x08, 0xFA, 0xD6, 0x96, 0x67, 0x65, 0x00, 0xE7, 0x0B,
		0xD0, 0x55, 0x52, 0x4C, 0x99, 0xB6, 0xFA, 0x46, 0x9E, 0xF6, 0x5B, 0x91, 0x17, 0x96, 0x93, 0xB1,
		0x95, 0x53, 0x71, 0x6C, 0x02, 0x7D, 0xCF, 0x5A, 0x61, 0x1C, 0x17, 0xF7, 0xDA, 0x6C, 0x51, 0xBB,
		0x13, 0x67, 0x6B, 0xB9, 0x10, 0x33, 0x00, 0xAB, 0xB8, 0xEE, 0x38, 0xF9, 0x35, 0x14, 0x5F, 0x4B,
		0x25, 0x9D, 0xBD, 0xB6, 0xD4, 0x09, 0x0E, 0xF5, 0x05, 0x47, 0xA9, 0x83, 0x1C, 0xF2, 0x7B, 0xE3,
		0x1C, 0x7D, 0x4D, 0x31, 0xB6, 0xBC, 0x80, 0xDA, 0xDB, 0xDA, 0x46, 0x8F, 0x20, 0x0E, 0xF2, 0x3B,
		0x03, 0xCE, 0x48, 0xC6, 0xDC, 0x7E, 0x54, 0x3B, 0x5D, 0x1A, 0xAB, 0xC9, 0x33, 0xC3, 0x1A, 0x20,
		0xBC, 0x49, 0x66, 0x9E, 0x57, 0xF2, 0xAD, 0xC8, 0x65, 0x50, 0x40, 0xDF, 0xD7, 0xD2, 0x33, 0x9C,
		0x12, 0x76, 0xF6, 0xC6, 0x29, 0xA7, 0x8A, 0x21, 0xD3, 0xF5, 0x69, 0xAD, 0x34, 0x8D, 0x28, 0x45,
		0x6E, 0xD6, 0xB6, 0xA6, 0x6D, 0xB2, 0xCD, 0xC3, 0x3B, 0x82, 0xEE, 0xA0, 0xB7, 0x4C, 0x60, 0xF1,
		0xDC, 0x9E, 0x38, 0xA9, 0xDA, 0xFD, 0xD4, 0x5A, 0x0F, 0x80, 0xF4, 0x5D, 0x3C, 0x5B, 0x34, 0x57,
		0x57, 0x72, 0x3D, 0xD4, 0xD1, 0x3A, 0x18, 0xCA, 0xA1, 0xC8, 0xDA, 0xE3, 0xA9, 0xE7, 0x04, 0x1F,
		0xF4, 0xF6, 0xAE, 0x7F, 0x72, 0x73, 0x32, 0x34, 0x45, 0xB8, 0x5E, 0x77, 0x0E, 0x79, 0x39, 0xFC,
		0x78, 0x34, 0xA9, 0x36, 0xED, 0x9B, 0x6A, 0xA8, 0xDD, 0x61, 0x0D, 0xE6, 0x93, 0xA9, 0x5B, 0xDC,
		0x79, 0x2C, 0xB2, 0xAE, 0xD9, 0xA2, 0x2C, 0x9C, 0x30, 0xEA, 0x0E, 0x0F, 0x50, 0x6A, 0x7F, 0x88,
		0x6F, 0x12, 0x7D, 0x56, 0xF6, 0xEA, 0xEA, 0xD3, 0x7A, 0xCE, 0x8C, 0xB6, 0xEA, 0x1B, 0x6F, 0x94,
		0x49, 0xCA, 0xE7, 0x03, 0x07, 0x1C, 0xFD, 0x6B, 0x7A, 0x6B, 0x37, 0xBA, 0xE2, 0x69, 0xD0, 0x4F,
		0xFE, 0x16, 0x99, 0x6F, 0xE5, 0x2F, 0x96, 0xA7, 0xD3, 0x18, 0xEA, 0xCD, 0xFA, 0x64, 0xFD, 0x29,
		0xC6, 0xBF, 0xAB, 0x78, 0x53, 0xF8, 0x48, 0x24, 0x7B, 0xB7, 0x8A, 0x20, 0x12, 0xDE, 0x31, 0x84,
		0x0E, 0x7A, 0x92, 0xDD, 0x7E, 0x6B, 0x25, 0x36, 0xA5, 0x54, 0x0A, 0x36, 0xAC, 0xD3, 0xA3, 0xEB,
		0x9E, 0x1D, 0xB0, 0xD0, 0x9E, 0xCE, 0xE3, 0xC3, 0x12, 0x5C, 0xCF, 0x73, 0x1A, 0xE2, 0x4B, 0x99,
		0x03, 0x06, 0x21, 0x48, 0x62, 0x87, 0x00, 0xA8, 0x2D, 0x8E, 0x01, 0xE9, 0xDE, 0xA9, 0x3A, 0xCD,
		0xF7, 0xEF, 0x0B, 0xD9, 0x67, 0x31, 0x47, 0x13, 0xBB, 0x96, 0x29, 0x12, 0xED, 0x45, 0xE0, 0x0E,
		0x14, 0x70, 0x3A, 0x55, 0x9A, 0xEF, 0xC4, 0x2C, 0x96, 0x56, 0xD0, 0x25, 0xB4, 0x17, 0x11, 0x2C,
		0xC9, 0x2C, 0x72, 0x30, 0x21, 0xD4, 0x22, 0x95, 0xF2, 0xF3, 0xED, 0xEA, 0xC9, 0xF7, 0xAA, 0xDE,
		0xB3, 0x04, 0x90, 0xEB, 0x17, 0x49, 0x32, 0x18, 0xE5, 0xDE, 0x59, 0xD1, 0x87, 0x20, 0x9E, 0x4F,
		0xF5, 0xAA, 0x47, 0xBB, 0x12, 0x5D, 0x1A, 0x34, 0xE3, 0x1B, 0x34, 0xAB, 0x21, 0xC0, 0x28, 0x79,
		0xAD, 0xF1, 0x34, 0x40, 0x49, 0x1B, 0x23, 0x12, 0x78, 0x5E, 0x38, 0xCF, 0xD2, 0xA0, 0xED, 0x0A,
		0x03, 0x06, 0xCE, 0x7F, 0x4A, 0xCD, 0x24, 0x64, 0x6C, 0xAD, 0x3D, 0x13, 0x63, 0xA8, 0xA1, 0xF2,
		0xF4, 0xD4, 0x3E, 0x63, 0x10, 0x00, 0xC8, 0x61, 0xB7, 0xA3, 0xE4, 0x6D, 0xF7, 0xEA, 0x79, 0xA6,
		0x9A, 0x53, 0x47, 0x7B, 0xA5, 0x4B, 0xA3, 0x2C, 0xCC, 0x93, 0x03, 0x3D, 0xE0, 0x2B, 0xCF, 0x22,
		0x30, 0x40, 0xC6, 0x3A, 0xE1, 0x4E, 0x79, 0xE7, 0x3F, 0x15, 0x5F, 0x26, 0x4B, 0xAB, 0x74, 0x77,
		0x90, 0x7F, 0x0D, 0x4F, 0x6F, 0xBB, 0xED, 0x4E, 0xF4, 0x2B, 0xB6, 0xD1, 0x75, 0x55, 0xBF, 0xC2,
		0xB2, 0x32, 0xB2, 0x4A, 0x7C, 0xBD, 0xC3, 0x63, 0x0D, 0xAE, 0x3E, 0x38, 0x27, 0xA5, 0x63, 0x5A,
		0x34, 0x97, 0xA0, 0xDD, 0xAA, 0xE8, 0xF7, 0xDA, 0x65, 0xD4, 0x4D, 0x35, 0x85, 0xC0, 0x66, 0x3E,
		0x5B, 0x60, 0xF9, 0x81, 0x4F, 0x96, 0xDF, 0x81, 0x19, 0xA4, 0xF7, 0xD2, 0x8B, 0x9D, 0x56, 0x4B,
		0xD9, 0x04, 0x90, 0x3C, 0x8D, 0xBF, 0x92, 0x49, 0xDD, 0xDC, 0xEE, 0xEF, 0xF5, 0xA7, 0x37, 0x73,
		0x7F, 0xD0, 0x69, 0x31, 0xDB, 0xD9, 0xAA, 0x8B, 0x8B, 0x71, 0x1A, 0x3A, 0xFA, 0x77, 0xB4, 0x72,
		0x30, 0x27, 0x1D, 0x08, 0x60, 0x57, 0x93, 0xED, 0xDA, 0x8B, 0xE4, 0xB7, 0xB7, 0x91, 0xE2, 0x8A,
		0x67, 0xB8, 0x88, 0x4E, 0xC6, 0x22, 0xD1, 0x90, 0xA6, 0x23, 0x82, 0xAC, 0x33, 0xF5, 0x23, 0xE3,
		0x6F, 0xCD, 0x65, 0xD0, 0xAD, 0x68, 0xC2, 0xD7, 0xC3, 0xB1, 0x6A, 0x77, 0x36, 0x10, 0xA1, 0x92,
		0xDE, 0xDA, 0x4C, 0xF9, 0x97, 0x0E, 0x09, 0x58, 0x81, 0xC9, 0xC8, 0xE7, 0xA7, 0x1F, 0x9D, 0x55,
		0x26, 0x87, 0x73, 0x1F, 0x28, 0x1D, 0x99, 0xE0, 0x9E, 0xF5, 0xD5, 0x74, 0xAF, 0x2B, 0xC4, 0x13,
		0xE9, 0x96, 0xD1, 0x4D, 0x0C, 0x16, 0xD1, 0x42, 0x20, 0x3B, 0x1C, 0x02, 0x58, 0x64, 0xEE, 0x20,
		0xF7, 0x24, 0xD2, 0x33, 0xA0, 0xB4, 0x17, 0x66, 0x13, 0x0A, 0x80, 0x79, 0xC7, 0xD3, 0x8A, 0xC8,
		0x65, 0x4A, 0xD3, 0x25, 0x28, 0x6B, 0x45, 0x36, 0x08, 0xA6, 0x5F, 0x57, 0x96, 0x59, 0x3B, 0xE2,
		0xAD, 0x97, 0x73, 0x35, 0x9C, 0x82, 0x39, 0x6D, 0x96, 0x2C, 0x59, 0x26, 0xF4, 0x3F, 0xCA, 0x59,
		0x73, 0x82, 0x0F, 0x7F, 0xE9, 0x53, 0xE0, 0xB6, 0x4B, 0x4D, 0x4E, 0x08, 0xE4, 0xB7, 0xDC, 0xAD,
		0x22, 0xE0, 0x01, 0xC1, 0xF5, 0x63, 0xFA, 0xD7, 0xBA, 0xC5, 0xB7, 0xEF, 0x2D, 0x52, 0xF7, 0x57,
		0x82, 0x1B, 0x69, 0x2D, 0xC9, 0x25, 0xD3, 0x7E, 0x37, 0xE5, 0x71, 0x8C, 0x9E, 0xFD, 0xC7, 0xC8,
		0xA7, 0xF7, 0x14, 0x85, 0xE0, 0xD0, 0xAB, 0x48, 0x8A, 0x1B, 0xD8, 0xB5, 0x4F, 0x20, 0x3C, 0x12,
		0xC1, 0x6A, 0xD2, 0x1D, 0x8C, 0x02, 0xC9, 0xC8, 0x1B, 0x79, 0xF7, 0xCD, 0x6E, 0xB0, 0xD4, 0xE4,
		0xB3, 0x9A, 0x2B, 0xC6, 0xB5, 0x26, 0x15, 0xE1, 0x9C, 0x0C, 0x85, 0xA8, 0xFE, 0x08, 0x1B, 0x75,
		0xD1, 0x14, 0xAA, 0x1D, 0x66, 0x89, 0xA0, 0x70, 0x4E, 0x33, 0xBC, 0x6D, 0x1F, 0xA9, 0x14, 0xC2,
		0xE6, 0x17, 0xB6, 0xD3, 0x2E, 0x7C, 0xEB, 0x69, 0x22, 0xB7, 0x8A, 0xE9, 0x61, 0x98, 0x06, 0xDD,
		0x83, 0xEE, 0x3E, 0x33, 0xD3, 0xE9, 0x4C, 0xD2, 0xE9, 0x8A, 0xE3, 0xAB, 0x35, 0x5F, 0xA8, 0x93,
		0x50, 0xF3, 0x74, 0xF5, 0xDD, 0x6C, 0xF1, 0x89, 0x0A, 0xAF, 0x44, 0xCF, 0x51, 0xF4, 0xAE, 0x85,
		0xA7, 0x69, 0x9A, 0x6D, 0xFF, 0x00, 0x86, 0x0D, 0xD4, 0x90, 0x34, 0x53, 0xC6, 0x0E, 0xC9, 0xF1,
		0xD5, 0x8F, 0x45, 0x1E, 0xF9, 0xA5, 0xDA, 0x4E, 0x9F, 0x69, 0x75, 0xE0, 0xA9, 0xEC, 0xE1, 0xBB,
		0xB6, 0x9A, 0x5B, 0x69, 0x5B, 0xEC, 0x97, 0x48, 0x09, 0x2C, 0x19, 0xB3, 0xB1, 0x97, 0x1C, 0x73,
		0xC7, 0x3C, 0x0E, 0xB4, 0xEF, 0xC1, 0x96, 0xB7, 0xDA, 0xB7, 0x85, 0x2F, 0x2D, 0xAF, 0xA5, 0x21,
		0xD2, 0xE0, 0x43, 0x19, 0xDA, 0x14, 0x05, 0x5C, 0x1C, 0x82, 0x07, 0x3F, 0x78, 0x8C, 0xD7, 0x3E,
		0x49, 0x72, 0x5F, 0x8B, 0xE8, 0xB6, 0x3C, 0x5B, 0x14, 0xE9, 0x16, 0x8E, 0x26, 0x68, 0xA1, 0x91,
		0xA1, 0x92, 0xE1, 0x52, 0xDF, 0xD2, 0xBD, 0x07, 0x39, 0x38, 0x3F, 0x9D, 0x56, 0x6E, 0xE1, 0xBA,
		0xD3, 0x0C, 0xDA, 0x7C, 0xB7, 0x13, 0x46, 0xAF, 0x2E, 0xF9, 0x50, 0x13, 0x8D, 0xCB, 0xD3, 0xEA,
		0x7E, 0x7E, 0x6B, 0xAA, 0x78, 0x76, 0x0B, 0x65, 0x81, 0xA6, 0xBD, 0x11, 0x8B, 0x94, 0x98, 0xC6,
		0xB2, 0x39, 0x18, 0x6F, 0x2C, 0x63, 0x72, 0xFC, 0x62, 0x96, 0x78, 0x80, 0x69, 0x7A, 0xA6, 0xB3,
		0x12, 0xC9, 0x10, 0x05, 0x1D, 0x56, 0x57, 0x71, 0xF7, 0x97, 0x91, 0x95, 0x23, 0xF0, 0xAD, 0xC5,
		0x9A, 0xBE, 0x48, 0x27, 0x85, 0xF1, 0xD3, 0x2A, 0xBE, 0x1F, 0xD4, 0xE4, 0xB4, 0xD4, 0xED, 0xA5,
		0x11, 0x45, 0x34, 0x13, 0x46, 0xEB, 0x34, 0x12, 0x75, 0x19, 0x1D, 0x77, 0x7C, 0xE2, 0xAF, 0x9E,
		0x19, 0xB1, 0x8F, 0x49, 0xF0, 0xB8, 0xBA, 0x92, 0xD6, 0x5F, 0x32, 0xE1, 0x04, 0xB2, 0xC2, 0x7D,
		0x4C, 0x8A, 0x7A, 0x2F, 0xE0, 0x3B, 0x7D, 0x6A, 0x8F, 0xA1, 0xDB, 0x45, 0x07, 0x89, 0x13, 0x74,
		0x4E, 0x6D, 0x86, 0x4F, 0x97, 0x2A, 0xE4, 0xE0, 0x92, 0x3F, 0x1C, 0x57, 0x58, 0xB0, 0x27, 0xEC,
		0x51, 0x6E, 0x88, 0x44, 0x42, 0xE3, 0x60, 0x6C, 0x81, 0xF8, 0xD3, 0xE6, 0x69, 0x4A, 0xA2, 0x3E,
		0x08, 0xBA, 0xD9, 0x8C, 0x31, 0xDA, 0x69, 0xB6, 0x6E, 0xF1, 0x22, 0xC5, 0x00, 0x1E, 0x61, 0xDA,
		0x3E, 0x3A, 0xD5, 0x3E, 0xF2, 0xE3, 0xED, 0x9A, 0x76, 0xB0, 0x50, 0x6E, 0x59, 0x64, 0x93, 0x6F,
		0xD3, 0xCB, 0xAD, 0xFE, 0x34, 0xD5, 0x8A, 0x1B, 0x7B, 0x34, 0x7D, 0xB1, 0xB3, 0x6E, 0x93, 0x1D,
		0xC7, 0x18, 0xFE, 0xA6, 0x96, 0xE8, 0xA9, 0x24, 0xDA, 0x7E, 0xA3, 0x10, 0x39, 0xD8, 0x0C, 0x84,
		0xFB, 0xE5, 0x48, 0xAB, 0xFA, 0x6C, 0x4D, 0x47, 0xDC, 0x64, 0xBD, 0x4C, 0xEE, 0x5E, 0xDA, 0x3E,
		0x52, 0xBB, 0x18, 0xBB, 0x94, 0x7F, 0xAC, 0xD6, 0x8A, 0x93, 0x7C, 0x31, 0x7D, 0x38, 0xFF, 0x00,
		0xF5, 0x0F, 0xF5, 0xA8, 0xD5, 0xCB, 0x97, 0xE6, 0xFF, 0x00, 0xB3, 0xB6, 0x1F, 0x14, 0x14, 0x51,
		0x45, 0x4C, 0x60, 0xA2, 0x8A, 0x28, 0x00, 0xA2, 0x8A, 0x28, 0x00, 0xA2, 0x8A, 0x28, 0x03, 0xB0,
		0x6B, 0x7A, 0x84, 0xC6, 0x5B, 0x8B, 0x6D, 0x4E, 0x09, 0x3E, 0xD0, 0xB6, 0xD0, 0xC7, 0x02, 0x86,
		0x01, 0x14, 0x01, 0x90, 0xC7, 0xB9, 0x3B, 0x48, 0xC7, 0xCF, 0x5A, 0xAC, 0x01, 0x9A, 0x79, 0xA9,
		0x6A, 0x13, 0xEA, 0x9A, 0xBD, 0xC5, 0xEB, 0xBE, 0xE7, 0x39, 0x45, 0x00, 0x0C, 0x2A, 0x01, 0x85,
		0x03, 0x8C, 0x60, 0x0E, 0x29, 0x44, 0xD6, 0xF3, 0x5B, 0x3E, 0xC9, 0xE2, 0x78, 0x9F, 0x00, 0xED,
		0x70, 0x41, 0xC7, 0x6E, 0x0D, 0x5A, 0x2A, 0x89, 0xB1, 0x8E, 0x81, 0x6D, 0x6F, 0x73, 0xAA, 0x24,
		0x37, 0x68, 0xEF, 0x6C, 0x41, 0x69, 0x3C, 0xBE, 0x1F, 0x0A, 0x32, 0x76, 0xE7, 0x8C, 0xE0, 0x1E,
		0xB5, 0x1A, 0xE1, 0x1B, 0x4F, 0xBF, 0x32, 0xDA, 0x33, 0xC2, 0x55, 0xC4, 0x91, 0xE4, 0xFA, 0x97,
		0x07, 0x2B, 0x93, 0x81, 0xCF, 0x4A, 0x65, 0xE1, 0xFD, 0x5E, 0xFF, 0x00, 0x46, 0x8E, 0xEE, 0x6B,
		0x3B, 0x7D, 0xC8, 0xD1, 0x6C, 0x96, 0x43, 0x16, 0xED, 0xA8, 0x58, 0x64, 0x64, 0x8E, 0x33, 0xD3,
		0xF1, 0xAD, 0x3A, 0xF6, 0xA6, 0x75, 0x5D, 0x5A, 0xE2, 0xF5, 0x6D, 0xE2, 0xB6, 0x13, 0x00, 0x3C,
		0xA8, 0x00, 0x55, 0x0A, 0x30, 0x00, 0xE3, 0xE9, 0x46, 0xD3, 0x0B, 0x2C, 0xFA, 0x01, 0x1F, 0xB4,
		0x3F, 0x14, 0xBC, 0xDE, 0x22, 0xBC, 0x65, 0x2B, 0x6C, 0xC5, 0x36, 0xE0, 0x28, 0xDB, 0xD8, 0xFB,
		0x0E, 0x73, 0xC7, 0x5A, 0xA9, 0x5C, 0x0B, 0x28, 0x34, 0xD9, 0x81, 0x86, 0x53, 0x76, 0xD2, 0x8F,
		0x2E, 0x50, 0xDB, 0x55, 0x55, 0x4B, 0x06, 0x04, 0x77, 0x27, 0x83, 0xC7, 0x4C, 0x56, 0x7A, 0x9D,
		0xFD, 0xA4, 0xF0, 0xE9, 0x96, 0x96, 0x31, 0x79, 0x69, 0x6B, 0x6E, 0x11, 0xE4, 0x20, 0x06, 0x96,
		0x56, 0x39, 0x66, 0x3F, 0x19, 0x38, 0x1F, 0x02, 0xAF, 0x7E, 0x2C, 0xD1, 0x6C, 0xAC, 0x7C, 0x1C,
		0xFA, 0x75, 0xED, 0xCD, 0xB3, 0xEB, 0x76, 0x4E, 0xB7, 0x11, 0xB4, 0x49, 0x83, 0x24, 0x72, 0x63,
		0x70, 0x27, 0xBF, 0x43, 0xC9, 0xF6, 0x1E, 0xF5, 0x8F, 0x4C, 0x16, 0xD1, 0x57, 0xF0, 0x26, 0xB9,
		0x6D, 0xA3, 0x6A, 0x33, 0xC1, 0x2D, 0x82, 0xDE, 0x35, 0xF4, 0x5F, 0x66, 0x01, 0xE5, 0xF2, 0xC0,
		0xDD, 0xC1, 0x19, 0xC1, 0xEB, 0x90, 0x33, 0xDA, 0xAB, 0x17, 0x6A, 0x6D, 0xEE, 0xA7, 0x81, 0xED,
		0x8C, 0x2F, 0x1B, 0x95, 0x31, 0xB7, 0x54, 0x20, 0x9F, 0x49, 0xFA, 0x74, 0xFC, 0x2B, 0x4A, 0x86,
		0x47, 0x05, 0x4E, 0x08, 0x39, 0x06, 0xAD, 0x4F, 0xE2, 0x26, 0xD4, 0xB4, 0xC8, 0x85, 0xDD, 0xAC,
		0x53, 0x6A, 0x70, 0xB3, 0x27, 0xDB, 0x1B, 0xFC, 0x49, 0x63, 0x65, 0x2B, 0xB1, 0xBF, 0xCD, 0x8F,
		0x73, 0xDA, 0x99, 0xAA, 0xD9, 0x85, 0x56, 0x39, 0xC8, 0x1B, 0x4F, 0x4E, 0xB8, 0x1D, 0xAA, 0x5D,
		0xE4, 0xED, 0x7B, 0x71, 0x24, 0xD7, 0x4E, 0xD2, 0x5C, 0x48, 0x72, 0xCE, 0xC0, 0xE5, 0xB8, 0x03,
		0xAD, 0x43, 0x64, 0xC1, 0x23, 0x18, 0x22, 0xBC, 0xC9, 0xC7, 0x3D, 0x29, 0xA8, 0xC3, 0x6C, 0xD6,
		0xF1, 0xE5, 0x7C, 0xB6, 0xDC, 0xA4, 0x67, 0x38, 0xAD, 0x3E, 0x44, 0x8A, 0x39, 0x53, 0x8A, 0x73,
		0xA1, 0x26, 0x9C, 0xF0, 0xDF, 0xCB, 0xA8, 0xBB, 0x13, 0x1D, 0xB9, 0xFB, 0x3A, 0x28, 0xE5, 0xA4,
		0xDC, 0x31, 0x9F, 0x61, 0x8C, 0xF2, 0x6B, 0xCB, 0x1B, 0x80, 0x2F, 0x15, 0x08, 0xCE, 0x7D, 0x3D,
		0x32, 0x0F, 0xD6, 0xB2, 0xDA, 0x32, 0x91, 0x12, 0xC2, 0x2F, 0x32, 0x45, 0x5D, 0x9E, 0x67, 0x39,
		0x29, 0xEE, 0x3B, 0xFE, 0x99, 0xAB, 0x0D, 0xCD, 0xAC, 0x73, 0x78, 0x64, 0x47, 0x6E, 0xFB, 0xCD,
		0xA5, 0xDB, 0x9C, 0xF7, 0x78, 0x9C, 0x0C, 0x31, 0x1F, 0xFF, 0x00, 0x0C, 0x7E, 0x34, 0xC7, 0x4E,
		0x4B, 0x29, 0x24, 0x59, 0x4D, 0x8A, 0x2A, 0x93, 0x87, 0x2A, 0xC5, 0x7E, 0xA3, 0xDB, 0xB8, 0xAB,
		0x83, 0xE8, 0x5A, 0x7D, 0xD7, 0x86, 0xCC, 0x4F, 0x24, 0x51, 0xC8, 0xAC, 0x61, 0x89, 0x95, 0xBE,
		0xF1, 0x2C, 0x1B, 0xFA, 0x83, 0xFF, 0x00, 0xF6, 0xA9, 0x3C, 0xA9, 0x76, 0x32, 0x81, 0x5E, 0xD4,
		0x6D, 0x3E, 0xDF, 0xA1, 0xE8, 0x91, 0x29, 0x64, 0x10, 0x46, 0xA6, 0x46, 0x0D, 0x92, 0xEA, 0xD1,
		0xB4, 0xC7, 0x8E, 0x9B, 0xB2, 0xAD, 0x8F, 0x82, 0x33, 0x55, 0xAD, 0x42, 0xE6, 0x68, 0x67, 0x8D,
		0x3C, 0xE4, 0x96, 0x18, 0xD5, 0x44, 0x3B, 0x79, 0x02, 0x32, 0x37, 0x0E, 0xA3, 0x3D, 0xFF, 0x00,
		0x43, 0x56, 0xA8, 0xFC, 0x3B, 0x73, 0xA7, 0x58, 0xBB, 0x23, 0x2C, 0xE1, 0x2E, 0x21, 0x91, 0x1D,
		0x4E, 0x7F, 0x86, 0x16, 0x44, 0x70, 0x47, 0xFD, 0xA7, 0x8C, 0x55, 0x56, 0xD7, 0x4E, 0x96, 0xF3,
		0x55, 0xBB, 0xB0, 0xFB, 0x44, 0x6E, 0xB6, 0xD6, 0xF2, 0x85, 0x77, 0xC0, 0xDC, 0xB1, 0xE4, 0x8C,
		0x67, 0xB9, 0xC7, 0x1D, 0xF1, 0x4F, 0x06, 0x9E, 0xEC, 0x59, 0x21, 0xCF, 0x87, 0x6D, 0x62, 0x97,
		0x53, 0xB6, 0xBE, 0xB6, 0x72, 0x40, 0x9E, 0x33, 0x24, 0x20, 0xE0, 0x7D, 0xE1, 0x9C, 0xFC, 0x55,
		0x92, 0x0B, 0x77, 0xBF, 0xD7, 0xCD, 0xB4, 0x46, 0x4C, 0x79, 0xCF, 0x19, 0xF3, 0x13, 0x94, 0xC1,
		0x23, 0x3C, 0x76, 0xF7, 0xAA, 0x2F, 0x85, 0x65, 0x10, 0x6B, 0x56, 0xAE, 0xDE, 0x66, 0xC1, 0x2A,
		0x33, 0x18, 0xFA, 0x81, 0x91, 0x5D, 0xBB, 0x42, 0xB9, 0x17, 0xFA, 0xE5, 0xC7, 0xDA, 0x6D, 0x9A,
		0x09, 0xE3, 0x91, 0xDE, 0x17, 0xDB, 0xE9, 0x9D, 0x0F, 0xA4, 0xF3, 0xEE, 0x08, 0xE9, 0x50, 0xCD,
		0x1D, 0xD1, 0xB1, 0x49, 0x89, 0x60, 0xF0, 0xD5, 0xF5, 0xDD, 0xF4, 0xE6, 0xCE, 0xE2, 0x14, 0x6B,
		0x56, 0x97, 0x6B, 0x32, 0x92, 0x19, 0xD8, 0xE5, 0x41, 0xFA, 0x10, 0x0F, 0xC5, 0x51, 0x4A, 0x9D,
		0x27, 0x4D, 0xFD, 0xC9, 0x71, 0x09, 0x17, 0x71, 0xDC, 0xB1, 0x99, 0xE2, 0x6D, 0xC2, 0x65, 0x03,
		0x18, 0xF8, 0xC1, 0x07, 0xEB, 0x5D, 0xFE, 0x18, 0x22, 0x81, 0x48, 0x8A, 0x34, 0x40, 0x4E, 0x48,
		0x55, 0xC6, 0x4D, 0x71, 0xCF, 0x1B, 0x78, 0x5F, 0x53, 0xB3, 0xF1, 0x14, 0x9A, 0xAA, 0x46, 0x1E,
		0xCE, 0x79, 0x0A, 0xAC, 0xAA, 0xDF, 0xE1, 0xEF, 0x38, 0xF5, 0x67, 0xE4, 0xD3, 0xE2, 0x5E, 0x18,
		0x4A, 0x35, 0xD1, 0xBF, 0x4D, 0xF0, 0xFD, 0x9F, 0xDB, 0x2C, 0xB5, 0x7B, 0x35, 0x97, 0x12, 0x48,
		0x02, 0xAE, 0xCC, 0x98, 0x65, 0x5E, 0x72, 0xC3, 0xFC, 0x99, 0x18, 0xAB, 0xCD, 0xB7, 0x85, 0x2C,
		0x26, 0xD3, 0xD6, 0x29, 0x61, 0x8D, 0xE3, 0xB8, 0x1B, 0xAE, 0x31, 0xD6, 0x43, 0x9C, 0xA9, 0xCF,
		0xC1, 0x3F, 0xAD, 0x73, 0xFF, 0x00, 0x06, 0xFD, 0x8E, 0x3B, 0x98, 0x4D, 0xF9, 0x99, 0x63, 0xF3,
		0xC7, 0x24, 0x13, 0x1B, 0x12, 0x4A, 0x82, 0x79, 0xE0, 0x67, 0x03, 0x35, 0xD9, 0x55, 0x02, 0x28,
		0x51, 0xC0, 0x03, 0x02, 0x93, 0x77, 0x4D, 0x9B, 0x08, 0xA1, 0x2D, 0x87, 0x85, 0x34, 0xAD, 0x3A,
		0xC9, 0xED, 0x60, 0x83, 0x11, 0xB3, 0x97, 0x07, 0x3E, 0xA1, 0x93, 0x9C, 0x67, 0xDA, 0xB7, 0xCC,
		0x8B, 0xA1, 0x68, 0xB2, 0x0B, 0x34, 0x05, 0x61, 0x56, 0x31, 0xA3, 0x1E, 0x9D, 0x4E, 0x3F, 0x3A,
		0x64, 0xEE, 0xB1, 0x8C, 0xB1, 0xC7, 0xD6, 0xA0, 0x6A, 0x92, 0x90, 0x81, 0x5E, 0x37, 0x7B, 0x59,
		0x23, 0x64, 0x97, 0x62, 0xE7, 0x00, 0xE0, 0x67, 0xF5, 0x35, 0x8C, 0xA5, 0x25, 0xD1, 0x43, 0xF1,
		0x2A, 0xDC, 0x5A, 0xE8, 0x3A, 0x44, 0xCA, 0x59, 0xAD, 0x64, 0x12, 0x17, 0x38, 0x00, 0xC6, 0xCE,
		0x0B, 0x00, 0x08, 0xFF, 0x00, 0xB8, 0x8F, 0x9C, 0x0A, 0xCE, 0xDB, 0x59, 0x69, 0x74, 0x0D, 0x36,
		0xDA, 0xE1, 0x20, 0x9B, 0x7C, 0x03, 0xCD, 0x65, 0x18, 0x92, 0x33, 0x92, 0x15, 0x86, 0x7E, 0x83,
		0xF0, 0xA8, 0xDE, 0x24, 0xBA, 0xBF, 0xD2, 0xEE, 0x46, 0x8A, 0xBE, 0x4D, 0xCE, 0x97, 0x2A, 0xC7,
		0xB1, 0xDC, 0x65, 0x94, 0x83, 0xC0, 0xE0, 0xFC, 0x0A, 0x4D, 0x65, 0x10, 0xB8, 0x48, 0x5A, 0xEC,
		0x3C, 0x0B, 0x34, 0x0B, 0xE4, 0xB6, 0xFD, 0x81, 0x82, 0x92, 0x0E, 0x0E, 0x0F, 0xFC, 0x15, 0x78,
		0xE3, 0x4E, 0x0A, 0xC8, 0x37, 0x4C, 0xB7, 0x35, 0xBD, 0xAD, 0xA6, 0xBD, 0xA5, 0xFA, 0x12, 0x55,
		0x5B, 0x70, 0x15, 0x83, 0x60, 0x16, 0xCE, 0x72, 0x7F, 0x1A, 0xBB, 0xDD, 0x4C, 0x2D, 0xAC, 0xA5,
		0x97, 0x81, 0xB2, 0x32, 0x7F, 0x4A, 0xE7, 0x9E, 0x11, 0xD2, 0x9A, 0x7B, 0xA5, 0x56, 0xBC, 0x89,
		0xD2, 0x09, 0x37, 0x6D, 0x0D, 0x96, 0x60, 0x46, 0x72, 0x3D, 0xC7, 0x4A, 0x79, 0xFB, 0x42, 0xBE,
		0xB8, 0xB0, 0xD0, 0x10, 0xDA, 0xCC, 0xD1, 0x34, 0x92, 0x14, 0x25, 0x7B, 0x8D, 0xA7, 0x22, 0xB3,
		0x1E, 0x2E, 0x79, 0x16, 0x34, 0xFB, 0x1A, 0x53, 0x58, 0xF1, 0xB9, 0xBF, 0x07, 0x3A, 0x9A, 0xF9,
		0xEE, 0xEF, 0x83, 0x39, 0xDE, 0x15, 0x42, 0x2E, 0x7F, 0xCA, 0x3A, 0x55, 0xFB, 0xC3, 0x90, 0x1B,
		0x7B, 0x3B, 0xB5, 0x63, 0x96, 0x96, 0x16, 0xDD, 0xF9, 0x71, 0x5C, 0xF7, 0xC3, 0x76, 0xFF, 0x00,
		0x6C, 0xD5, 0xE1, 0x4C, 0x67, 0x73, 0x8E, 0x3D, 0xFB, 0xD7, 0x4C, 0xD1, 0xB1, 0x25, 0xA5, 0xF5,
		0xE0, 0x5F, 0x2E, 0x20, 0x8E, 0x81, 0x48, 0xC1, 0xEE, 0x6B, 0xD7, 0xF5, 0x95, 0x08, 0xFB, 0x6B,
		0xE8, 0xF2, 0xFD, 0x15, 0xE5, 0x7E, 0xEB, 0xF2, 0x7C, 0x77, 0xA8, 0x7F, 0xF9, 0x8D, 0xCF, 0xFF,
		0x00, 0xB8, 0x7F, 0xAD, 0x44, 0xA9, 0x77, 0xE7, 0x3A, 0x85, 0xC1, 0xF7, 0x90, 0xFF, 0x00, 0x5A,
		0x89, 0x5E, 0x3E, 0x5F, 0x9C, 0xBF, 0xB3, 0xD8, 0x87, 0xC5, 0x05, 0x14, 0x51, 0x48, 0x30, 0x51,
		0x45, 0x14, 0x00, 0x51, 0x45, 0x14, 0x00, 0x51, 0x45, 0x14, 0x01, 0xD3, 0xA0, 0xB8, 0x96, 0xDE,
		0x75, 0x74, 0x91, 0x71, 0x90, 0x48, 0x39, 0xC3, 0x01, 0xD3, 0x38, 0xED, 0x53, 0xFC, 0x4D, 0xAB,
		0xDE, 0x78, 0x92, 0xEA, 0x2D, 0x46, 0xEB, 0xCA, 0xF3, 0x04, 0x0B, 0x19, 0x11, 0xAE, 0xD1, 0xE9,
		0xCF, 0x34, 0xB0, 0x9E, 0x03, 0x00, 0x01, 0xF7, 0x15, 0xAD, 0x09, 0xD9, 0x26, 0x46, 0x41, 0x18,
		0x27, 0x19, 0xC5, 0x74, 0x71, 0x23, 0x66, 0xF5, 0xD7, 0x75, 0x25, 0xD1, 0x24, 0xD2, 0x12, 0xE9,
		0x96, 0xC1, 0xD8, 0x33, 0x42, 0x00, 0xC1, 0x20, 0xE7, 0x3F, 0x1C, 0xD2, 0xE8, 0xCE, 0x58, 0x0F,
		0x9E, 0xB4, 0x00, 0x4F, 0x6A, 0xF0, 0x70, 0x73, 0xDE, 0x9A, 0x82, 0xCC, 0xA3, 0x82, 0x49, 0xA6,
		0x58, 0xE2, 0x56, 0x77, 0x76, 0x0A, 0xAA, 0xA3, 0x25, 0x89, 0xEC, 0x05, 0x5D, 0xFC, 0x23, 0x6B,
		0x77, 0xAE, 0xEA, 0xD7, 0xFA, 0x44, 0xF7, 0x09, 0x34, 0xF7, 0x56, 0x26, 0x12, 0xF3, 0x82, 0xFB,
		0x15, 0x31, 0xC0, 0x39, 0xE0, 0xA9, 0x0B, 0xF9, 0x11, 0x55, 0xDD, 0x1A, 0xF2, 0x3D, 0x3B, 0x53,
		0xB4, 0xBB, 0x78, 0x56, 0x41, 0x0C, 0xAB, 0x26, 0x09, 0x2B, 0xC8, 0x39, 0xEB, 0x57, 0x3D, 0x06,
		0xF6, 0xDF, 0x54, 0xFD, 0xA4, 0x9D, 0x42, 0x38, 0x96, 0xD5, 0x6E, 0x5E, 0x4F, 0x2D, 0x63, 0xFE,
		0x47, 0x2A, 0x42, 0x9F, 0xCF, 0x93, 0xEE, 0x6A, 0x72, 0x19, 0x1C, 0xD6, 0x58, 0x5E, 0x37, 0xDA,
		0xFD, 0x47, 0xEB, 0x4C, 0xF4, 0x3D, 0x11, 0xF5, 0x83, 0x3C, 0x56, 0xF7, 0x0B, 0x1D, 0xC4, 0x31,
		0x3C, 0xE0, 0x37, 0x0A, 0x55, 0x14, 0x96, 0xF5, 0x67, 0x83, 0xD3, 0x1C, 0x77, 0xED, 0x8A, 0xD9,
		0xA8, 0x4A, 0xB2, 0xEA, 0x57, 0x26, 0xEA, 0x05, 0x47, 0x69, 0x0B, 0x37, 0x96, 0xBB, 0x46, 0x49,
		0xE7, 0x03, 0xB0, 0xF8, 0xAD, 0x51, 0x2D, 0xAA, 0x12, 0x21, 0x9D, 0xE3, 0x72, 0x08, 0x27, 0x07,
		0xA1, 0x18, 0x23, 0xF1, 0x15, 0xB7, 0xA0, 0xA2, 0x3D, 0xDC, 0x24, 0x38, 0x9D, 0x01, 0xD8, 0xC0,
		0x29, 0xCF, 0x63, 0x8E, 0x99, 0xEF, 0xD2, 0xA0, 0x84, 0x38, 0x3C, 0x7E, 0x75, 0x64, 0x9B, 0x48,
		0x96, 0x3D, 0x2E, 0x09, 0x83, 0xA3, 0x47, 0x2B, 0x30, 0x01, 0x4E, 0x58, 0x15, 0xC7, 0x51, 0xF2,
		0x18, 0x62, 0xBD, 0xB6, 0xB5, 0x53, 0x1E, 0x66, 0x31, 0x97, 0xE0, 0x2E, 0x7F, 0x9B, 0xFE, 0x66,
		0x85, 0x24, 0x82, 0xAC, 0x8D, 0xA3, 0x69, 0x73, 0xDC, 0xE9, 0x77, 0x93, 0x63, 0x6C, 0x31, 0x46,
		0xD2, 0xBB, 0x6D, 0x27, 0x3B, 0x71, 0xE9, 0xE0, 0x70, 0x7D, 0x5F, 0x4A, 0x80, 0x8D, 0x32, 0xC9,
		0xB8, 0x10, 0x58, 0x60, 0x9E, 0x2A, 0xF1, 0x6B, 0xA7, 0xC4, 0xDA, 0x6C, 0x89, 0x69, 0x75, 0x34,
		0x57, 0x7B, 0x80, 0x5D, 0xB2, 0x61, 0x36, 0x91, 0xEA, 0x52, 0x3B, 0xE4, 0x85, 0xFC, 0xA9, 0x23,
		0xE9, 0x37, 0x09, 0xA9, 0x25, 0xB4, 0x88, 0xC9, 0xBE, 0x40, 0x14, 0x04, 0xE8, 0x0F, 0xB7, 0x3C,
		0xD6, 0x29, 0xA7, 0x60, 0xE2, 0xD0, 0xDA, 0xD2, 0x4B, 0xA9, 0x73, 0x69, 0x24, 0x01, 0x21, 0x50,
		0xB2, 0x45, 0xB4, 0x9C, 0x64, 0x67, 0x79, 0xF9, 0xCF, 0x27, 0x3F, 0x4E, 0xD4, 0xCE, 0x29, 0x6E,
		0xA0, 0x85, 0x1E, 0x48, 0xBC, 0xC8, 0x16, 0x70, 0xEC, 0x77, 0x75, 0x8C, 0xF0, 0x46, 0x3F, 0x0A,
		0x61, 0xA4, 0xB5, 0xBB, 0xDB, 0x5B, 0xC0, 0xF7, 0x32, 0xA4, 0x6B, 0x03, 0xC6, 0x10, 0xC4, 0x4B,
		0x6E, 0xC6, 0x71, 0xF0, 0x33, 0x9F, 0x7A, 0x8B, 0x2E, 0x87, 0xA9, 0xE8, 0xCC, 0x97, 0xB6, 0x57,
		0x49, 0x25, 0x9C, 0xB8, 0x0B, 0x6B, 0xBB, 0x73, 0xEC, 0x03, 0x93, 0xCF, 0x61, 0x83, 0x5C, 0xED,
		0xA6, 0xCA, 0x71, 0x68, 0xCE, 0xC7, 0x56, 0x96, 0x0B, 0xD8, 0x9E, 0x32, 0x70, 0xD2, 0xED, 0x2D,
		0xD0, 0x00, 0x71, 0x9E, 0xFD, 0xB3, 0x9F, 0x6E, 0x69, 0x8E, 0x99, 0xE1, 0x68, 0x6F, 0xFC, 0x40,
		0x9A, 0xD6, 0x9A, 0x50, 0x3C, 0x12, 0xFF, 0x00, 0x1A, 0xDA, 0x55, 0xC0, 0x20, 0xE5, 0x5B, 0x1E,
		0xDC, 0x12, 0x71, 0x53, 0x6C, 0xB4, 0x45, 0xD4, 0x2D, 0xCC, 0x96, 0xD0, 0x04, 0x91, 0x49, 0x57,
		0xB7, 0x3C, 0x03, 0x9C, 0x74, 0x27, 0xF0, 0xFC, 0x05, 0x5F, 0xD2, 0xC2, 0x25, 0x87, 0x62, 0xA0,
		0x89, 0x8F, 0x2C, 0x63, 0xE3, 0x2C, 0x7A, 0xFE, 0xB4, 0x91, 0xB5, 0xD0, 0x35, 0xFB, 0x3E, 0x72,
		0xD3, 0x6D, 0x9F, 0x46, 0xD6, 0x59, 0x6F, 0xAC, 0x9E, 0x41, 0x12, 0xB0, 0x64, 0x03, 0x24, 0x70,
		0x40, 0xC8, 0xAE, 0xA7, 0xA3, 0xDA, 0xDD, 0x5C, 0xDD, 0x69, 0xDA, 0x86, 0x97, 0x71, 0x2B, 0xDB,
		0x88, 0x91, 0x24, 0x81, 0xCE, 0x08, 0x2A, 0x4E, 0x49, 0x07, 0xDC, 0x9A, 0xAE, 0xFE, 0xD0, 0xEC,
		0xFF, 0x00, 0x75, 0xEB, 0x76, 0xBA, 0xBC, 0x00, 0x84, 0xBC, 0x8B, 0x07, 0x1C, 0xE1, 0xD4, 0xFA,
		0xB9, 0xF7, 0xC6, 0x3F, 0x5A, 0x7F, 0xE1, 0x6F, 0x14, 0x88, 0xAD, 0x6C, 0xAD, 0x6E, 0x63, 0x32,
		0x47, 0x20, 0x56, 0xF3, 0x94, 0x60, 0x86, 0x62, 0xDD, 0x00, 0xFE, 0x51, 0xB7, 0x07, 0xEB, 0x55,
		0xC9, 0x72, 0x4A, 0x44, 0xE2, 0x92, 0x74, 0x74, 0x8A, 0x45, 0xE2, 0xB0, 0x92, 0xE8, 0x93, 0x5B,
		0x1B, 0x7F, 0xB4, 0x4B, 0x22, 0x39, 0x8D, 0x0F, 0x4C, 0x85, 0x27, 0x27, 0xE0, 0x53, 0xC6, 0x6D,
		0xAA, 0x4F, 0x1D, 0x3B, 0x9E, 0x2B, 0x9B, 0xDE, 0x5E, 0xF9, 0x1E, 0x35, 0xBB, 0xD4, 0x59, 0xCA,
		0xDB, 0xBD, 0xA9, 0x8E, 0x2C, 0x9D, 0xCA, 0x49, 0xC0, 0x27, 0xE3, 0xB7, 0x15, 0x8E, 0x8A, 0x55,
		0x89, 0x3C, 0x25, 0x03, 0xDD, 0xBA, 0xE9, 0xDB, 0x50, 0x79, 0x87, 0x2A, 0xCE, 0x01, 0xC3, 0x26,
		0x18, 0x1F, 0xEB, 0xF8, 0xD7, 0x4B, 0xF1, 0x54, 0x8D, 0x1F, 0x86, 0xEF, 0x5D, 0x24, 0x64, 0x65,
		0x4D, 0xC0, 0xA7, 0xDE, 0x3C, 0x8E, 0x05, 0x73, 0x5B, 0x01, 0x3D, 0xAA, 0x89, 0x83, 0x2E, 0xF7,
		0x59, 0xEE, 0x44, 0x71, 0xE5, 0x5A, 0x3D, 0x8B, 0xE9, 0x27, 0xE0, 0xFB, 0x56, 0xC7, 0xF1, 0x6F,
		0x9B, 0x06, 0xA3, 0x6D, 0x7D, 0x30, 0x91, 0x2E, 0xD5, 0x25, 0x57, 0x23, 0x6F, 0x23, 0xEF, 0x01,
		0xEC, 0x7A, 0x63, 0xE9, 0x4C, 0xE2, 0xDB, 0xBA, 0x11, 0x69, 0x11, 0xB4, 0x7F, 0x14, 0x6A, 0xA2,
		0xEA, 0x44, 0x9E, 0x49, 0x2E, 0x55, 0xA3, 0x62, 0x8A, 0xC7, 0x25, 0x59, 0x41, 0x39, 0x07, 0xB1,
		0x18, 0xA7, 0xDE, 0x1E, 0xF1, 0xB5, 0xF4, 0x96, 0xF7, 0xB6, 0xDA, 0xC5, 0xA4, 0xD2, 0x18, 0xA3,
		0x18, 0x64, 0x23, 0x73, 0xEE, 0x3B, 0x40, 0xC7, 0xBF, 0x39, 0xFC, 0x09, 0xA4, 0x3E, 0x1F, 0xB1,
		0xB4, 0x9F, 0x54, 0x8E, 0x54, 0x2A, 0x59, 0xB2, 0x84, 0xA4, 0xBD, 0x72, 0x08, 0x39, 0xFA, 0xE4,
		0xD5, 0xCF, 0x53, 0xD0, 0x60, 0xD2, 0xB4, 0xA7, 0x98, 0xED, 0x92, 0x42, 0xE8, 0xA1, 0xDF, 0xB0,
		0xE7, 0xA9, 0xFC, 0xCD, 0x6C, 0xB8, 0x27, 0x49, 0x18, 0xAF, 0xB3, 0x9C, 0xDE, 0xC3, 0x0D, 0xAE,
		0xAA, 0xA5, 0x0C, 0x92, 0x69, 0xF3, 0x02, 0x51, 0x83, 0x60, 0x80, 0x09, 0x18, 0xF8, 0x20, 0x8C,
		0x73, 0x56, 0x88, 0x6C, 0x21, 0xD5, 0xB4, 0x5B, 0x29, 0xA5, 0x9F, 0xF8, 0xFE, 0x7C, 0xB2, 0x44,
		0x07, 0x23, 0x6B, 0x36, 0x4A, 0x7F, 0x43, 0xF8, 0xD5, 0x5A, 0x0B, 0x71, 0x3D, 0xDC, 0x92, 0x99,
		0x1A, 0x18, 0xB6, 0x7A, 0x64, 0x61, 0x9D, 0xDC, 0xE0, 0x9F, 0x8E, 0xA2, 0xAE, 0xCF, 0x3C, 0x76,
		0x56, 0x36, 0x77, 0x56, 0xCF, 0x14, 0x71, 0xC1, 0x23, 0xA0, 0x68, 0xD7, 0x2A, 0x18, 0x85, 0x21,
		0x48, 0xF7, 0xC8, 0x3C, 0xFC, 0x1A, 0xE9, 0xC8, 0xDA, 0xA4, 0xBB, 0x25, 0x04, 0xB6, 0x33, 0xD1,
		0x34, 0xD7, 0xF0, 0xE7, 0x87, 0x66, 0xBA, 0xB8, 0x08, 0xB7, 0x24, 0x96, 0x41, 0x22, 0xE0, 0xA7,
		0x18, 0xDB, 0xF8, 0xD5, 0x67, 0xC7, 0x5A, 0xD7, 0xEF, 0x4B, 0xBB, 0x3B, 0x48, 0xD0, 0x01, 0x08,
		0x0E, 0x7D, 0x5D, 0x4B, 0x2A, 0x9F, 0xD3, 0x24, 0x53, 0xAB, 0x7F, 0x12, 0x43, 0xAE, 0xEB, 0xB0,
		0xD8, 0x4C, 0x12, 0x7B, 0x06, 0x25, 0x55, 0x80, 0xDA, 0x0C, 0x98, 0xE3, 0x23, 0xDB, 0xAD, 0x56,
		0x3C, 0x50, 0x9E, 0x6F, 0x8B, 0x65, 0x78, 0xC0, 0xDA, 0xEC, 0x0A, 0xE3, 0xDB, 0x18, 0x1F, 0xD2,
		0xAB, 0xE8, 0xA1, 0xFC, 0xCE, 0x52, 0x5B, 0xAB, 0x23, 0xEA, 0xDF, 0xF1, 0x71, 0x8F, 0x4D, 0xD1,
		0x37, 0xC2, 0x96, 0x52, 0xAE, 0xB3, 0x6C, 0xC9, 0xFF, 0x00, 0xDC, 0xC3, 0x71, 0x9C, 0x0C, 0x73,
		0xFD, 0x6A, 0xFB, 0xAA, 0x24, 0x7A, 0x57, 0x87, 0xAF, 0xBC, 0xA0, 0x4E, 0x62, 0x90, 0xF2, 0x7B,
		0xED, 0x34, 0x8B, 0xC1, 0xDA, 0x32, 0x49, 0xBB, 0x50, 0x2E, 0x55, 0xD1, 0xC0, 0x51, 0x8F, 0x8E,
		0x7F, 0x3E, 0x29, 0xE7, 0x8A, 0xE5, 0x58, 0xBC, 0x2D, 0xA9, 0xCA, 0x79, 0xD9, 0x6D, 0x21, 0xFF,
		0x00, 0xFC, 0x91, 0xFD, 0xE9, 0x33, 0x64, 0xE7, 0x9D, 0x2F, 0xB4, 0x53, 0x14, 0x38, 0x62, 0x67,
		0xC5, 0x17, 0x47, 0x37, 0x52, 0x9F, 0xF5, 0x1A, 0xD1, 0x5B, 0x66, 0x39, 0x99, 0xCF, 0xFA, 0x8D,
		0x6A, 0xAE, 0x5C, 0x9B, 0x93, 0x67, 0x4C, 0x7A, 0x41, 0x45, 0x14, 0x52, 0x0C, 0x14, 0x51, 0x45,
		0x00, 0x14, 0x51, 0x45, 0x00, 0x14, 0x51, 0x45, 0x00, 0x74, 0xF9, 0x22, 0x1E, 0x42, 0xB0, 0xC0,
		0xCF, 0x3F, 0x5F, 0x9A, 0x8D, 0x8C, 0x77, 0xEB, 0x53, 0xE6, 0x46, 0x49, 0x1A, 0x16, 0x75, 0x3B,
		0x09, 0x1C, 0x11, 0xEF, 0x51, 0xCA, 0x0F, 0x71, 0xF9, 0xD7, 0x65, 0x1C, 0xD6, 0x1A, 0x7D, 0xB4,
		0xB7, 0x37, 0x5E, 0x5C, 0x08, 0xCE, 0x40, 0x2C, 0x76, 0x8C, 0xE1, 0x40, 0xC9, 0x3F, 0x4C, 0x54,
		0x23, 0x18, 0x07, 0x15, 0x3E, 0x20, 0x62, 0x3B, 0x92, 0x52, 0x8D, 0x82, 0x0E, 0xD3, 0x83, 0x82,
		0x30, 0x6B, 0xDF, 0xB3, 0x2B, 0x74, 0x71, 0x4B, 0xD0, 0xC4, 0xFB, 0xDB, 0x5B, 0x44, 0xD3, 0x6C,
		0x45, 0x9C, 0xAF, 0x24, 0xAD, 0x01, 0x92, 0xE4, 0x1E, 0x8A, 0xDB, 0x8E, 0x00, 0xFC, 0x08, 0xA9,
		0xFE, 0x08, 0xB9, 0xD2, 0xF4, 0xDD, 0x75, 0x6E, 0xB5, 0x83, 0x22, 0x24, 0x4A, 0x5E, 0x22, 0x23,
		0x2C, 0x3C, 0xCE, 0xC4, 0x81, 0xED, 0x52, 0x34, 0xEB, 0x25, 0x83, 0x46, 0x96, 0x51, 0x02, 0xB9,
		0x31, 0xED, 0x32, 0x1C, 0x1D, 0xA4, 0xB6, 0xD1, 0x8E, 0x3A, 0xE4, 0xE0, 0xE3, 0xF4, 0xA4, 0x43,
		0x4D, 0x93, 0xFF, 0x00, 0xA7, 0x27, 0x4F, 0x9A, 0x97, 0x24, 0xEE, 0xC7, 0x24, 0xDD, 0x6A, 0x1F,
		0x6D, 0xD4, 0xAE, 0x2E, 0x9E, 0xDD, 0x15, 0x66, 0x91, 0x9F, 0x62, 0xF4, 0x19, 0xEC, 0x28, 0x86,
		0xCE, 0x19, 0xBD, 0x4A, 0xC5, 0x48, 0xEC, 0x57, 0x39, 0xAD, 0x66, 0x26, 0x49, 0x82, 0x89, 0x1B,
		0x69, 0xE8, 0x5C, 0x63, 0x3E, 0xF5, 0x2A, 0xCA, 0x18, 0x66, 0x93, 0x6C, 0xB7, 0x5E, 0x4F, 0xB1,
		0x23, 0x8A, 0x59, 0x52, 0x43, 0xAD, 0x8C, 0x1E, 0xD6, 0x46, 0x85, 0x1D, 0x21, 0x3B, 0x92, 0x3C,
		0x1D, 0xB8, 0xED, 0xFF, 0x00, 0x9C, 0xD6, 0xE1, 0x75, 0xA5, 0xDD, 0x3A, 0xF9, 0xBE, 0x5A, 0xBC,
		0x88, 0xC2, 0x46, 0x1D, 0x01, 0x2B, 0xB4, 0xB1, 0x18, 0xEA, 0x3A, 0xFD, 0x6A, 0xC1, 0xA0, 0x5B,
		0x3F, 0xDA, 0x84, 0x06, 0x48, 0x6E, 0xA1, 0x72, 0x55, 0x4C, 0x6E, 0x3A, 0x9E, 0x39, 0xAD, 0xFA,
		0x88, 0xB2, 0x9F, 0x50, 0xFB, 0x31, 0xB6, 0x85, 0x27, 0x0E, 0x61, 0x67, 0xCA, 0xF5, 0xE9, 0xCF,
		0x15, 0xCF, 0xCF, 0x65, 0x9C, 0x51, 0xCF, 0x4E, 0x97, 0x73, 0x04, 0xA6, 0x7B, 0x09, 0xBC, 0xFD,
		0xBC, 0xB0, 0x56, 0xE4, 0x0F, 0x7A, 0x7D, 0x65, 0xE2, 0x03, 0x6F, 0x2C, 0x6F, 0xA8, 0x69, 0xCC,
		0xD1, 0xC6, 0x41, 0x0E, 0xAB, 0x92, 0x3F, 0x1C, 0xE6, 0xBC, 0xBC, 0xD2, 0xA1, 0xD2, 0xE6, 0x8F,
		0xED, 0xD6, 0xC5, 0xC6, 0xED, 0x86, 0x54, 0x7D, 0xA1, 0x9B, 0xBE, 0x3D, 0xC5, 0x58, 0x6C, 0x21,
		0x86, 0xF6, 0x15, 0xB7, 0xB6, 0x42, 0x63, 0x91, 0x31, 0xEA, 0x70, 0x58, 0x37, 0x63, 0xCD, 0x3C,
		0xE6, 0xB4, 0xDE, 0xC4, 0x84, 0x5D, 0xE8, 0xD9, 0x34, 0x1A, 0x56, 0xBF, 0x72, 0xD7, 0x5A, 0x25,
		0xFC, 0x51, 0x5E, 0x37, 0x3E, 0x43, 0xE4, 0x72, 0x78, 0x38, 0xE3, 0x1C, 0xFF, 0x00, 0x7A, 0xB2,
		0x69, 0xBA, 0x24, 0x50, 0x6A, 0x02, 0x0B, 0xC8, 0x94, 0xC9, 0x2A, 0x97, 0x1C, 0xE4, 0x2F, 0xC0,
		0xF7, 0xEF, 0x54, 0xFB, 0x5F, 0x08, 0xEB, 0x91, 0xDD, 0x45, 0xFB, 0xC7, 0x72, 0xC4, 0xA7, 0xD1,
		0x33, 0x7A, 0x95, 0x31, 0xEF, 0x83, 0xC7, 0xD4, 0xD7, 0x44, 0x8A, 0x49, 0xED, 0xA5, 0xB4, 0xB5,
		0xBB, 0x09, 0x3E, 0x08, 0xDB, 0x72, 0x46, 0xD1, 0xD3, 0xB7, 0xCF, 0x6C, 0x77, 0xA4, 0x69, 0x75,
		0x63, 0x72, 0x1A, 0xDB, 0x5A, 0x43, 0x11, 0x0E, 0xB0, 0x2A, 0x32, 0xAE, 0xC5, 0x23, 0xB2, 0xD4,
		0x9E, 0xC6, 0x8A, 0x2A, 0x89, 0x51, 0x33, 0x99, 0xF8, 0xB2, 0x1B, 0x9B, 0xBB, 0x69, 0xB4, 0x7B,
		0x80, 0xA4, 0xC5, 0x27, 0x9F, 0x13, 0x05, 0xF4, 0x80, 0x7B, 0x03, 0xF1, 0xCF, 0xE7, 0x53, 0x3C,
		0x15, 0xE0, 0xCB, 0xBD, 0x0B, 0x51, 0x69, 0xEF, 0x6E, 0x20, 0x93, 0x64, 0x25, 0x16, 0x35, 0x3B,
		0xB1, 0x93, 0x90, 0x7E, 0x3B, 0xFE, 0x66, 0x99, 0x78, 0x8A, 0x71, 0x6D, 0xAA, 0xC3, 0x22, 0xA3,
		0x79, 0x80, 0x8E, 0x09, 0xCA, 0xB2, 0xFD, 0x2A, 0xC1, 0x6F, 0x64, 0x61, 0xD4, 0x2E, 0x2E, 0x8C,
		0xEE, 0xE2, 0x70, 0x3D, 0x04, 0x70, 0x98, 0xF6, 0xA5, 0x8C, 0x9D, 0x71, 0x5D, 0x1B, 0x28, 0xAE,
		0xC9, 0xAC, 0x32, 0xA4, 0x0E, 0x38, 0xAE, 0x51, 0xE3, 0x4B, 0xAD, 0x35, 0x2F, 0xAF, 0x6C, 0xEF,
		0x02, 0xAC, 0xB1, 0x08, 0x9A, 0x18, 0xD1, 0xBE, 0xA4, 0x9C, 0x76, 0xCF, 0xCF, 0xC5, 0x75, 0x8A,
		0xE0, 0xDE, 0x29, 0xD1, 0x5A, 0xD7, 0xC5, 0x13, 0x4D, 0x71, 0x7A, 0x6E, 0xF3, 0x21, 0x2D, 0xB9,
		0xC2, 0xB0, 0xE4, 0xE0, 0x1F, 0x6E, 0x3B, 0xD5, 0x60, 0x93, 0x96, 0xD8, 0x92, 0x6D, 0x2D, 0x1E,
		0x5E, 0xDC, 0xC9, 0x22, 0xCD, 0x79, 0x67, 0xB6, 0x5B, 0x69, 0xAD, 0x58, 0x92, 0x54, 0xAF, 0x90,
		0x15, 0xC2, 0x80, 0x3E, 0x41, 0x60, 0x3E, 0x73, 0x55, 0x78, 0xEF, 0x66, 0x50, 0x51, 0x5B, 0x72,
		0x8E, 0x80, 0xF3, 0x57, 0x86, 0xB2, 0x48, 0x7F, 0x67, 0x04, 0x23, 0x05, 0x97, 0xD5, 0x72, 0x32,
		0x32, 0xCD, 0x1B, 0x30, 0x52, 0x0F, 0xB0, 0xE8, 0xDF, 0x95, 0x51, 0x2C, 0xE1, 0x76, 0xB8, 0x54,
		0x40, 0x0B, 0x31, 0xDA, 0x07, 0xBD, 0x76, 0x62, 0xE3, 0x4C, 0xE6, 0xC8, 0xDD, 0x92, 0xF4, 0xE8,
		0x84, 0xF3, 0x30, 0x8A, 0x5F, 0x22, 0x50, 0x37, 0x2E, 0x38, 0xC9, 0xCD, 0x5F, 0xED, 0xF5, 0x1B,
		0xE3, 0xAA, 0x6A, 0x90, 0xDD, 0x6A, 0x4D, 0x3D, 0xA4, 0x16, 0xE5, 0x62, 0x25, 0xB8, 0x39, 0xD9,
		0xCF, 0x3D, 0xF1, 0xFA, 0xD5, 0x57, 0xC3, 0xF6, 0xE9, 0x71, 0x27, 0xD9, 0xD5, 0x16, 0x49, 0x18,
		0xB6, 0xC1, 0x90, 0x0B, 0x12, 0x00, 0x0B, 0xF2, 0x3F, 0xDA, 0xB1, 0xBC, 0xB7, 0x68, 0x2E, 0xA1,
		0x8A, 0xE2, 0x37, 0x88, 0x94, 0x41, 0x22, 0x31, 0xF5, 0x1C, 0x1C, 0x13, 0xF8, 0x8A, 0xD7, 0x15,
		0x29, 0x50, 0x29, 0x38, 0xAB, 0x27, 0x69, 0x77, 0x11, 0x59, 0x5F, 0xC9, 0x13, 0xC6, 0x24, 0x85,
		0xB2, 0x85, 0xB3, 0x80, 0xA3, 0x70, 0x21, 0xBF, 0x4A, 0xB3, 0xF8, 0x97, 0x53, 0x8D, 0x3C, 0x27,
		0x67, 0x0C, 0x36, 0xF1, 0xC1, 0xE6, 0x3B, 0x49, 0xB1, 0x4F, 0xF9, 0x58, 0x8E, 0x7D, 0xCF, 0x1C,
		0xFD, 0x6B, 0x9E, 0x18, 0x84, 0xD7, 0x6C, 0x91, 0xC8, 0xA3, 0x73, 0xB1, 0x19, 0x38, 0xE3, 0x3C,
		0x53, 0xAB, 0xEB, 0x57, 0xB8, 0xD2, 0x2D, 0xEF, 0x8C, 0x98, 0x89, 0xD9, 0x95, 0x41, 0x3F, 0xCF,
		0xD5, 0xFF, 0x00, 0xB5, 0x5B, 0xDA, 0x8F, 0x38, 0xC9, 0xB2, 0x7E, 0xE3, 0xE2, 0xD2, 0x1B, 0xF8,
		0x46, 0xCC, 0x6A, 0x1A, 0xB1, 0x61, 0x2F, 0x94, 0xF1, 0xA9, 0x94, 0x28, 0x1C, 0x93, 0xEC, 0xBF,
		0xF3, 0xBD, 0x4E, 0xB6, 0xD3, 0x67, 0xBA, 0xD6, 0x64, 0x90, 0xA9, 0x22, 0x37, 0xD8, 0xB9, 0x19,
		0xF5, 0x1C, 0xEC, 0x07, 0xFA, 0xFE, 0x15, 0x17, 0xC3, 0x9A, 0xB4, 0xFA, 0x7E, 0x9D, 0x2D, 0xBC,
		0x0C, 0xAA, 0xD2, 0x8C, 0x19, 0x08, 0x04, 0xAF, 0xD2, 0xBA, 0x2E, 0x8B, 0x66, 0xA2, 0xD3, 0xCF,
		0x7C, 0x33, 0x3C, 0xBE, 0x7E, 0x41, 0xE8, 0x76, 0xE2, 0xB9, 0xF2, 0x65, 0x96, 0x39, 0x37, 0xFB,
		0x2B, 0x08, 0x46, 0x51, 0x5F, 0x43, 0x0B, 0x54, 0x16, 0xD6, 0x50, 0xC4, 0xC0, 0x06, 0x58, 0xD4,
		0x36, 0x3B, 0x9C, 0x55, 0x53, 0xC6, 0xF3, 0x79, 0x3F, 0xB3, 0xAD, 0x6A, 0xE8, 0x12, 0x77, 0xC0,
		0x78, 0xCF, 0x4C, 0x90, 0x31, 0x56, 0x5B, 0xBB, 0x85, 0x87, 0xCC, 0x66, 0xE1, 0x54, 0x21, 0x1C,
		0xFB, 0x93, 0x54, 0xEF, 0xDA, 0xBB, 0x0B, 0x3F, 0xD9, 0x6E, 0xA2, 0xBB, 0xB9, 0x6D, 0x8B, 0xF8,
		0xEE, 0xFF, 0x00, 0x6A, 0x86, 0x1F, 0x9C, 0x5F, 0xD9, 0x4C, 0x9F, 0x16, 0x8F, 0x92, 0x1B, 0xEF,
		0x1F, 0xAD, 0x63, 0x45, 0x15, 0x26, 0xED, 0x96, 0x0A, 0x28, 0xA2, 0xB0, 0x02, 0x8A, 0x28, 0xA0,
		0x02, 0x8A, 0x28, 0xA0, 0x02, 0x8A, 0x28, 0xA0, 0x0F, 0xFF, 0xD9
};

uint8_t Space[1213] = {
		0xFF, 0xD8, 0xFF, 0xE0, 0x00, 0x10, 0x4A, 0x46, 0x49, 0x46, 0x00, 0x01, 0x01, 0x00, 0x00, 0x01,
		0x00, 0x01, 0x00, 0x00, 0xFF, 0xDB, 0x00, 0x43, 0x00, 0x08, 0x06, 0x06, 0x07, 0x06, 0x05, 0x08,
		0x07, 0x07, 0x07, 0x09, 0x09, 0x08, 0x0A, 0x0C, 0x14, 0x0D, 0x0C, 0x0B, 0x0B, 0x0C, 0x19, 0x12,
		0x13, 0x0F, 0x14, 0x1D, 0x1A, 0x1F, 0x1E, 0x1D, 0x1A, 0x1C, 0x1C, 0x20, 0x24, 0x2E, 0x27, 0x20,
		0x22, 0x2C, 0x23, 0x1C, 0x1C, 0x28, 0x37, 0x29, 0x2C, 0x30, 0x31, 0x34, 0x34, 0x34, 0x1F, 0x27,
		0x39, 0x3D, 0x38, 0x32, 0x3C, 0x2E, 0x33, 0x34, 0x32, 0xFF, 0xDB, 0x00, 0x43, 0x01, 0x09, 0x09,
		0x09, 0x0C, 0x0B, 0x0C, 0x18, 0x0D, 0x0D, 0x18, 0x32, 0x21, 0x1C, 0x21, 0x32, 0x32, 0x32, 0x32,
		0x32, 0x32, 0x32, 0x32, 0x32, 0x32, 0x32, 0x32, 0x32, 0x32, 0x32, 0x32, 0x32, 0x32, 0x32, 0x32,
		0x32, 0x32, 0x32, 0x32, 0x32, 0x32, 0x32, 0x32, 0x32, 0x32, 0x32, 0x32, 0x32, 0x32, 0x32, 0x32,
		0x32, 0x32, 0x32, 0x32, 0x32, 0x32, 0x32, 0x32, 0x32, 0x32, 0x32, 0x32, 0x32, 0x32, 0xFF, 0xC0,
		0x00, 0x11, 0x08, 0x00, 0xF0, 0x01, 0x40, 0x03, 0x01, 0x22, 0x00, 0x02, 0x11, 0x01, 0x03, 0x11,
		0x01, 0xFF, 0xC4, 0x00, 0x18, 0x00, 0x01, 0x01, 0x01, 0x01, 0x01, 0x00, 0x00, 0x00, 0x00, 0x00,
		0x00, 0x00, 0x00, 0x00, 0x00, 0x00, 0x00, 0x01, 0x07, 0x03, 0x06, 0xFF, 0xC4, 0x00, 0x2B, 0x10,
		0x01, 0x00, 0x02, 0x02, 0x01, 0x03, 0x03, 0x02, 0x05, 0x05, 0x00, 0x00, 0x00, 0x00, 0x00, 0x00,
		0x00, 0x01, 0x41, 0x11, 0x21, 0x31, 0x02, 0x51, 0x91, 0x03, 0x61, 0x71, 0x12, 0x81, 0x04, 0x05,
		0x13, 0xB1, 0xF0, 0x06, 0x22, 0x23, 0x32, 0xA1, 0xFF, 0xC4, 0x00, 0x15, 0x01, 0x01, 0x01, 0x00,
		0x00, 0x00, 0x00, 0x00, 0x00, 0x00, 0x00, 0x00, 0x00, 0x00, 0x00, 0x00, 0x00, 0x00, 0x01, 0xFF,
		0xC4, 0x00, 0x17, 0x11, 0x01, 0x01, 0x01, 0x01, 0x00, 0x00, 0x00, 0x00, 0x00, 0x00, 0x00, 0x00,
		0x00, 0x00, 0x00, 0x00, 0x00, 0x01, 0x21, 0x11, 0xFF, 0xDA, 0x00, 0x0C, 0x03, 0x01, 0x00, 0x02,
		0x11, 0x03, 0x11, 0x00, 0x3F, 0x00, 0xC2, 0x40, 0xFD, 0x85, 0x00, 0x00, 0x90, 0x40, 0x2C, 0x14,
		0x36, 0x7C, 0x9F, 0x00, 0x00, 0x22, 0x00, 0x2A, 0x9F, 0x21, 0x60, 0x80, 0x02, 0x80, 0x71, 0x20,
		0x06, 0x00, 0x00, 0xCA, 0x20, 0x00, 0xA6, 0x80, 0x50, 0x00, 0x02, 0xB2, 0x67, 0x4B, 0x40, 0x80,
		0x68, 0x40, 0x04, 0x0D, 0x09, 0xB8, 0x50, 0x03, 0xB8, 0xAA, 0x01, 0xA0, 0x00, 0x44, 0x03, 0x3A,
		0x05, 0x36, 0x40, 0x76, 0x03, 0x61, 0xBC, 0x8A, 0x40, 0x01, 0x16, 0x51, 0x61, 0x05, 0x00, 0x00,
		0x16, 0xC4, 0x42, 0x80, 0x0B, 0x09, 0x28, 0x03, 0x0B, 0x28, 0x80, 0x06, 0x69, 0x54, 0x01, 0x00,
		0x00, 0x0D, 0xC4, 0x02, 0xA0, 0x1C, 0x02, 0x86, 0xC0, 0x03, 0x40, 0x88, 0x64, 0x05, 0x0A, 0x0C,
		0x60, 0x00, 0x00, 0x00, 0x00, 0x0A, 0x40, 0xB0, 0x05, 0x03, 0xEC, 0x2A, 0x29, 0xCE, 0xD3, 0xDC,
		0x03, 0xE4, 0x0E, 0x50, 0x03, 0x91, 0x54, 0x05, 0xE4, 0x10, 0x0A, 0x10, 0x80, 0x38, 0xD2, 0x00,
		0x16, 0x00, 0x00, 0x7C, 0x93, 0xCE, 0x02, 0x3B, 0x28, 0x1C, 0x00, 0xA0, 0x08, 0x00, 0x50, 0x80,
		0x47, 0x02, 0x80, 0x65, 0x2C, 0x14, 0x04, 0x00, 0x14, 0x00, 0x00, 0x00, 0x39, 0x82, 0x80, 0x0D,
		0x87, 0xB8, 0x00, 0x00, 0x14, 0x08, 0x00, 0x28, 0x2F, 0x09, 0x38, 0x00, 0x00, 0x08, 0x01, 0x14,
		0x5E, 0x10, 0x54, 0x0B, 0x0B, 0x45, 0x00, 0x10, 0xC0, 0x0A, 0x40, 0x00, 0x00, 0x45, 0x85, 0x80,
		0x21, 0xEC, 0x18, 0x45, 0x14, 0x32, 0x00, 0x02, 0x00, 0x7C, 0x9A, 0x50, 0x00, 0x00, 0x28, 0x52,
		0x82, 0xF4, 0x21, 0x86, 0x57, 0x94, 0x15, 0x02, 0xA4, 0xFD, 0x84, 0x00, 0x81, 0x54, 0x00, 0x0D,
		0x00, 0x88, 0x00, 0xA1, 0x80, 0x10, 0x02, 0x85, 0x50, 0x00, 0x00, 0x44, 0x37, 0x20, 0x00, 0x00,
		0x00, 0x2A, 0x88, 0x02, 0x0A, 0x71, 0x09, 0x90, 0x5D, 0x06, 0x82, 0x80, 0x08, 0xA1, 0xC8, 0x2A,
		0x07, 0xB8, 0x52, 0x00, 0x24, 0xF0, 0x0B, 0x3C, 0x60, 0xA0, 0xC6, 0x85, 0x03, 0xDC, 0x54, 0x00,
		0x02, 0xCE, 0x40, 0xAA, 0x00, 0x88, 0x05, 0x0A, 0x01, 0x45, 0x0A, 0x12, 0x08, 0x80, 0x0A, 0x2E,
		0x50, 0x05, 0xD2, 0xB2, 0x2A, 0x00, 0x00, 0x1F, 0x20, 0x08, 0x22, 0xA6, 0x01, 0x50, 0x00, 0xE5,
		0x42, 0x39, 0x00, 0x00, 0x0B, 0x3E, 0xC0, 0x00, 0x01, 0x64, 0xEC, 0xE0, 0x14, 0x17, 0x94, 0x00,
		0x38, 0x83, 0x48, 0x05, 0x82, 0x80, 0x7B, 0x02, 0x00, 0x58, 0x18, 0x01, 0x00, 0x3F, 0x60, 0x0E,
		0x20, 0xA0, 0x14, 0x08, 0x15, 0x0E, 0x42, 0x81, 0x40, 0x10, 0x00, 0x54, 0x04, 0x51, 0x49, 0x30,
		0x96, 0x08, 0xBC, 0xC0, 0x00, 0x50, 0x00, 0x00, 0x00, 0x00, 0x06, 0x84, 0x00, 0x00, 0x05, 0x51,
		0x00, 0x00, 0x01, 0x42, 0x41, 0x10, 0xF9, 0x01, 0x40, 0xE0, 0x11, 0x40, 0x04, 0x08, 0xE4, 0x05,
		0x00, 0x50, 0x00, 0x40, 0x04, 0x00, 0xB1, 0x40, 0x2C, 0x14, 0xB4, 0x5E, 0x64, 0x10, 0x11, 0x40,
		0x00, 0x00, 0x38, 0x40, 0x00, 0x0A, 0x0B, 0x14, 0x0A, 0x23, 0x90, 0x03, 0x1D, 0xC0, 0x00, 0x10,
		0x00, 0x55, 0x24, 0x09, 0x40, 0x0D, 0x82, 0x2E, 0xF0, 0x87, 0x22, 0x81, 0xF0, 0x49, 0x42, 0x85,
		0x1F, 0x73, 0x02, 0x1A, 0x00, 0x50, 0x98, 0x01, 0x02, 0x80, 0x52, 0x83, 0xD8, 0xA0, 0x25, 0x14,
		0x10, 0xB4, 0x8E, 0x55, 0x00, 0x5D, 0x22, 0x80, 0x14, 0x20, 0x50, 0x02, 0x9C, 0x80, 0x20, 0x02,
		0xA8, 0x14, 0x00, 0x00, 0x80, 0x1E, 0xC8, 0x04, 0x82, 0xA8, 0x1E, 0xE0, 0x00, 0x00, 0x04, 0xC4,
		0x88, 0x00, 0x28, 0x04, 0xA2, 0x05, 0x16, 0x65, 0x40, 0xA0, 0xD8, 0x05, 0x05, 0x00, 0x14, 0x50,
		0xA1, 0x40, 0x22, 0x02, 0x80, 0x99, 0x59, 0x05, 0x00, 0xA1, 0x00, 0x00, 0x00, 0x00, 0xB0, 0x02,
		0xC3, 0x30, 0x28, 0x67, 0x60, 0x01, 0xEE, 0x00, 0x00, 0x20, 0x05, 0x0A, 0x00, 0x20, 0x06, 0x00,
		0x01, 0x02, 0x0B, 0x05, 0x00, 0x05, 0x34, 0x00, 0x81, 0x40, 0x29, 0x90, 0x00, 0x00, 0x02, 0x50,
		0x11, 0x4A, 0xC8, 0x01, 0x90, 0x0E, 0x28, 0x12, 0x22, 0x00, 0x28, 0x50, 0x08, 0x2C, 0xFF, 0x00,
		0xC4, 0x35, 0x42, 0x81, 0x93, 0x42, 0x01, 0x20, 0xA0, 0x00, 0xA1, 0xC8, 0x22, 0x00, 0x6D, 0x6A,
		0x80, 0x22, 0x14, 0x00, 0x00, 0x4A, 0xA8, 0x14, 0x68, 0x0F, 0x60, 0x2C, 0x00, 0x00, 0xD1, 0xB0,
		0xD8, 0x00, 0x58, 0x88, 0x2A, 0x02, 0x80, 0x00, 0x14, 0x81, 0x47, 0xC8, 0x00, 0x00, 0x00, 0x28,
		0x68, 0x0A, 0xCA, 0x2A, 0xE1, 0x01, 0x40, 0x2C, 0x00, 0x5C, 0xA2, 0x00, 0x0A, 0x86, 0xC0, 0x00,
		0x00, 0x00, 0x02, 0x83, 0xE0, 0x00, 0x0D, 0x80, 0x00, 0xA0, 0x02, 0x16, 0x12, 0x02, 0x2C, 0x82,
		0x07, 0x22, 0x0A, 0x28, 0x00, 0x51, 0xEE, 0x02, 0x96, 0x00, 0x00, 0x08, 0x1B, 0xC8, 0x50, 0x18,
		0x90, 0x00, 0xB0, 0x11, 0x40, 0x14, 0x58, 0x49, 0x00, 0x0D, 0x14, 0x08, 0x50, 0x02, 0x80, 0x08,
		0x01, 0x42, 0x80, 0x22, 0x16, 0x02, 0x86, 0x80, 0xA4, 0x0E, 0x00, 0x50, 0x00, 0x50, 0x45, 0x10,
		0x94, 0x27, 0x80, 0x16, 0x80, 0x00, 0x0C, 0xA0, 0xB2, 0x80, 0xB0, 0x00, 0x14, 0x08, 0x11, 0x03,
		0xEC, 0x58, 0xA0, 0x00, 0x16, 0x1B, 0x00, 0x00, 0x50, 0x00, 0x00, 0x44, 0x00, 0x50, 0x09, 0x80,
		0x0A, 0x01, 0x00, 0x75, 0x9E, 0xAE, 0x9E, 0x9E, 0x8F, 0x53, 0xA3, 0xA3, 0xD5, 0xEB, 0x9E, 0x99,
		0xEB, 0x8C, 0x47, 0xD3, 0x8F, 0xAB, 0x19, 0xDC, 0xEF, 0xF9, 0x95, 0xF5, 0x3D, 0x4F, 0xAB, 0xF5,
		0x7F, 0xCF, 0xEA, 0x75, 0xFD, 0x5E, 0xA4, 0x4E, 0xE3, 0xFD, 0xF9, 0xDC, 0xEF, 0xF9, 0x91, 0x5C,
		0x66, 0x05, 0xF5, 0xBF, 0x11, 0xEA, 0x7F, 0x77, 0xD5, 0xD7, 0xD5, 0xD5, 0xFA, 0x9D, 0x5F, 0x57,
		0x56, 0x67, 0x99, 0xFE, 0x4B, 0xD2, 0x7F, 0x43, 0xFE, 0x53, 0xD3, 0xF9, 0xA4, 0x7E, 0x3B, 0xEA,
		0xEB, 0xE9, 0xE8, 0x9F, 0x4F, 0xF4, 0xE6, 0x3A, 0xA7, 0xD3, 0x8E, 0xA9, 0xDC, 0xCF, 0x1E, 0x15,
		0x1E, 0x6F, 0x13, 0xDA, 0x7C, 0x26, 0x26, 0x2A, 0x7C, 0x37, 0x58, 0xE9, 0x88, 0x88, 0x8C, 0x71,
		0xEC, 0xB8, 0x8E, 0xD1, 0xE0, 0x18, 0x4E, 0x27, 0xB4, 0xF8, 0x5C, 0x4F, 0x69, 0x6E, 0xB8, 0x8E,
		0xD1, 0xE0, 0xC4, 0x76, 0x8F, 0x00, 0xC2, 0x71, 0x33, 0x53, 0xE0, 0xC4, 0xF6, 0x9F, 0x0D, 0xD7,
		0x11, 0xDA, 0x3C, 0x2E, 0x23, 0xB4, 0x78, 0x06, 0x13, 0x89, 0xCF, 0x13, 0xE0, 0xC4, 0xC7, 0x11,
		0x3E, 0x1B, 0xB6, 0x23, 0xB4, 0x78, 0x4C, 0x47, 0x68, 0xF0, 0x0F, 0xFF, 0xD9
};
#endif
/* ^^^^^ FOLDED ARRAY */
int compression_ratio = 0;

uint8_t SR=0x77;
uint8_t start=0x11;

uint16_t i=0;
uint16_t iLoop=0;
uint16_t jLoop=0;
uint16_t loop=0;

uint32_t adrs=0;

uint8_t WREN  =0x06;
uint8_t WRDI  =0x04;
uint8_t RDSR  =0x05;
uint8_t WRSR  =0x01;
uint8_t READ_3ByteAdd  =0x03;
uint8_t READ_4ByteAdd  =0x13;
uint8_t WRITE_3ByteAdd =0x02;
uint8_t WRITE_4ByteAdd =0x12;

uint8_t ERASE =0x20;
uint8_t SECTORERASE_3ByteAdd =0xD8;
uint8_t SECTORERASE_4ByteAdd =0xDC;
uint8_t GETDATA =0x00;

int *pDataByte;
uint8_t StringLength=0;
char txString [50];
char Rx_indx, Rx_Buffer[100], Transfer_cplt;
char Rx_dataDBG[2]={0x11, 0x11};
char Rx_dataCAM[2]={0x33, 0x33};
uint8_t commandCAM=0x29;

#define csDelay 10
#define tiniestDelay 10
#define tinyDelay    100
#define fareDelay    2000

uint8_t handshakeCAM = 0;
uint8_t ACKtoCAM = 0x28;

uint8_t colored = 0x31;
uint8_t black = 0x32;
uint8_t error = 0x33;

uint8_t width_ack = 0x11;
uint8_t height_ack = 0x22;

uint8_t CAM_reso = 0;
uint8_t CAM_reso_W = 0;
uint8_t CAM_reso_H = 0;

uint8_t Earth_ICU = 0x31;
uint8_t Space_ICU = 0x32;
uint8_t Error_ICU = 0x33;

int Width = 0;
int Height = 0;
int Multiplier = 0;

int break_loop = 0;
int count = 0;
/* USER CODE END PV */

void SystemClock_Config(void);
/* USER CODE BEGIN PFP */
static void rgb2gray_uint8_T(uint8_t* Img, int channels, int width, int height, int compression, uint8_t result[76800]);
static void main_dataconverter(double Umat[14688], uint8_t* image, double imgdat[35]);
uint16_t in_func (JDEC* jd, uint8_t* buff, uint16_t nbyte);
uint16_t out_func (JDEC* jd, void* bitmap, JRECT* rect);
static void prepocess(uint8_t* Img, float result[19200*2]);
int ReadSR(void);

#ifdef __GNUC__
#define PUTCHAR_PROTOTYPE int __io_putchar(int ch)
#define GETCHAR_PROTOTYPE int __io_getchar(void)
#else
#define PUTCHAR_PROTOTYPE int fputc(int ch, FILE *f)
#define GETCHAR_PROTOTYPE int fgetc(FILE *f)
#endif
PUTCHAR_PROTOTYPE
{
HAL_UART_Transmit(&huart1, (uint8_t *)&ch, 1, HAL_MAX_DELAY);
return ch;
}
GETCHAR_PROTOTYPE
{
uint8_t ch = 0;

/* Clear the Overrun flag just before receiving the first character */
__HAL_UART_CLEAR_OREFLAG(&huart1);
/* Wait for reception of a character on the USART RX line and echo this

character on console */
HAL_UART_Receive(&debugPort, (uint8_t *)&ch, 1, HAL_MAX_DELAY);
HAL_UART_Transmit(&debugPort, (uint8_t *)&ch, 1, HAL_MAX_DELAY);
return ch;
}

/* USER CODE END PFP */

/* USER CODE BEGIN 0 */
typedef struct {
    uint32_t fp;          																							/* File pointer for input function */
    uint8_t *fbuf;     																								/* Pointer to the frame buffer for output function */
    uint16_t wfbuf;    																								/* Width of the frame buffer [pix] */
} IODEV;

uint16_t in_func (JDEC* jd, uint8_t* buff, uint16_t nbyte)
{
    IODEV *dev = (IODEV*)jd->device;   																				/* Device identifier for the session (5th argument of jd_prepare function) */
    int i;

    if (buff) {
//    	read_bulk_4ByteAdd_SharedFM(dev->fp, buff, nbyte);
//    	read_bulk_4ByteAdd_LocalFM(dev->fp, buff, nbyte);
    	W25qxx_ReadBytes( buff, dev->fp, nbyte );

    	StringLength=sprintf(txString,"Value from FM %02X and Address %04u \r\n",*(buff+nbyte-1),dev->fp-1);
    	HAL_UART_Transmit(&debugPort, (uint8_t *) &txString, StringLength, 100);

    	dev->fp += nbyte;

        return nbyte;
    } else {
    	/* Remove bytes from input stream */
    	dev->fp += nbyte;
        return nbyte;
    }
}

uint16_t out_func (JDEC* jd, void* bitmap, JRECT* rect)
{
    IODEV *dev = (IODEV*)jd->device;
    uint8_t *src, *dst;
    uint16_t y, bws, bwd;

    /* Copy the decompressed RGB rectangular to the frame buffer (assuming RGB888 cfg) */
    src = (uint8_t*)bitmap;
    dst = dev->fbuf + N_BPP * (rect->top * dev->wfbuf + rect->left);  													/* Left-top of destination rectangular */
    bws = N_BPP * (rect->right - rect->left + 1);     																	/* Width of source rectangular [byte] */
    bwd = N_BPP * dev->wfbuf;                         																	/* Width of frame buffer [byte] */
    for (y = rect->top; y <= rect->bottom; y++) {
        memcpy(dst, src, bws);   																					/* Copy a line */
        src += bws; dst += bwd;  																					/* Next line */
    }

    return 1;    																									/* Continue to decompress */
}

/* USER CODE END 0 */

int main(void)
{
  /* USER CODE BEGIN 1 */
	  //(void)argc;
	  //(void)argv;
	  void *work;       																								/* Pointer to the decompressor work area */
	  JDEC jdec;        																								/* Decompression object */
	  JRESULT res;      																								/* Result code of TJpgDec API */
	  IODEV devid;      																								/* User defined device identifier */
	  int i;
	  int image_size = 0;

	  double predict;
	  uint8_t SR = 0x24;

	  size_t sz_work = 5100;

	  char buf[50];
	  int buf_len = 0;

	  ai_error ai_err;
	  ai_error ai_err_ICU;

	  ai_i32 nbatch;
	  ai_i32 nbatch_ICU;

	  uint32_t timestamp;
	  uint32_t timestamp_ICU;

	  uint8_t prediction = 0xFF;

	  float y_val;

	  // Chunk of memory used to hold intermediate values for neural network
	  ai_u8 activations[AI_SINE_MODEL_DATA_ACTIVATIONS_SIZE];

	  // Buffers used to store input and output tensors
	  ai_i8 in_data[AI_SINE_MODEL_IN_1_SIZE_BYTES];
	  ai_i8 out_data[AI_SINE_MODEL_OUT_1_SIZE_BYTES];

	  // Pointer to our model
	  ai_handle sine_model = AI_HANDLE_NULL;

	  // Initialize wrapper structs that hold pointers to data and info about the
	  // data (tensor height, width, channels)
	  ai_buffer ai_input[AI_SINE_MODEL_IN_NUM] = AI_SINE_MODEL_IN;
	  ai_buffer ai_output[AI_SINE_MODEL_OUT_NUM] = AI_SINE_MODEL_OUT;

	  // Set working memory and get weights/biases from model
	  ai_network_params ai_params = {
	    AI_SINE_MODEL_DATA_WEIGHTS(ai_sine_model_data_weights_get()),
	    AI_SINE_MODEL_DATA_ACTIVATIONS(activations)
	  };

	  // Chunk of memory used to hold intermediate values for neural network
	  ai_u8 activations_ICU[AI_NETWORK_DATA_ACTIVATIONS_SIZE];

	  // Buffers used to store input and output tensors
	  ai_i8 image[AI_NETWORK_IN_1_SIZE_BYTES];
	  ai_i8 out_data_ICU[AI_NETWORK_OUT_1_SIZE_BYTES];

	  // Pointer to our model
	  ai_handle icu_tflite = AI_HANDLE_NULL;

	  // Initialize wrapper structs that hold pointers to data and info about the
	  // data (tensor height, width, channels)
	  ai_buffer ai_input_ICU[AI_NETWORK_IN_NUM] = AI_NETWORK_IN;
	  ai_buffer ai_output_ICU[AI_NETWORK_OUT_NUM] = AI_NETWORK_OUT;

	  // Set working memory and get weights/biases from model
//	  ai_network_params ai_params_ICU = AI_NETWORK_PARAMS_INIT(AI_NETWORK_DATA_WEIGHTS(ai_network_data_weights_get()), AI_NETWORK_DATA_ACTIVATIONS(activations_ICU));
	  ai_network_params ai_params_ICU = {
			  AI_NETWORK_DATA_WEIGHTS(ai_network_data_weights_get()),
			  AI_NETWORK_DATA_ACTIVATIONS(activations_ICU)
	  };

	  //		ai_input_ICU[0].n_batches = 1;
	  		ai_input_ICU[0].data = AI_HANDLE_PTR(image);
	  //		ai_output_ICU[0].n_batches = 1;
	  		ai_output_ICU[0].data = AI_HANDLE_PTR(out_data_ICU);

	  		//End of ICU part 2

	  	  // Set pointers wrapper structs to our data buffers
	  //	  ai_input[0].n_batches = 1;
	  	  ai_input[0].data = AI_HANDLE_PTR(in_data);
	  //	  ai_output[0].n_batches = 1;
	  	  ai_output[0].data = AI_HANDLE_PTR(out_data);

  /* USER CODE END 1 */

  /* Enable I-Cache---------------------------------------------------------*/
  SCB_EnableICache();

  /* Enable D-Cache---------------------------------------------------------*/
  SCB_EnableDCache();

  /* MCU Configuration--------------------------------------------------------*/

  /* Reset of all peripherals, Initializes the Flash interface and the Systick. */
  HAL_Init();

  /* Configure the system clock */
  SystemClock_Config();

  /* USER CODE BEGIN SysInit */

  //serialPortDebug huart1
  //serialPortCAM huart2
  //shrdPortFM hspi4
  //localPortFM hspi4

  /* USER CODE END SysInit */

  /* Initialize all configured peripherals */
  MX_GPIO_Init();
  MX_DMA_Init();
  MX_SPI4_Init();
  MX_USART1_UART_Init();
  MX_SPI1_Init();
  MX_SPI3_Init();
  MX_QUADSPI_Init();
  MX_USART2_UART_Init();
  MX_TIM14_Init();
  MX_CRC_Init();
  MX_TIM13_Init();
  /* USER CODE BEGIN 2 */
  W25qxx_Init();

//  HAL_Delay(5000);

  //#define testPortFM shrdPortFM //shrdPortFM or localPortFM

  printf("GRSS Satellite .. ICU code \r\n--------------------------\r\n");
  HAL_GPIO_WritePin(GPIOB, GPIO_PIN_10, GPIO_PIN_RESET); // Control the sharedFM, SET=STM32 RESET=ATMEGA
  HAL_Delay(100);

  char readBytes[5000]="ABC";

//	uint8_t* Target;
#define Target  Space

	W25qxx_EraseBlock(0);

	HAL_Delay(10);
	W25qxx_ReadBytes( readBytes, 0, sizeof(Target)%sizeof(readBytes) );

	HAL_Delay(10);
	W25qxx_WriteBlock(Target, 0, 0, sizeof(Target));

	StringLength=sprintf(txString,"\r\nTarget size=%d,Space size=%d, Earth size=%d\r\n",sizeof(Target),sizeof(Space),sizeof(Earth));
	HAL_UART_Transmit(&debugPort, (uint8_t *) &txString, StringLength, 100);

	compression_ratio = 1;

	  // Greetings!
	  buf_len = sprintf(buf, "\r\n\r\nSTM32 X-Cube-AI\r\n");
	  HAL_UART_Transmit(&debugPort, (uint8_t *) &buf, buf_len, 100);

	  // Create instance of neural network
	  ai_err = ai_sine_model_create(&sine_model, AI_SINE_MODEL_DATA_CONFIG);
	  if (ai_err.type != AI_ERROR_NONE)
	  {
	    buf_len = sprintf(buf, "Error: could not create NN instance\r\n");
	    HAL_UART_Transmit(&debugPort, (uint8_t *)buf, buf_len, 100);
	    while(1);
	  }
	  else
	  {
		    buf_len = sprintf(buf, "NN instance created! \r\n");
		    HAL_UART_Transmit(&debugPort, (uint8_t *) &buf, buf_len, 100);
	  }

	  // Initialize neural network
	  if (!ai_sine_model_init(sine_model, &ai_params))
	  {
	    buf_len = sprintf(buf, "Error: could not initialize NN\r\n");
	    HAL_UART_Transmit(&debugPort, (uint8_t *)buf, buf_len, 100);
	    while(1);
	  }
	  else
	  {
		    buf_len = sprintf(buf, "NN initialized\r\n");
		    HAL_UART_Transmit(&debugPort, (uint8_t *) &buf, buf_len, 100);
	  }

	  // Create instance of neural network
	  ai_err_ICU = ai_network_create(&icu_tflite, AI_NETWORK_DATA_CONFIG);
	  if (ai_err_ICU.type != AI_ERROR_NONE)
	  {
	    buf_len = sprintf(buf, "Error: could not create NN instance\r\n");
	    HAL_UART_Transmit(&debugPort, (uint8_t *) &buf, buf_len, 100);
	    while(1);
	  }
	  else
	  {
		    buf_len = sprintf(buf, "NN instance created! \r\n");
		    HAL_UART_Transmit(&debugPort, (uint8_t *) &buf, buf_len, 100);
	  }

	  // Initialize neural network
	  if (!ai_network_init(icu_tflite, &ai_params_ICU))
	  {
	    buf_len = sprintf(buf, "Error: could not initialize NN\r\n");
	    HAL_UART_Transmit(&debugPort, (uint8_t *) &buf, buf_len, 100);
	    while(1);
	  }
	  else
	  {
		    buf_len = sprintf(buf, "NN initialized\r\n");
		    HAL_UART_Transmit(&debugPort, (uint8_t *) &buf, buf_len, 100);
	  }
  /* USER CODE END 2 */

  /* Infinite loop */
  /* USER CODE BEGIN WHILE */
  while (1)
  {
		printf("Loop\r\n");

		work = (void*)malloc(sz_work);
	  	count++;

	  	if (count == 1) {
	  		W25qxx_ReadBytes( readBytes, 0, sizeof(Target) );
	  	}

		  // Fill input buffer (use test value)
			for (uint32_t i = 0; i < AI_SINE_MODEL_IN_1_SIZE; i++)
			{
			  ((ai_float *)in_data)[i] = (ai_float)1.0f;
			}

			// Get current timestamp
			timestamp = htim13.Instance->CNT;

			// Perform inference
			nbatch = ai_sine_model_run(sine_model, &ai_input[0], &ai_output[0]);
			if (nbatch != 1) {
			  buf_len = sprintf(buf, "Error: could not run inference\r\n");
			  HAL_UART_Transmit(&debugPort, (uint8_t *)buf, buf_len, 100);
			}

			// Read output (predicted y) of neural network
			y_val = ((float *)out_data)[0];

			// Print output of neural network along with inference time (microseconds)
			buf_len = sprintf(buf,
							  "Output: %f | Duration: %lu\r\n",
							  y_val,
							  htim13.Instance->CNT - timestamp);
			HAL_UART_Transmit(&debugPort, (uint8_t *)buf, buf_len, 100);

			// Wait before doing it again
			HAL_Delay(500);

	  	handshakeCAM = 0;

	  	 // 	if (__HAL_UART_GET_FLAG(&huart3, UART_FLAG_RXNE) == SET) {
	  	  //		HAL_UART_Receive(&huart3, (uint8_t *) &handshakeCAM, 1, 1000);												/* Wait for CAM to command ICU, expects 0x29*/
	  	  //		__HAL_UART_CLEAR_FLAG(&huart3, UART_FLAG_RXNE);

	  	  		//if (handshakeCAM == 0x29) {
	  	  			StringLength=sprintf(txString,"\r\n\nImage Processing Starts Now\r\n");
	  	  			HAL_UART_Transmit(&debugPort, (uint8_t *) &txString, StringLength, 100);

	  	  			HAL_Delay(1000);
	  	  			devid.fp=0;
//	  	  			devid.fp= Space;

	  				StringLength=sprintf(txString,"\r\n");
	  				HAL_UART_Transmit(&debugPort, (uint8_t *) &txString, StringLength, 100);

	  	//			display_bulk_4ByteAdd_SharedFM(0x00000000, 3500);

	  	  			res = jd_prepare(&jdec, in_func, work, sz_work, &devid);													/* Prepare to decompress */
	  	  			if (res == JDR_OK)
	  	  			{																					/* Ready to decompress. Image info is available here. */
	  	  				StringLength=sprintf(txString,"\r\n\nOriginal image size is %u x %u X 3.\r\n%u Bytes of work area is used.\r\n\n", jdec.width, jdec.height, sz_work - jdec.sz_pool);
	  	  				HAL_UART_Transmit(&debugPort, (uint8_t *) &txString, StringLength, 100);

	  	  				image_size = N_BPP  * jdec.width * jdec.height;
	  	  				devid.fbuf = (uint8_t*)malloc(image_size); /* Create frame buffer for output image */
	  	  		        devid.wfbuf = jdec.width;

	  					Width = jdec.width;
	  					Height = jdec.height;

	  	  				StringLength=sprintf(txString,"\r\n\nPreparation for Decompression - Success\r\n");
	  	  				HAL_UART_Transmit(&debugPort, (uint8_t *) &txString, StringLength, 100);

	  	  				res = jd_decomp(&jdec, out_func, compression_ratio);   																/* Start to decompress with 1-1 scaling*/
	  	  				if (res == JDR_OK) {
	  	  					StringLength=sprintf(txString,"Decompression - Success\r\n");
	  	  					HAL_UART_Transmit(&debugPort, (uint8_t *) &txString, StringLength, 100);
	  	  				}
	  	  				else{
	  	  					StringLength=sprintf(txString,"%d - Decompression - Failed\r\n",res);
	  	  					HAL_UART_Transmit(&debugPort, (uint8_t *) &txString, StringLength, 100);
	  	  				}
	  	  			}
	  	  			else{
	  	  			  StringLength=sprintf(txString,"\r\n\n %d - Preparation for Decompression - Failed\r\n",res);
	  	  			  HAL_UART_Transmit(&debugPort, (uint8_t *) &txString, StringLength, 100);
	  	  			}

	  	  			HAL_Delay(1000);

//					ai_input_ICU[0].data = AI_HANDLE_PTR(image);
////	  				ai_output_ICU[0].n_batches = 1;
//					ai_output_ICU[0].data = AI_HANDLE_PTR(out_data_ICU);

	  	  			// Image Classification Section
	  	  		    for (uint32_t  ii = 0; ii < AI_NETWORK_IN_1_SIZE; ii++)
	  	  		    {
//	  	  		    	image[ii] = *(devid.fbuf + ii);
	  	  		        ((ai_u8 *)image)[ii] = *(devid.fbuf + ii);
	  	  		    }

	  	  		// Get current timestamp
	  	  		timestamp_ICU = htim14.Instance->CNT;

	  	  		    // Perform inference
	  	  		    nbatch_ICU = ai_network_run(icu_tflite, &ai_input_ICU[0], &ai_output_ICU[0]);

	  	  		    if (nbatch_ICU != 1) {
	  	  		      buf_len = sprintf(buf, "Error: could not run inference. nbatch_ICU=%lu\r\n",(int32_t)nbatch_ICU);
	  	  		      HAL_UART_Transmit(&debugPort, (uint8_t *) &buf, buf_len, 100);
	  	  		    }
	  	  		    else
	  	  		    {
	  	  		  	    buf_len = sprintf(buf, "\r\nRunning ICU tflite done!\r\n");
	  	  		  	    HAL_UART_Transmit(&debugPort, (uint8_t *) &buf, buf_len, 100);
	  	  		    }

	  	  		    float max_val = -1;

	  	  		    for(int i = 0; i < AI_NETWORK_OUT_1_SIZE; i++)
	  	  		    {
	  	  		        if(max_val < out_data_ICU[i])
	  	  		        {
	  	  		            max_val = out_data_ICU[i];
	  	  		            prediction = i;

	  						StringLength=sprintf(txString,"\r\n\nIndex:  %ld ", (long)prediction);
	  						HAL_UART_Transmit(&debugPort, (uint8_t *) &txString, StringLength, 100);
	  	  		        }
	  	  		    }

	  	  		    prediction = prediction;

	  	  		// Print output of neural network along with inference time (microseconds)
	  	  		StringLength = sprintf(txString,"Output: %f | Duration: %lu\r\n", prediction, htim14.Instance->CNT - timestamp_ICU);
	  	  		HAL_UART_Transmit(&debugPort, (uint8_t *)txString, buf_len, 100);

	  	  		    if (prediction == 1)
	  	  		    {
	  	  				StringLength=sprintf(txString,"\r\nPrediction:  Space \r\n");
	  	  				HAL_UART_Transmit(&debugPort, (uint8_t *) &txString, StringLength, 100);
//	  	  				HAL_UART_Transmit(&huart3, (uint8_t *) &Space_ICU, 1, 100);
	  	  		    }
	  	  		    else if (prediction == 0)
	  	  		    {
	  	  				StringLength=sprintf(txString,"\r\nPrediction:  Earth \r\n");
	  	  				HAL_UART_Transmit(&debugPort, (uint8_t *) &txString, StringLength, 100);
//	  	  				HAL_UART_Transmit(&huart3, (uint8_t *) &Earth_ICU, 1, 100);
	  	  		    }
	  	  		    else
	  	  		    {
	  	  				StringLength=sprintf(txString,"\r\nError Prediction \r\n");
	  	  				HAL_UART_Transmit(&debugPort, (uint8_t *) &txString, StringLength, 100);
//	  	  				HAL_UART_Transmit(&huart3, (uint8_t *) &Error_ICU, 1, 100);
	  	  		    }

	  	  	  	if (count == 10000) {
	  	  	  		count = 0;																									/* Reset to zero to prevent overflowing bugs */
	  	  	  	}
    /* USER CODE END WHILE */

    /* USER CODE BEGIN 3 */

	  	  		free(work);   /* Discard work area */
	  	  		free(devid.fbuf);
  }
  /* USER CODE END 3 */
}

void SystemClock_Config(void)
{
  RCC_OscInitTypeDef RCC_OscInitStruct = {0};
  RCC_ClkInitTypeDef RCC_ClkInitStruct = {0};

  /** Configure the main internal regulator output voltage
  */
  __HAL_RCC_PWR_CLK_ENABLE();
  __HAL_PWR_VOLTAGESCALING_CONFIG(PWR_REGULATOR_VOLTAGE_SCALE1);

  /** Initializes the RCC Oscillators according to the specified parameters
  * in the RCC_OscInitTypeDef structure.
  */
  RCC_OscInitStruct.OscillatorType = RCC_OSCILLATORTYPE_HSI;
  RCC_OscInitStruct.HSIState = RCC_HSI_ON;
  RCC_OscInitStruct.HSICalibrationValue = RCC_HSICALIBRATION_DEFAULT;
  RCC_OscInitStruct.PLL.PLLState = RCC_PLL_ON;
  RCC_OscInitStruct.PLL.PLLSource = RCC_PLLSOURCE_HSI;
  RCC_OscInitStruct.PLL.PLLM = 8;
  RCC_OscInitStruct.PLL.PLLN = 216;
  RCC_OscInitStruct.PLL.PLLP = RCC_PLLP_DIV2;
  RCC_OscInitStruct.PLL.PLLQ = 2;
  RCC_OscInitStruct.PLL.PLLR = 2;
  if (HAL_RCC_OscConfig(&RCC_OscInitStruct) != HAL_OK)
  {
    Error_Handler();
  }

  /** Activate the Over-Drive mode
  */
  if (HAL_PWREx_EnableOverDrive() != HAL_OK)
  {
    Error_Handler();
  }

  /** Initializes the CPU, AHB and APB buses clocks
  */
  RCC_ClkInitStruct.ClockType = RCC_CLOCKTYPE_HCLK|RCC_CLOCKTYPE_SYSCLK
                              |RCC_CLOCKTYPE_PCLK1|RCC_CLOCKTYPE_PCLK2;
  RCC_ClkInitStruct.SYSCLKSource = RCC_SYSCLKSOURCE_PLLCLK;
  RCC_ClkInitStruct.AHBCLKDivider = RCC_SYSCLK_DIV1;
  RCC_ClkInitStruct.APB1CLKDivider = RCC_HCLK_DIV4;
  RCC_ClkInitStruct.APB2CLKDivider = RCC_HCLK_DIV2;

  if (HAL_RCC_ClockConfig(&RCC_ClkInitStruct, FLASH_LATENCY_7) != HAL_OK)
  {
    Error_Handler();
  }
}

/* USER CODE BEGIN 4 */
void blink(uint8_t time)
{
	HAL_GPIO_WritePin(GPIOD, GPIO_PIN_12, GPIO_PIN_SET);
	HAL_Delay(time);
	HAL_GPIO_WritePin(GPIOD, GPIO_PIN_12, GPIO_PIN_RESET);
	HAL_Delay(time);
}

void localChipSelect(void)
{
	HAL_Delay(10);
	HAL_GPIO_WritePin(GPIOA, GPIO_PIN_4, GPIO_PIN_RESET); //CS pin low to enable
	HAL_GPIO_WritePin(GPIOD, GPIO_PIN_13, GPIO_PIN_SET); //Set LED 3 to high
}

void localChipDeSelect(void)
{
	HAL_GPIO_WritePin(GPIOA, GPIO_PIN_4, GPIO_PIN_SET); //CS pin high to disable
	HAL_GPIO_WritePin(GPIOD, GPIO_PIN_13, GPIO_PIN_RESET); //Set LED 3 to low
	HAL_Delay(10);
}

void sharedChipSelect(void)
{
	HAL_Delay(10);
	HAL_GPIO_WritePin(GPIOB, GPIO_PIN_12, GPIO_PIN_RESET); //CS pin low to enable
	HAL_GPIO_WritePin(GPIOD, GPIO_PIN_14, GPIO_PIN_SET); //Set LED 2 to high
}

void sharedChipDeSelect(void)
{
	HAL_GPIO_WritePin(GPIOB, GPIO_PIN_12, GPIO_PIN_SET); //CS pin high to disable
	HAL_GPIO_WritePin(GPIOD, GPIO_PIN_14, GPIO_PIN_RESET); //Set LED 2 to low
	HAL_Delay(10);
}

void WRENABLE_LocalFM(void)
{
	localChipSelect();
	HAL_Delay(10);
	HAL_SPI_Transmit(&hspi4, (uint8_t *) &WREN, 1, 10);
	//HAL_SPI_Transmit(&hspi4, (uint8_t *) &WREN, 1, 10);
	//HAL_SPI_Transmit(&hspi4, (uint8_t *) &WREN, 1, 10);
	HAL_Delay(10);
	localChipDeSelect();
}

void WRENABLE_SharedFM(void)
{
	sharedChipSelect();
	HAL_Delay(10);
	HAL_SPI_Transmit(&hspi1, (uint8_t *) &WREN, 1, 10);
	//HAL_SPI_Transmit(&hspi4, (uint8_t *) &WREN, 1, 10);
	//HAL_SPI_Transmit(&hspi4, (uint8_t *) &WREN, 1, 10);
	HAL_Delay(10);
	sharedChipDeSelect();
}

void writeSR(uint8_t StatusR)
{
	  WRENABLE_LocalFM();
	  HAL_Delay(10);
	  localChipSelect();
	  HAL_GPIO_WritePin(GPIOA, GPIO_PIN_4, GPIO_PIN_RESET);
	  HAL_GPIO_WritePin(GPIOD, GPIO_PIN_12, GPIO_PIN_SET);
	  HAL_Delay(10);
	  HAL_SPI_Transmit(&hspi4, (uint8_t *) &WRSR, 1, 10);
	  HAL_SPI_Transmit(&hspi4, (uint8_t *) &StatusR, 1, 10);
	  //HAL_SPI_Transmit(&hspi4, (uint8_t *) &WREN, 1, 10);
	  HAL_Delay(10);
  	  HAL_GPIO_WritePin(GPIOD, GPIO_PIN_12, GPIO_PIN_RESET);
	  HAL_GPIO_WritePin(GPIOA, GPIO_PIN_4, GPIO_PIN_SET);
	  HAL_Delay(10);
	  localChipDeSelect();
	  ReadSR();

}

int ReadSR(void)
{
	uint8_t SR=0x22;

	HAL_Delay(10);
	HAL_GPIO_WritePin(GPIOA, GPIO_PIN_4, GPIO_PIN_RESET);
	HAL_GPIO_WritePin(GPIOD, GPIO_PIN_12, GPIO_PIN_SET);

	HAL_Delay(10);
	HAL_SPI_Transmit(&hspi4, (uint8_t *) &RDSR, 1, 10);
	//HAL_SPI_TransmitReceive(&hspi4, (uint8_t *) &RDSR, (uint8_t *) &SR,  1, 10);
	//HAL_Delay(10);
	//HAL_SPI_TransmitReceive(&hspi4, (uint8_t *) &RDSR, (uint8_t *) &SR,  1, 10);
	HAL_SPI_Receive(&hspi4, (uint8_t *) &SR, 1, 10); //HAL_Delay(100);
	HAL_Delay(10);
	HAL_GPIO_WritePin(GPIOD, GPIO_PIN_12, GPIO_PIN_RESET);
	HAL_GPIO_WritePin(GPIOA, GPIO_PIN_4, GPIO_PIN_SET);
	HAL_Delay(10);

	//SR=0xFF;
	//HAL_UART_Transmit(&huart2, (uint8_t *) "\n\r SPIa \n\r", strlen("\n\r loop \n\r"), 10);
	//char comment[]="\r\n\n***Image Classification Unit****\r\n\r\n\nby: Tim and AC\r\n";
	//HAL_UART_Transmit(&huart1, (uint8_t *) &comment, 1, 10);
	//HAL_UART_Transmit(&huart1, (uint8_t *) &SR, 1, 10);
	//HAL_UART_Transmit(&huart1, "\n", 1, 10);

	return SR;
}

void eraseSector_4ByteAdd_LocalFM(uint32_t StartingAddr)
{
	uint8_t B0Add=((StartingAddr>> 24) & 0xFF);
	uint8_t B1Add=((StartingAddr>> 16) & 0xFF);
	uint8_t B2Add=((StartingAddr>> 8) & 0xFF);
	uint8_t B3Add=((StartingAddr) & 0xFF);

	WRENABLE_LocalFM();
	localChipSelect();
	HAL_Delay(10);

	//Sending the erase command
	HAL_SPI_Transmit(&hspi4, (uint8_t *) &SECTORERASE_4ByteAdd, 1, 10);

	//Sending the addresses to be erased
	HAL_SPI_Transmit(&hspi4, (uint8_t *) &B0Add, 1, 10);
	HAL_SPI_Transmit(&hspi4, (uint8_t *) &B1Add, 1, 10);
	HAL_SPI_Transmit(&hspi4, (uint8_t *) &B2Add, 1, 10);
	HAL_SPI_Transmit(&hspi4, (uint8_t *) &B3Add, 1, 10);

	HAL_Delay(10);
	HAL_Delay(5000);
	localChipDeSelect();
	HAL_Delay(5000);

	StringLength=sprintf(txString,"\r\n\nErasing Sector With Starting Address %X in Local FM \r\n",StartingAddr);
	HAL_UART_Transmit(&debugPort, (uint8_t *) &txString, StringLength, 100);
}

void eraseSector_4ByteAdd_SharedFM(uint32_t StartingAddr)
{
	uint8_t B0Add=((StartingAddr>> 24) & 0xFF);
	uint8_t B1Add=((StartingAddr>> 16) & 0xFF);
	uint8_t B2Add=((StartingAddr>> 8) & 0xFF);
	uint8_t B3Add=((StartingAddr) & 0xFF);

	WRENABLE_SharedFM();
	sharedChipSelect();
	HAL_Delay(10);

	//Sending the erase command
	HAL_SPI_Transmit(&hspi1, (uint8_t *) &SECTORERASE_4ByteAdd, 1, 10);
	//Sending the addresses to be erased
	HAL_SPI_Transmit(&hspi1, (uint8_t *) &B0Add, 1, 10);
	HAL_SPI_Transmit(&hspi1, (uint8_t *) &B1Add, 1, 10);
	HAL_SPI_Transmit(&hspi1, (uint8_t *) &B2Add, 1, 10);
	HAL_SPI_Transmit(&hspi1, (uint8_t *) &B3Add, 1, 10);

	HAL_Delay(10);
	sharedChipDeSelect();
	HAL_Delay(2000);

	StringLength=sprintf(txString,"\r\n\nErasing Sector With Starting Address %X in Shared FM \r\n", StartingAddr);
	HAL_UART_Transmit(&debugPort, (uint8_t *) &txString, StringLength, 100);
}

void write_4ByteAdd_LocalFM(uint32_t Addr, uint8_t writeDataByte)
{
	uint8_t B0Add=((Addr>> 24) & 0xFF);		// 0x _ _ 00 00 00
	uint8_t B1Add=((Addr>> 16) & 0xFF);		// 0x 00 _ _ 00 00
	uint8_t B2Add=((Addr>> 8) & 0xFF);		// 0x 00 00 _ _ 00
	uint8_t B3Add=((Addr) & 0xFF);			// 0x 00 00 00 _ _

	WRENABLE_LocalFM();
	localChipSelect();

	//Sending the write command
	HAL_SPI_Transmit(&hspi4, (uint8_t *) &WRITE_4ByteAdd, 1, 100);

	//Sending the address
	HAL_SPI_Transmit(&hspi4, (uint8_t *) &B0Add, 1, 100);
	HAL_SPI_Transmit(&hspi4, (uint8_t *) &B1Add, 1, 100);
	HAL_SPI_Transmit(&hspi4, (uint8_t *) &B2Add, 1, 100);
	HAL_SPI_Transmit(&hspi4, (uint8_t *) &B3Add, 1, 100);

	//Sending the data byte
	HAL_SPI_Transmit(&hspi4, (uint8_t *) &writeDataByte, 1, 100);

	//printing into debug terminal
	StringLength=sprintf(txString,"Wrote %X in LocalFM address %X%X%X%X\r\n",writeDataByte,B0Add,B1Add,B2Add,B3Add);
	HAL_UART_Transmit(&debugPort, (uint8_t *) &txString, StringLength, 100);

	localChipDeSelect();
	HAL_Delay(20);

	return;
}

void write_4ByteAdd_SharedFM(uint32_t Addr, uint8_t writeDataByte)
{
	uint8_t B0Add=((Addr>> 24) & 0xFF);		// 0x _ _ 00 00 00
	uint8_t B1Add=((Addr>> 16) & 0xFF);		// 0x 00 _ _ 00 00
	uint8_t B2Add=((Addr>> 8) & 0xFF);		// 0x 00 00 _ _ 00
	uint8_t B3Add=((Addr) & 0xFF);			// 0x 00 00 00 _ _

	WRENABLE_SharedFM();
	sharedChipSelect();

	//Sending the write command
	HAL_SPI_Transmit(&hspi1, (uint8_t *) &WRITE_4ByteAdd, 1, 100);

	//Sending the address
	HAL_SPI_Transmit(&hspi1, (uint8_t *) &B0Add, 1, 100);
	HAL_SPI_Transmit(&hspi1, (uint8_t *) &B1Add, 1, 100);
	HAL_SPI_Transmit(&hspi1, (uint8_t *) &B2Add, 1, 100);
	HAL_SPI_Transmit(&hspi1, (uint8_t *) &B3Add, 1, 100);

	//Sending the data byte
	HAL_SPI_Transmit(&hspi1, (uint8_t *) &writeDataByte, 1, 100);

	//printing into debug terminal
	StringLength=sprintf(txString,"Wrote %X in   SharedFM address %X%X%X%X\r\n",writeDataByte,B0Add,B1Add,B2Add,B3Add);
	  HAL_UART_Transmit(&debugPort, (uint8_t *) &txString, StringLength, 100);

	sharedChipDeSelect();
	HAL_Delay(20);

	return;
}

int read_4ByteAdd_LocalFM(uint32_t Addr)
{
	uint8_t readDataByte=0x00;

	uint8_t B0Add=((Addr>> 24) & 0xFF);		// 0x _ _ 00 00 00
	uint8_t B1Add=((Addr>> 16) & 0xFF);		// 0x 00 _ _ 00 00
	uint8_t B2Add=((Addr>> 8) & 0xFF);		// 0x 00 00 _ _ 00
	uint8_t B3Add=((Addr) & 0xFF);			// 0x 00 00 00 _ _

	//WRENABLE_LocalFM();
	localChipSelect();

	//Sending the read command
	HAL_SPI_Transmit(&hspi4, (uint8_t *) &READ_4ByteAdd, 1, 100);

	//Sending the address
	HAL_SPI_Transmit(&hspi4, (uint8_t *) &B0Add, 1, 100);
	HAL_SPI_Transmit(&hspi4, (uint8_t *) &B1Add, 1, 100);
	HAL_SPI_Transmit(&hspi4, (uint8_t *) &B2Add, 1, 100);
	HAL_SPI_Transmit(&hspi4, (uint8_t *) &B3Add, 1, 100);

	//Receiving the data byte
	HAL_SPI_Receive(&hspi4, (uint8_t *) &readDataByte, 1, 100);

	//printing into debug terminal
	StringLength=sprintf(txString,"read  %X from  LocalFM address %X%X%X%X\r\n",readDataByte,B0Add,B1Add,B2Add,B3Add);
	HAL_UART_Transmit(&debugPort, (uint8_t *) &txString, StringLength, 100);

	localChipDeSelect();
	//HAL_Delay(20);

	return readDataByte;
}

int read_4ByteAdd_SharedFM(uint32_t Addr)
{
	uint8_t readDataByte=0x00;

	uint8_t B0Add=((Addr>> 24) & 0xFF);		// 0x _ _ 00 00 00
	uint8_t B1Add=((Addr>> 16) & 0xFF);		// 0x 00 _ _ 00 00
	uint8_t B2Add=((Addr>> 8) & 0xFF);		// 0x 00 00 _ _ 00
	uint8_t B3Add=((Addr) & 0xFF);			// 0x 00 00 00 _ _

	//WRENABLE_SharedFM();
	sharedChipSelect();

	//Sending the write command
	HAL_SPI_Transmit(&hspi1, (uint8_t *) &READ_4ByteAdd, 1, 100);

	//Sending the address
	HAL_SPI_Transmit(&hspi1, (uint8_t *) &B0Add, 1, 100);
	HAL_SPI_Transmit(&hspi1, (uint8_t *) &B1Add, 1, 100);
	HAL_SPI_Transmit(&hspi1, (uint8_t *) &B2Add, 1, 100);
	HAL_SPI_Transmit(&hspi1, (uint8_t *) &B3Add, 1, 100);

	//Receiving the data byte
	HAL_SPI_Receive(&hspi1, (uint8_t *) &readDataByte, 1, 100);

	//printing into debug terminal
	StringLength=sprintf(txString,"read  %X from SharedFM address %X%X%X%X\r\n",readDataByte,B0Add,B1Add,B2Add,B3Add);
	HAL_UART_Transmit(&debugPort, (uint8_t *) &txString, StringLength, 100);

	sharedChipDeSelect();

	return readDataByte;
}

//void read_bulk_4ByteAdd_LocalFM(dev->fp, buff, nbyte );
//int read_bulk_4ByteAdd_LocalFM(uint32_t Addr, int bulk_size){

void read_bulk_4ByteAdd_LocalFM(uint32_t Addr, uint8_t* pointer, uint16_t bulk_size )
{
	uint8_t readDataByte=0x00;

	uint8_t B0Add=((Addr>> 24) & 0xFF);		// 0x _ _ 00 00 00
	uint8_t B1Add=((Addr>> 16) & 0xFF);		// 0x 00 _ _ 00 00
	uint8_t B2Add=((Addr>> 8) & 0xFF);		// 0x 00 00 _ _ 00
	uint8_t B3Add=((Addr) & 0xFF);			// 0x 00 00 00 _ _

	//WRENABLE_LocalFM();
	localChipSelect();

	//Sending the write command
	HAL_SPI_Transmit(&hspi4, (uint8_t *) &READ_4ByteAdd, 1, 100);

	//Sending the address
	HAL_SPI_Transmit(&hspi4, (uint8_t *) &B0Add, 1, 100);
	HAL_SPI_Transmit(&hspi4, (uint8_t *) &B1Add, 1, 100);
	HAL_SPI_Transmit(&hspi4, (uint8_t *) &B2Add, 1, 100);
	HAL_SPI_Transmit(&hspi4, (uint8_t *) &B3Add, 1, 100);

	for (int i=0; i<bulk_size; i++)
	{
		HAL_SPI_Receive(&hspi4, (uint8_t *) &readDataByte, 1, 100);
		*(pointer+i)=readDataByte;
	}

	localChipDeSelect();

	return readDataByte;
}

void read_bulk_4ByteAdd_SharedFM(uint32_t Addr, uint8_t* pointer, uint16_t bulk_size){

	uint8_t readDataByte=0x00;

	uint8_t B0Add=((Addr>> 24) & 0xFF);		// 0x _ _ 00 00 00
	uint8_t B1Add=((Addr>> 16) & 0xFF);		// 0x 00 _ _ 00 00
	uint8_t B2Add=((Addr>> 8) & 0xFF);		// 0x 00 00 _ _ 00
	uint8_t B3Add=((Addr) & 0xFF);			// 0x 00 00 00 _ _

	//WRENABLE_SharedFM();
	sharedChipSelect();

	//Sending the write command
	HAL_SPI_Transmit(&hspi1, (uint8_t *) &READ_4ByteAdd, 1, 100);

	//Sending the address
	HAL_SPI_Transmit(&hspi1, (uint8_t *) &B0Add, 1, 100);
	HAL_SPI_Transmit(&hspi1, (uint8_t *) &B1Add, 1, 100);
	HAL_SPI_Transmit(&hspi1, (uint8_t *) &B2Add, 1, 100);
	HAL_SPI_Transmit(&hspi1, (uint8_t *) &B3Add, 1, 100);

	//Receiving the data byte
	for (int i=0; i<bulk_size; i++)
	{
		HAL_SPI_Receive(&hspi1, (uint8_t *) &readDataByte, 1, 100);
		*(pointer+i)=readDataByte;
	}

	sharedChipDeSelect();

	return readDataByte;
}

void saveImage_LocalFM(uint32_t StartingAddr,uint8_t *imageHex)
{
	//for (i=0; i<10; ++i) {imageHex[i] = dummyImage01[i]; }

	StringLength=sprintf(txString,"\r\n");
	HAL_UART_Transmit(&debugPort, (uint8_t *) &txString, StringLength, 100);

	uint8_t imageByte=0xF0;
	uint8_t B0Add;
	uint8_t B1Add;
	uint8_t B2Add;
	uint8_t B3Add;
	int counter=256*200000;
	counter= 32767;
	//int pagesNum=sizeof(IMG)/counter+1;

	WRENABLE_LocalFM();
	//ReadSR();

	localChipSelect();

	//Sending the write command
	HAL_SPI_Transmit(&hspi4, (uint8_t *) &WRITE_4ByteAdd, 1, 100);

	//Sending the address
	B0Add=StartingAddr>> 24;
	B1Add=StartingAddr>> 16;
	B2Add=StartingAddr>> 8;
	B3Add=StartingAddr;
	HAL_SPI_Transmit(&hspi4, (uint8_t *) &B0Add, 1, 100);
	HAL_SPI_Transmit(&hspi4, (uint8_t *) &B1Add, 1, 100);
	HAL_SPI_Transmit(&hspi4, (uint8_t *) &B2Add, 1, 100);
	HAL_SPI_Transmit(&hspi4, (uint8_t *) &B3Add, 1, 100);

	//Sending the image bytes
	i=0;
	while (((imageHex[i] != 0xD9) || (imageHex[i-1] != 0xFF)) && (counter>0)) {

		//Sending the data byte
		HAL_SPI_Transmit(&hspi4, (uint8_t *) &imageHex[i], 1, 100);
		//HAL_Delay(5);

//		printing image byte in the serial terminal
		HAL_UART_Transmit(&huart1, (uint8_t *) &imageHex[i], 1, 100);

		if(i%16==0)
		StringLength=sprintf(txString,"\r\n%02X ",imageHex[i]);
		else
		StringLength=sprintf(txString,"%02X ",imageHex[i]);
		HAL_UART_Transmit(&debugPort, (uint8_t *) &txString, StringLength, 100);

		i++;
		counter--;

		if (i%256==0){
			HAL_Delay(100);
			localChipDeSelect();
			HAL_Delay(100);

			//StringLength=sprintf(txString,"\r\nNew page, i=%u \r\n",i);
			//HAL_UART_Transmit(&debugPort, (uint8_t *) &txString, StringLength, 100);

			WRENABLE_LocalFM();
			localChipSelect();

			//Sending the write command
			HAL_SPI_Transmit(&hspi4, (uint8_t *) &WRITE_4ByteAdd, 1, 100);

			//Sending the address
			StartingAddr=StartingAddr+256;
			B0Add=StartingAddr>> 24;
			B1Add=StartingAddr>> 16;
			B2Add=StartingAddr>> 8;
			B3Add=StartingAddr;

			HAL_SPI_Transmit(&hspi4, (uint8_t *) &B0Add, 1, 100);
			HAL_SPI_Transmit(&hspi4, (uint8_t *) &B1Add, 1, 100);
			HAL_SPI_Transmit(&hspi4, (uint8_t *) &B2Add, 1, 100);
			HAL_SPI_Transmit(&hspi4, (uint8_t *) &B3Add, 1, 100);
		}

	}

	//Write the last byte 0xD9
	HAL_SPI_Transmit(&hspi4, (uint8_t *) &imageHex[i], 1, 100);
//	if(i%25==0)
//	StringLength=sprintf(txString,"\r\n%02X ",imageHex[i]);
//	else
//	StringLength=sprintf(txString,"%02X ",imageHex[i]);
//	HAL_UART_Transmit(&debugPort, (uint8_t *) &txString, StringLength, 100);

	localChipDeSelect();

	StringLength=sprintf(txString,"\r\n\r\nImageSize:%u, saved size:%u\r\n",sizeof(imageHex),i+1);
	HAL_UART_Transmit(&debugPort, (uint8_t *) &txString, StringLength, 100);

	StringLength=sprintf(txString,"Image has been saved in LocalFM \r\n\r\n");
	HAL_UART_Transmit(&debugPort, (uint8_t *) &txString, StringLength, 100);

}

void saveImage_SharedFM(uint32_t StartingAddr,uint8_t *imageHex)
{
	//for (i=0; i<10; ++i) {imageHex[i] = dummyImage01[i]; }

	StringLength=sprintf(txString,"\r\n\r\n");
	HAL_UART_Transmit(&debugPort, (uint8_t *) &txString, StringLength, 100);

	uint8_t imageByte=0xF0;
	uint8_t B0Add;
	uint8_t B1Add;
	uint8_t B2Add;
	uint8_t B3Add;
	int counter=256*200000;
	//int pagesNum=sizeof(IMG)/counter+1;

	WRENABLE_SharedFM();
	//ReadSR();

	sharedChipSelect();

	//Sending the write command
	HAL_SPI_Transmit(&hspi1, (uint8_t *) &WRITE_4ByteAdd, 1, 100);

	//Sending the address
	B0Add=StartingAddr>> 24;
	B1Add=StartingAddr>> 16;
	B2Add=StartingAddr>> 8;
	B3Add=StartingAddr;
	HAL_SPI_Transmit(&hspi1, (uint8_t *) &B0Add, 1, 100);
	HAL_SPI_Transmit(&hspi1, (uint8_t *) &B1Add, 1, 100);
	HAL_SPI_Transmit(&hspi1, (uint8_t *) &B2Add, 1, 100);
	HAL_SPI_Transmit(&hspi1, (uint8_t *) &B3Add, 1, 100);

	//Sending the image bytes
	i=0;
	while (((imageHex[i] != 0xD9) || (imageHex[i-1] != 0xFF)) && (counter>0)) {

		//Sending the data byte
		HAL_SPI_Transmit(&hspi1, (uint8_t *) &imageHex[i], 1, 100);
		//HAL_Delay(5);

		//printing image byte in the serial terminal
		//HAL_UART_Transmit(&huart1, (uint8_t *) &imageHex[i], 1, 100);

//		if(i%16==0)
//		StringLength=sprintf(txString,"\r\n%02X ",imageHex[i]);
//		else
//		StringLength=sprintf(txString,"%02X ",imageHex[i]);
//		HAL_UART_Transmit(&debugPort, (uint8_t *) &txString, StringLength, 100);

		i++;
		counter--;

		if (i%256==0){
			HAL_Delay(100);
			sharedChipDeSelect();
			HAL_Delay(100);

			//StringLength=sprintf(txString,"\r\nNew page, i=%u \r\n",i);
			//HAL_UART_Transmit(&debugPort, (uint8_t *) &txString, StringLength, 100);

			WRENABLE_SharedFM();
			sharedChipSelect();

			//Sending the write command
			HAL_SPI_Transmit(&hspi1, (uint8_t *) &WRITE_4ByteAdd, 1, 100);

			//Sending the address
			StartingAddr=StartingAddr+256;
			B0Add=StartingAddr>> 24;
			B1Add=StartingAddr>> 16;
			B2Add=StartingAddr>> 8;
			B3Add=StartingAddr;

			HAL_SPI_Transmit(&hspi1, (uint8_t *) &B0Add, 1, 100);
			HAL_SPI_Transmit(&hspi1, (uint8_t *) &B1Add, 1, 100);
			HAL_SPI_Transmit(&hspi1, (uint8_t *) &B2Add, 1, 100);
			HAL_SPI_Transmit(&hspi1, (uint8_t *) &B3Add, 1, 100);
		}

	}

	//Write the last byte 0xD9
	HAL_SPI_Transmit(&hspi1, (uint8_t *) &imageHex[i], 1, 100);
//	if(i%25==0)
//	StringLength=sprintf(txString,"\r\n%02X ",imageHex[i]);
//	else
//	StringLength=sprintf(txString,"%02X ",imageHex[i]);
//	HAL_UART_Transmit(&debugPort, (uint8_t *) &txString, StringLength, 100);

	sharedChipDeSelect();

	StringLength=sprintf(txString,"\r\n\r\nImageSize:%u, saved size:%u\r\n",sizeof(Space),i+1);
	HAL_UART_Transmit(&debugPort, (uint8_t *) &txString, StringLength, 100);

	StringLength=sprintf(txString,"Image has been saved in SharedFM \r\n\r\n");
	HAL_UART_Transmit(&debugPort, (uint8_t *) &txString, StringLength, 100);

}

void readImage_LocalFM(uint32_t StartingAddr)
{

	uint8_t imageByte=0x00;
	uint8_t B0Add=StartingAddr>> 24;
	uint8_t B1Add=StartingAddr>> 16;
	uint8_t B2Add=StartingAddr>> 8;
	uint8_t B3Add=StartingAddr;

	B1Add=0;
	B2Add=0;
	B3Add=0;

	int counter=15;

	HAL_Delay(10);
	HAL_GPIO_WritePin(GPIOA, GPIO_PIN_4, GPIO_PIN_RESET);
	HAL_GPIO_WritePin(GPIOD, GPIO_PIN_12, GPIO_PIN_SET);

	HAL_Delay(1000);
	//Sending the read command
	HAL_SPI_Transmit(&hspi4, (uint8_t *) &READ_4ByteAdd, 1, 10);

	//Sending the address
	HAL_SPI_Transmit(&hspi4, (uint8_t *) &B0Add, 1, 10);
	HAL_SPI_Transmit(&hspi4, (uint8_t *) &B1Add, 1, 10);
	HAL_SPI_Transmit(&hspi4, (uint8_t *) &B2Add, 1, 10);
	HAL_SPI_Transmit(&hspi4, (uint8_t *) &B3Add, 1, 10);

	//HAL_UART_Transmit(&huart2, (uint8_t *) &imageByte, 1, 10);

	while (imageByte != 0xD9 && counter>0){

		//Receiving image bytes
		HAL_SPI_Receive(&hspi4, (uint8_t *) &imageByte, 1, 10);
		//HAL_SPI_TransmitReceive(&hspi4, (uint8_t *) &imageByte, (uint8_t *) &imageByte, 1,10);

		//printing image byte in the serial terminal
		HAL_UART_Transmit(&huart1, (uint8_t *) &imageByte, 1, 10);
		counter--;
	}

	HAL_UART_Transmit(&huart1, "b", 1, 10);
	HAL_UART_Transmit(&huart1, "b", 1, 10);
	HAL_UART_Transmit(&huart1, "b", 1, 10);
	HAL_UART_Transmit(&huart1, "\n", 1, 10);

	HAL_Delay(10);
	HAL_GPIO_WritePin(GPIOD, GPIO_PIN_12, GPIO_PIN_RESET);
	HAL_GPIO_WritePin(GPIOA, GPIO_PIN_4, GPIO_PIN_SET);
	HAL_Delay(10);

}

int display_bulk_4ByteAdd_LocalFM(uint32_t Addr, int bulk_size){

	uint8_t readDataByte=0x00;
	uint8_t B0Add=Addr>> 24;
	uint8_t B1Add=Addr>> 16;
	uint8_t B2Add=Addr>> 8;
	uint8_t B3Add=Addr;

	WRENABLE_LocalFM();
	localChipSelect();

	//Sending the write command
	HAL_SPI_Transmit(&hspi4, (uint8_t *) &READ_4ByteAdd, 1, 100);

	//Sending the address
	HAL_SPI_Transmit(&hspi4, (uint8_t *) &B0Add, 1, 100);
	HAL_SPI_Transmit(&hspi4, (uint8_t *) &B1Add, 1, 100);
	HAL_SPI_Transmit(&hspi4, (uint8_t *) &B2Add, 1, 100);
	HAL_SPI_Transmit(&hspi4, (uint8_t *) &B3Add, 1, 100);
	//Receiving the data byte

	for (int i=0; i<bulk_size;++i)
	{
		HAL_SPI_Receive(&hspi4, (uint8_t *) &readDataByte, 1, 100);

		//printing into debug terminal
		if(i%16==0)
			StringLength=sprintf(txString,"\r\n%02X ",readDataByte);
		else
			StringLength=sprintf(txString,"%02X ",readDataByte);

		HAL_UART_Transmit(&debugPort, (uint8_t *) &txString, StringLength, 100);
	}

	localChipDeSelect();

	return readDataByte;
}

int display_bulk_4ByteAdd_SharedFM(uint32_t Addr, int bulk_size){

	uint8_t readDataByte=0x00;
	uint8_t B0Add=Addr>> 24;
	uint8_t B1Add=Addr>> 16;
	uint8_t B2Add=Addr>> 8;
	uint8_t B3Add=Addr;

	WRENABLE_SharedFM();
	sharedChipSelect();

	//Sending the write command
	HAL_SPI_Transmit(&hspi1, (uint8_t *) &READ_4ByteAdd, 1, 100);

	//Sending the address
	HAL_SPI_Transmit(&hspi1, (uint8_t *) &B0Add, 1, 100);
	HAL_SPI_Transmit(&hspi1, (uint8_t *) &B1Add, 1, 100);
	HAL_SPI_Transmit(&hspi1, (uint8_t *) &B2Add, 1, 100);
	HAL_SPI_Transmit(&hspi1, (uint8_t *) &B3Add, 1, 100);

	//Receiving the data byte
	for (int i=0; i<bulk_size;++i)
	{
		HAL_SPI_Receive(&hspi1, (uint8_t *) &readDataByte, 1, 100);

		//printing into debug terminal
		if(i%16==0)
				StringLength=sprintf(txString,"\r\n%02X ",readDataByte);
		else
			StringLength=sprintf(txString,"%02X ",readDataByte);

		HAL_UART_Transmit(&debugPort, (uint8_t *) &txString, StringLength, 100);
	}

	sharedChipDeSelect();

	return readDataByte;
}

/* ICU Image Predicting Functions */
/*
 * Arguments    : void
 * Return Type  : double
 */

static void main_dataconverter(double Umat[14688], uint8_t* image, double imgdat[35])
{

  /* Initialize function 'dataconverter' input arguments. */
  /* Initialize function input argument 'rawimage'. */
  /* Initialize function input argument 'U'. */
  /* Call the entry-point 'dataconverter'. */

  dataconverter(image, Umat, imgdat);
}

static void rgb2gray_uint8_T(uint8_t* Img, int channels, int width, int height, int compression, uint8_t result[76800])
{
	int idx0;
	int idx1;
	int output_size;
	int divisor = pow(2, compression);
	int new_width = (width/divisor);
	int new_height = (height/divisor);

	output_size = new_width * new_height;

	StringLength=sprintf(txString,"\r\nThe size of the grayscale array is %u \r\n", output_size);
	HAL_UART_Transmit(&debugPort, (uint8_t *) &txString, StringLength, 100);

	/* Loop over the array to initialize each element. */
	for (idx0 = 0; idx0 < new_width; idx0++) {
		for (idx1 = 0; idx1 < new_height; idx1++) {
			result[idx0*new_height+idx1] = 0.3*Img[idx0*new_height*3+idx1*3] + 0.59*Img[idx0*new_height*3+idx1*3+1] + 0.11*Img[idx0*new_height*3+idx1*3+2];
		}
	}

	for (int i=0; i<output_size;++i)
	{
		if(i%16==0)
				StringLength=sprintf(txString,"\r\n%02X ", result[i]);
		else
			StringLength=sprintf(txString,"%02X ", result[i]);

		HAL_UART_Transmit(&debugPort, (uint8_t *) &txString, StringLength, 100);
	}

}

static void prepocess(uint8_t* Img, float result[19200*2])
{
	uint8_t result_pre[19200*2];

	for (int i; i<19200; ++i)
	{
		result_pre[i] = *(Img + i);
		result[i] = ((float)result_pre[i]) / 255;
	}

//	for (int i=0; i<19200;++i)
//	{
//		if(i%16==0)
//				StringLength=sprintf(txString,"\r\n%02X ", result_pre[i]);
//		else
//			StringLength=sprintf(txString,"%02X ", result_pre[i]);
//
//		HAL_UART_Transmit(&debugPort, (uint8_t *) &txString, StringLength, 100);
//	}
}

/* USER CODE END 4 */

void Error_Handler(void)
{
}
